VERSION ""

NS_ :

BS_:

BU_: ADSP CH ChassisBus DIPF DIPR ETH FC GTW GTWU HVI HVS ODIN PARTY PartyBus Receiver SDCV SUI UI UIS VEH VIRT VITALS VehicleBus X

BO_ 1013 ID3F5VCFRONT_lighting: 8 VehicleBus
 SG_ VCFRONT_DRLLeftStatus : 36|2@1+ (1,0) [0|3] ""  Receiver
 SG_ VCFRONT_DRLRightStatus : 38|2@1+ (1,0) [0|3] ""  Receiver
 SG_ VCFRONT_ambientLightingBrightnes : 8|8@1+ (0.5,0) [0|127] "%"  Receiver
 SG_ VCFRONT_approachLightingRequest : 25|1@1+ (1,0) [0|1] ""  Receiver
 SG_ VCFRONT_courtesyLightingRequest : 24|1@1+ (1,0) [0|1] ""  Receiver
 SG_ VCFRONT_fogLeftStatus : 40|2@1+ (1,0) [0|3] ""  Receiver
 SG_ VCFRONT_fogRightStatus : 42|2@1+ (1,0) [0|3] ""  Receiver
 SG_ VCFRONT_hazardLightRequest : 4|4@1+ (1,0) [0|8] ""  Receiver
 SG_ VCFRONT_hazardSwitchBacklight : 27|1@1+ (1,0) [0|1] ""  Receiver
 SG_ VCFRONT_highBeamLeftStatus : 32|2@1+ (1,0) [0|3] ""  Receiver
 SG_ VCFRONT_highBeamRightStatus : 34|2@1+ (1,0) [0|3] ""  Receiver
 SG_ VCFRONT_highBeamSwitchActive : 58|1@1+ (1,0) [0|1] ""  Receiver
 SG_ VCFRONT_indicatorLeftRequest : 0|2@1+ (1,0) [0|2] ""  Receiver
 SG_ VCFRONT_indicatorRightRequest : 2|2@1+ (1,0) [0|2] ""  Receiver
 SG_ VCFRONT_lowBeamLeftStatus : 28|2@1+ (1,0) [0|3] ""  Receiver
 SG_ VCFRONT_lowBeamRightStatus : 30|2@1+ (1,0) [0|3] ""  Receiver
 SG_ VCFRONT_lowBeamsCalibrated : 62|1@1+ (1,0) [0|1] ""  Receiver
 SG_ VCFRONT_lowBeamsOnForDRL : 61|1@1+ (1,0) [0|1] ""  Receiver
 SG_ VCFRONT_parkLeftStatus : 54|2@1+ (1,0) [0|3] ""  Receiver
 SG_ VCFRONT_parkRightStatus : 56|2@1+ (1,0) [0|3] ""  Receiver
 SG_ VCFRONT_seeYouHomeLightingReq : 26|1@1+ (1,0) [0|1] ""  Receiver
 SG_ VCFRONT_sideMarkersStatus : 44|2@1+ (1,0) [0|3] ""  Receiver
 SG_ VCFRONT_sideRepeaterLeftStatus : 46|2@1+ (1,0) [0|3] ""  Receiver
 SG_ VCFRONT_sideRepeaterRightStatus : 48|2@1+ (1,0) [0|3] ""  Receiver
 SG_ VCFRONT_simLatchingStalk : 59|2@1+ (1,0) [0|3] ""  Receiver
 SG_ VCFRONT_switchLightingBrightness : 16|8@1+ (0.5,0) [0|127] "%"  Receiver
 SG_ VCFRONT_turnSignalLeftStatus : 50|2@1+ (1,0) [0|3] ""  Receiver
 SG_ VCFRONT_turnSignalRightStatus : 52|2@1+ (1,0) [0|3] ""  Receiver

BO_ 1014 VCFRONT_lightStatus: 5 GTW
 SG_ VCFRONT_turnSignalLeftStatus : 22|2@1+ (1,0) [0|3] "" ODIN,UI
 SG_ VCFRONT_turnSignalRightStatus : 24|2@1+ (1,0) [0|3] "" ODIN,UI

BO_ 1016 ID3F8UI_driverAssistControl: 8 ChassisBus
 SG_ UI_accFollowDistanceSetting : 45|3@1+ (1,0) [0|7] ""  Receiver
 SG_ UI_adaptiveSetSpeedEnable : 39|1@1+ (1,0) [0|1] ""  Receiver
 SG_ UI_alcOffHighwayEnable : 56|1@1+ (1,0) [0|1] ""  Receiver
 SG_ UI_autoSummonEnable : 10|1@1+ (1,0) [0|1] ""  Receiver
 SG_ UI_autopilotControlRequest : 0|1@1+ (1,0) [0|1] ""  Receiver
 SG_ UI_coastToCoast : 9|1@1+ (1,0) [0|1] ""  Receiver
 SG_ UI_curvSpeedAdaptDisable : 4|1@1+ (1,0) [0|1] ""  Receiver
 SG_ UI_curvatureDatabaseOnly : 22|1@1+ (1,0) [0|1] ""  Receiver
 SG_ UI_dasDeveloper : 5|1@1+ (1,0) [0|1] ""  Receiver
 SG_ UI_driveOnMapsEnable : 13|1@1+ (1,0) [0|1] ""  Receiver
 SG_ UI_drivingSide : 40|2@1+ (1,0) [0|2] ""  Receiver
 SG_ UI_enableBrakeLightPulse : 63|1@1+ (1,0) [0|1] ""  Receiver
 SG_ UI_enableClipTelemetry : 42|1@1+ (1,0) [0|1] ""  Receiver
 SG_ UI_enableRoadSegmentTelemetry : 44|1@1+ (1,0) [0|1] ""  Receiver
 SG_ UI_enableTripTelemetry : 43|1@1+ (1,0) [0|1] ""  Receiver
 SG_ UI_enableVinAssociation : 6|1@1+ (1,0) [0|1] ""  Receiver
 SG_ UI_enableVisionOnlyStops : 60|1@1+ (1,0) [0|1] ""  Receiver
 SG_ UI_exceptionListEnable : 11|1@1+ (1,0) [0|1] ""  Receiver
 SG_ UI_followNavRouteEnable : 49|1@1+ (1,0) [0|1] ""  Receiver
 SG_ UI_fuseHPPDisable : 17|1@1+ (1,0) [0|1] ""  Receiver
 SG_ UI_fuseLanesDisable : 16|1@1+ (1,0) [0|1] ""  Receiver
 SG_ UI_fuseVehiclesDisable : 18|1@1+ (1,0) [0|1] ""  Receiver
 SG_ UI_handsOnRequirementDisable : 14|1@1+ (1,0) [0|1] ""  Receiver
 SG_ UI_hasDriveOnNav : 48|1@1+ (1,0) [0|1] ""  Receiver
 SG_ UI_lssElkEnabled : 23|1@1+ (1,0) [0|1] ""  Receiver
 SG_ UI_lssLdwEnabled : 8|1@1+ (1,0) [0|1] ""  Receiver
 SG_ UI_lssLkaEnabled : 7|1@1+ (1,0) [0|1] ""  Receiver
 SG_ UI_roadCheckDisable : 12|1@1+ (1,0) [0|1] ""  Receiver
 SG_ UI_selfParkRequest : 28|4@1+ (1,0) [0|15] ""  Receiver
 SG_ UI_smartSummonType : 58|2@1+ (1,0) [0|2] ""  Receiver
 SG_ UI_source3D : 61|2@1+ (1,0) [0|2] ""  Receiver
 SG_ UI_summonEntryType : 26|2@1+ (1,0) [0|3] ""  Receiver
 SG_ UI_summonExitType : 24|2@1+ (1,0) [0|3] ""  Receiver
 SG_ UI_summonHeartbeat : 2|2@1+ (1,0) [0|3] ""  Receiver
 SG_ UI_summonReverseDist : 32|6@1+ (1,0) [0|63] ""  Receiver
 SG_ UI_ulcBlindSpotConfig : 52|2@1+ (1,0) [0|2] ""  Receiver
 SG_ UI_ulcOffHighway : 15|1@1+ (1,0) [0|1] ""  Receiver
 SG_ UI_ulcSpeedConfig : 50|2@1+ (1,0) [0|3] ""  Receiver
 SG_ UI_ulcStalkConfirm : 1|1@1+ (1,0) [0|1] ""  Receiver
 SG_ UI_undertakeAssistEnable : 38|1@1+ (1,0) [0|1] ""  Receiver
 SG_ UI_validationLoop : 57|1@1+ (1,0) [0|1] ""  Receiver
 SG_ UI_visionSpeedType : 20|2@1+ (1,0) [0|3] ""  Receiver

BO_ 1017 VCSEC_alertMatrix: 8 VEH
 SG_ VCSEC_matrixIndex M: 0|4@1+ (1,0) [0|0] "" X
 SG_ VCSEC_a001_WatchdogReset m0: 4|1@1+ (1,0) [0|0] "" X
 SG_ VCSEC_a002_PowerLossReset m0: 5|1@1+ (1,0) [0|0] "" X
 SG_ VCSEC_a003_SWAssertion m0: 6|1@1+ (1,0) [0|0] "" X
 SG_ VCSEC_a010_ExtSupplyVoltError m0: 13|1@1+ (1,0) [0|0] "" X
 SG_ VCSEC_a012_CPUReset m0: 15|1@1+ (1,0) [0|0] "" X
 SG_ VCSEC_a013_AlertManagerFault m0: 16|1@1+ (1,0) [0|0] "" X
 SG_ VCSEC_a015_NVMMAlert m0: 18|1@1+ (1,0) [0|0] "" X
 SG_ VCSEC_a021_TaskSchedulerError m0: 24|1@1+ (1,0) [0|0] "" X
 SG_ VCSEC_a022_TaskInitError m0: 25|1@1+ (1,0) [0|0] "" X
 SG_ VCSEC_a031_UDSActive m0: 34|1@1+ (1,0) [0|0] "" X
 SG_ VCSEC_a041_HighCPULoad m0: 44|1@1+ (1,0) [0|0] "" X
 SG_ VCSEC_a042_HighStackUsage m0: 45|1@1+ (1,0) [0|0] "" X
 SG_ VCSEC_a043_Task1msError m0: 46|1@1+ (1,0) [0|0] "" X
 SG_ VCSEC_a044_Task10msError m0: 47|1@1+ (1,0) [0|0] "" X
 SG_ VCSEC_a045_Task100msError m0: 48|1@1+ (1,0) [0|0] "" X
 SG_ VCSEC_a046_Task1000msError m0: 49|1@1+ (1,0) [0|0] "" X
 SG_ VCSEC_a059_inputResistanceHigh m0: 62|1@1+ (1,0) [0|0] "" X
 SG_ VCSEC_a060_engineeringBuild m0: 63|1@1+ (1,0) [0|0] "" X
 SG_ VCSEC_a061_XCPConnected m1: 4|1@1+ (1,0) [0|0] "" X
 SG_ VCSEC_a062_XCPWasConnected m1: 5|1@1+ (1,0) [0|0] "" X
 SG_ VCSEC_a063_SwitchFault m1: 6|1@1+ (1,0) [0|0] "" X
 SG_ VCSEC_a064_busSleepReqTimeout m1: 7|1@1+ (1,0) [0|0] "" X
 SG_ VCSEC_a097_CMP_MIA m1: 40|1@1+ (1,0) [0|0] "" X
 SG_ VCSEC_a098_DI_THERMAL_MIA m1: 41|1@1+ (1,0) [0|0] "" X
 SG_ VCSEC_a099_PARK_MIA m1: 42|1@1+ (1,0) [0|0] "" X
 SG_ VCSEC_a100_CANbus_MIA m1: 43|1@1+ (1,0) [0|0] "" X
 SG_ VCSEC_a101_PM_MIA m1: 44|1@1+ (1,0) [0|0] "" X
 SG_ VCSEC_a102_PTC_MIA m1: 45|1@1+ (1,0) [0|0] "" X
 SG_ VCSEC_a103_CP_MIA m1: 46|1@1+ (1,0) [0|0] "" X
 SG_ VCSEC_a104_DAS_MIA m1: 47|1@1+ (1,0) [0|0] "" X
 SG_ VCSEC_a105_TAS_MIA m1: 48|1@1+ (1,0) [0|0] "" X
 SG_ VCSEC_a106_PCS_MIA m1: 49|1@1+ (1,0) [0|0] "" X
 SG_ VCSEC_a107_BMS_MIA m1: 50|1@1+ (1,0) [0|0] "" X
 SG_ VCSEC_a108_DIS_MIA m1: 51|1@1+ (1,0) [0|0] "" X
 SG_ VCSEC_a109_RCM_MIA m1: 52|1@1+ (1,0) [0|0] "" X
 SG_ VCSEC_a110_GTW_MIA m1: 53|1@1+ (1,0) [0|0] "" X
 SG_ VCSEC_a111_EPBR_MIA m1: 54|1@1+ (1,0) [0|0] "" X
 SG_ VCSEC_a112_EPBL_MIA m1: 55|1@1+ (1,0) [0|0] "" X
 SG_ VCSEC_a113_UI_MIA m1: 56|1@1+ (1,0) [0|0] "" X
 SG_ VCSEC_a114_ESP_MIA m1: 57|1@1+ (1,0) [0|0] "" X
 SG_ VCSEC_a115_VCSEC_MIA m1: 58|1@1+ (1,0) [0|0] "" X
 SG_ VCSEC_a116_VCRIGHT_MIA m1: 59|1@1+ (1,0) [0|0] "" X
 SG_ VCSEC_a117_VCLEFT_MIA m1: 60|1@1+ (1,0) [0|0] "" X
 SG_ VCSEC_a118_VCFRONT_MIA m1: 61|1@1+ (1,0) [0|0] "" X
 SG_ VCSEC_a119_SCCM_MIA m1: 62|1@1+ (1,0) [0|0] "" X
 SG_ VCSEC_a120_DI_DRIVE_MIA m1: 63|1@1+ (1,0) [0|0] "" X
 SG_ VCSEC_a133_alarmTriggered m2: 16|1@1+ (1,0) [0|0] "" X
 SG_ VCSEC_a134_badCertificate m2: 17|1@1+ (1,0) [0|0] "" X
 SG_ VCSEC_a135_centerEndpointMIA m2: 18|1@1+ (1,0) [0|0] "" X
 SG_ VCSEC_a136_leftEndpointMIA m2: 19|1@1+ (1,0) [0|0] "" X
 SG_ VCSEC_a137_rightEndpointMIA m2: 20|1@1+ (1,0) [0|0] "" X
 SG_ VCSEC_a138_rearEndpointMIA m2: 21|1@1+ (1,0) [0|0] "" X
 SG_ VCSEC_a140_nfcAuthentication m2: 23|1@1+ (1,0) [0|0] "" X
 SG_ VCSEC_a141_tooFewKeysOnWhitelist m2: 24|1@1+ (1,0) [0|0] "" X
 SG_ VCSEC_a142_bleGattAlertC m2: 25|1@1+ (1,0) [0|0] "" X
 SG_ VCSEC_a143_bleGattAlertL m2: 26|1@1+ (1,0) [0|0] "" X
 SG_ VCSEC_a144_bleGattAlertR m2: 27|1@1+ (1,0) [0|0] "" X
 SG_ VCSEC_a145_bleGattAlertRe m2: 28|1@1+ (1,0) [0|0] "" X
 SG_ VCSEC_a147_protobufRXTimeout m2: 30|1@1+ (1,0) [0|0] "" X
 SG_ VCSEC_a148_keyWhitelistFull m2: 31|1@1+ (1,0) [0|0] "" X
 SG_ VCSEC_a149_attrsWentMissingL m2: 32|1@1+ (1,0) [0|0] "" X
 SG_ VCSEC_a150_attrsWentMissingR m2: 33|1@1+ (1,0) [0|0] "" X
 SG_ VCSEC_a151_attrsWentMissingRe m2: 34|1@1+ (1,0) [0|0] "" X
 SG_ VCSEC_a153_srvcCmdTimeoutC m2: 36|1@1+ (1,0) [0|0] "" X
 SG_ VCSEC_a154_srvcCmdTimeoutL m2: 37|1@1+ (1,0) [0|0] "" X
 SG_ VCSEC_a155_srvcCmdTimeoutR m2: 38|1@1+ (1,0) [0|0] "" X
 SG_ VCSEC_a156_srvcCmdTimeoutRe m2: 39|1@1+ (1,0) [0|0] "" X
 SG_ VCSEC_a158_hciFaultC m2: 41|1@1+ (1,0) [0|0] "" X
 SG_ VCSEC_a159_hciFaultL m2: 42|1@1+ (1,0) [0|0] "" X
 SG_ VCSEC_a161_hciFaultR m2: 44|1@1+ (1,0) [0|0] "" X
 SG_ VCSEC_a162_hciFaultRe m2: 45|1@1+ (1,0) [0|0] "" X
 SG_ VCSEC_a164_attrsWentMissingC m2: 47|1@1+ (1,0) [0|0] "" X
 SG_ VCSEC_a165_ephemeralKeyGenerated m2: 48|1@1+ (1,0) [0|0] "" X
 SG_ VCSEC_a166_BLECenterPowerCycled m2: 49|1@1+ (1,0) [0|0] "" X
 SG_ VCSEC_a167_BLECenterSoftReset m2: 50|1@1+ (1,0) [0|0] "" X
 SG_ VCSEC_a168_BLELeftSoftReset m2: 51|1@1+ (1,0) [0|0] "" X
 SG_ VCSEC_a169_BLERightSoftReset m2: 52|1@1+ (1,0) [0|0] "" X
 SG_ VCSEC_a170_BLERearSoftReset m2: 53|1@1+ (1,0) [0|0] "" X
 SG_ VCSEC_a172_BLEUnexpectedResetC m2: 55|1@1+ (1,0) [0|0] "" X
 SG_ VCSEC_a173_BLEUnexpectedResetL m2: 56|1@1+ (1,0) [0|0] "" X
 SG_ VCSEC_a174_BLEUnexpectedResetRi m2: 57|1@1+ (1,0) [0|0] "" X
 SG_ VCSEC_a175_BLEUnexpectedResetRe m2: 58|1@1+ (1,0) [0|0] "" X
 SG_ VCSEC_a177_whitelistAddedKey m2: 60|1@1+ (1,0) [0|0] "" X
 SG_ VCSEC_a178_whitelistRemovedKey m2: 61|1@1+ (1,0) [0|0] "" X
 SG_ VCSEC_a179_wlistAddedPermission m2: 62|1@1+ (1,0) [0|0] "" X
 SG_ VCSEC_a180_wlistRemovedPermission m2: 63|1@1+ (1,0) [0|0] "" X
 SG_ VCSEC_a181_signedMessageFault m3: 4|1@1+ (1,0) [0|0] "" X
 SG_ VCSEC_a182_cryptoHighStackUsage m3: 5|1@1+ (1,0) [0|0] "" X
 SG_ VCSEC_a183_centerEndpointRFMia m3: 6|1@1+ (1,0) [0|0] "" X
 SG_ VCSEC_a184_driverEndpointRFMia m3: 7|1@1+ (1,0) [0|0] "" X
 SG_ VCSEC_a185_passengerEndpointRFMia m3: 8|1@1+ (1,0) [0|0] "" X
 SG_ VCSEC_a186_rearEndpointRFMia m3: 9|1@1+ (1,0) [0|0] "" X
 SG_ VCSEC_a187_badConnectionDropped m3: 10|1@1+ (1,0) [0|0] "" X
 SG_ VCSEC_a188_protobufDecodeError m3: 11|1@1+ (1,0) [0|0] "" X
 SG_ VCSEC_a189_protoExpLengthTooLarge m3: 12|1@1+ (1,0) [0|0] "" X
 SG_ VCSEC_a190_protoTooManyBytes m3: 13|1@1+ (1,0) [0|0] "" X
 SG_ VCSEC_a191_macIDWlistingFailedC m3: 14|1@1+ (1,0) [0|0] "" X
 SG_ VCSEC_a192_macIDWlistingFailedL m3: 15|1@1+ (1,0) [0|0] "" X
 SG_ VCSEC_a193_macIDWlistingFailedRi m3: 16|1@1+ (1,0) [0|0] "" X
 SG_ VCSEC_a194_macIDWlistingFailedRe m3: 17|1@1+ (1,0) [0|0] "" X
 SG_ VCSEC_a195_keyMissingInDrive m3: 18|1@1+ (1,0) [0|0] "" X
 SG_ VCSEC_a196_protobufTXTimeout m3: 19|1@1+ (1,0) [0|0] "" X
 SG_ VCSEC_a197_indicationFault m3: 20|1@1+ (1,0) [0|0] "" X
 SG_ VCSEC_a198_BPillarNFCReaderMIA m3: 21|1@1+ (1,0) [0|0] "" X
 SG_ VCSEC_a199_CenterNFCReaderMIA m3: 22|1@1+ (1,0) [0|0] "" X
 SG_ VCSEC_a200_centerEndpointLostComm m3: 23|1@1+ (1,0) [0|0] "" X
 SG_ VCSEC_a201_leftEndpointLostComm m3: 24|1@1+ (1,0) [0|0] "" X
 SG_ VCSEC_a202_rightEndpointLostComm m3: 25|1@1+ (1,0) [0|0] "" X
 SG_ VCSEC_a203_rearEndpointLostComm m3: 26|1@1+ (1,0) [0|0] "" X
 SG_ VCSEC_a204_SharedSecretsWritten m3: 27|1@1+ (1,0) [0|0] "" X
 SG_ VCSEC_a205_MTUUpdateNotConfirmed m3: 28|1@1+ (1,0) [0|0] "" X
 SG_ VCSEC_a206_BLELeftAssertFailure m3: 29|1@1+ (1,0) [0|0] "" X
 SG_ VCSEC_a207_BLERightAssertFailure m3: 30|1@1+ (1,0) [0|0] "" X
 SG_ VCSEC_a208_BLERearAssertFailure m3: 31|1@1+ (1,0) [0|0] "" X
 SG_ VCSEC_a209_BLECenterAssertFailure m3: 32|1@1+ (1,0) [0|0] "" X

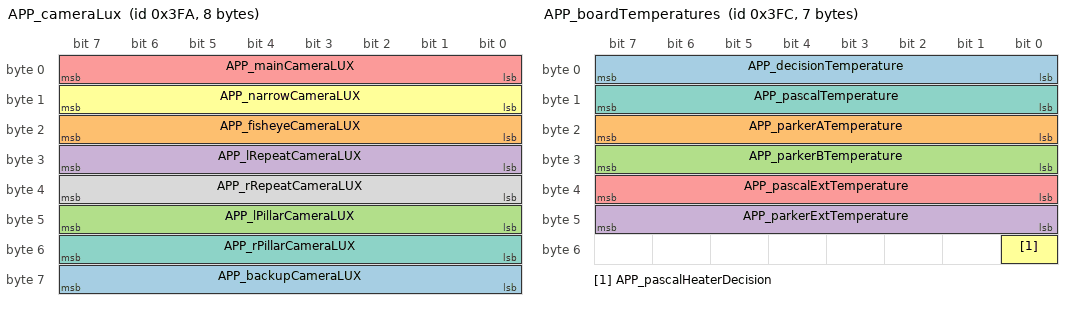
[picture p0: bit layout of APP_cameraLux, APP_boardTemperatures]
BO_ 1018 APP_cameraLux: 8 CH
 SG_ APP_backupCameraLUX: 56|8@1+ (50,0) [0|0] "lux" X
 SG_ APP_fisheyeCameraLUX: 16|8@1+ (50,0) [0|0] "lux" X
 SG_ APP_lPillarCameraLUX: 40|8@1+ (50,0) [0|0] "lux" X
 SG_ APP_lRepeatCameraLUX: 24|8@1+ (50,0) [0|0] "lux" X
 SG_ APP_mainCameraLUX: 0|8@1+ (50,0) [0|0] "lux" X
 SG_ APP_narrowCameraLUX: 8|8@1+ (50,0) [0|0] "lux" X
 SG_ APP_rPillarCameraLUX: 48|8@1+ (50,0) [0|0] "lux" X
 SG_ APP_rRepeatCameraLUX: 32|8@1+ (50,0) [0|0] "lux" X

BO_ 1020 APP_boardTemperatures: 7 CH
 SG_ APP_decisionTemperature: 0|8@1+ (1,-128) [0|0] "C" X
 SG_ APP_parkerATemperature: 16|8@1+ (1,-128) [0|0] "C" X
 SG_ APP_parkerBTemperature: 24|8@1+ (1,-128) [0|0] "C" X
 SG_ APP_parkerExtTemperature: 40|8@1+ (1,-128) [0|0] "C" X
 SG_ APP_pascalExtTemperature: 32|8@1+ (1,-128) [0|0] "C" X
 SG_ APP_pascalHeaterDecision: 48|1@1+ (1,0) [0|0] "" X
 SG_ APP_pascalTemperature: 8|8@1+ (1,-128) [0|0] "C" X

BO_ 1021 ID3FDUI_autopilotControl: 8 ChassisBus
 SG_ UI_autopilotControlIndex M : 0|3@1+ (1,0) [0|7] ""  Receiver
 SG_ UI_apmv3Branch m1 : 40|3@1+ (1,0) [0|5] ""  Receiver
 SG_ UI_applyEceR79 m1 : 19|1@1+ (1,0) [0|1] ""  Receiver
 SG_ UI_blindspotDistance m0 : 15|3@1+ (1,0) [0|5] ""  Receiver
 SG_ UI_blindspotMinSpeed m0 : 11|4@1+ (1,0) [0|10] ""  Receiver
 SG_ UI_blindspotTTC m0 : 18|3@1+ (1,0) [0|7] ""  Receiver
 SG_ UI_disableBackup m1 : 30|1@1+ (1,0) [0|1] ""  Receiver
 SG_ UI_disableFisheye m1 : 25|1@1+ (1,0) [0|1] ""  Receiver
 SG_ UI_disableLeftPillar m1 : 26|1@1+ (1,0) [0|1] ""  Receiver
 SG_ UI_disableLeftRepeater m1 : 28|1@1+ (1,0) [0|1] ""  Receiver
 SG_ UI_disableMain m1 : 23|1@1+ (1,0) [0|1] ""  Receiver
 SG_ UI_disableNarrow m1 : 24|1@1+ (1,0) [0|1] ""  Receiver
 SG_ UI_disableRadar m1 : 31|1@1+ (1,0) [0|1] ""  Receiver
 SG_ UI_disableRightPillar m1 : 27|1@1+ (1,0) [0|1] ""  Receiver
 SG_ UI_disableRightRepeater m1 : 29|1@1+ (1,0) [0|1] ""  Receiver
 SG_ UI_donAlcProgGoreAbortThres m0 : 29|4@1+ (1,0) [0|9] ""  Receiver
 SG_ UI_donDisableAutoWiperDuration m0 : 4|3@1+ (1,0) [0|6] ""  Receiver
 SG_ UI_donDisableCutin m0 : 24|1@1+ (1,0) [0|1] ""  Receiver
 SG_ UI_donDisableOnAutoWiperSpeed m0 : 7|4@1+ (1,0) [0|15] ""  Receiver
 SG_ UI_donMinGoreWidthForAbortMap m0 : 25|4@1+ (1,0) [0|11] ""  Receiver
 SG_ UI_donMinGoreWidthForAbortNotMap m0 : 33|4@1+ (1,0) [0|11] ""  Receiver
 SG_ UI_donStopEndOfRampBuffer m0 : 21|3@1+ (1,0) [0|4] ""  Receiver
 SG_ UI_driverMonitorConfirmation m1 : 17|1@1+ (1,0) [0|1] ""  Receiver
 SG_ UI_enableAutopilotStopWarning m1 : 44|1@1+ (1,0) [0|1] ""  Receiver
 SG_ UI_enableCabinCamera m1 : 43|1@1+ (1,0) [0|1] ""  Receiver
 SG_ UI_enableCabinCameraTelemetry m1 : 48|1@1+ (1,0) [0|1] ""  Receiver
 SG_ UI_enableMapStops m1 : 20|1@1+ (1,0) [0|1] ""  Receiver
 SG_ UI_factorySummonEnable m1 : 39|1@1+ (1,0) [0|1] ""  Receiver
 SG_ UI_fsdStopsControlEnabled m0 : 38|1@1+ (1,0) [0|1] ""  Receiver
 SG_ UI_fsdVisualizationEnabled m0 : 37|1@1+ (1,0) [0|1] ""  Receiver
 SG_ UI_hardCoreSummon m1 : 47|1@1+ (1,0) [0|1] ""  Receiver
 SG_ UI_homelinkNearby m0 : 45|1@1+ (1,0) [0|1] ""  Receiver
 SG_ UI_hovEnabled m0 : 3|1@1+ (1,0) [0|1] ""  Receiver
 SG_ UI_noStalkConfirmAlertChime m1 : 37|1@1+ (1,0) [0|1] ""  Receiver
 SG_ UI_noStalkConfirmAlertHaptic m1 : 32|1@1+ (1,0) [0|1] ""  Receiver
 SG_ UI_showLaneGraph m1 : 45|1@1+ (1,0) [0|1] ""  Receiver
 SG_ UI_showTrackLabels m1 : 46|1@1+ (1,0) [0|1] ""  Receiver
 SG_ UI_ulcSnooze m1 : 36|1@1+ (1,0) [0|1] ""  Receiver

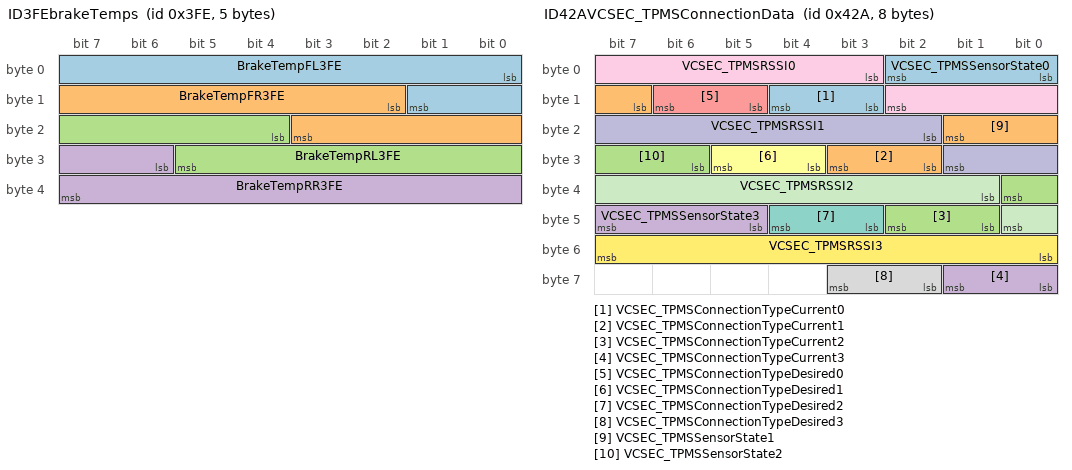
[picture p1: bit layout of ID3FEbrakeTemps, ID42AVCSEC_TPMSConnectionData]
BO_ 1022 ID3FEbrakeTemps: 5 VehicleBus
 SG_ BrakeTempFL3FE : 0|10@1+ (1,-40) [0|0] "C"  Receiver
 SG_ BrakeTempFR3FE : 10|10@1+ (1,-40) [0|0] "C"  Receiver
 SG_ BrakeTempRL3FE : 20|10@1+ (1,-40) [0|0] "C"  Receiver
 SG_ BrakeTempRR3FE : 30|10@1+ (1,-40) [0|0] "C"  Receiver

BO_ 1025 ID401BrickVoltages: 8 VehicleBus
 SG_ MultiplexSelector M : 0|8@1+ (1,0) [0|0] ""  Receiver
 SG_ StatusFlags : 8|8@1+ (1,0) [0|0] ""  Receiver
 SG_ Brick0 m0 : 16|16@1+ (0.0001,0) [0|0] "V"  Receiver
 SG_ Brick1 m0 : 32|16@1+ (0.0001,0) [0|0] "V"  Receiver
 SG_ Brick2 m0 : 48|16@1+ (0.0001,0) [0|0] "V"  Receiver
 SG_ Brick3 m1 : 16|16@1+ (0.0001,0) [0|0] "V"  Receiver
 SG_ Brick4 m1 : 32|16@1+ (0.0001,0) [0|0] "V"  Receiver
 SG_ Brick5 m1 : 48|16@1+ (0.0001,0) [0|0] "V"  Receiver
 SG_ Brick6 m2 : 16|16@1+ (0.0001,0) [0|0] "V"  Receiver
 SG_ Brick7 m2 : 32|16@1+ (0.0001,0) [0|0] "V"  Receiver
 SG_ Brick8 m2 : 48|16@1+ (0.0001,0) [0|0] "V"  Receiver
 SG_ Brick9 m3 : 16|16@1+ (0.0001,0) [0|0] "V"  Receiver
 SG_ Brick10 m3 : 32|16@1+ (0.0001,0) [0|0] "V"  Receiver
 SG_ Brick11 m3 : 48|16@1+ (0.0001,0) [0|0] "V"  Receiver
 SG_ Brick12 m4 : 16|16@1+ (0.0001,0) [0|0] "V"  Receiver
 SG_ Brick13 m4 : 32|16@1+ (0.0001,0) [0|0] "V"  Receiver
 SG_ Brick14 m4 : 48|16@1+ (0.0001,0) [0|0] "V"  Receiver
 SG_ Brick15 m5 : 16|16@1+ (0.0001,0) [0|0] "V"  Receiver
 SG_ Brick16 m5 : 32|16@1+ (0.0001,0) [0|0] "V"  Receiver
 SG_ Brick17 m5 : 48|16@1+ (0.0001,0) [0|0] "V"  Receiver
 SG_ Brick18 m6 : 16|16@1+ (0.0001,0) [0|0] "V"  Receiver
 SG_ Brick19 m6 : 32|16@1+ (0.0001,0) [0|0] "V"  Receiver
 SG_ Brick20 m6 : 48|16@1+ (0.0001,0) [0|0] "V"  Receiver
 SG_ Brick21 m7 : 16|16@1+ (0.0001,0) [0|0] "V"  Receiver
 SG_ Brick22 m7 : 32|16@1+ (0.0001,0) [0|0] "V"  Receiver
 SG_ Brick23 m7 : 48|16@1+ (0.0001,0) [0|0] "V"  Receiver
 SG_ Brick24 m8 : 16|16@1+ (0.0001,0) [0|0] "V"  Receiver
 SG_ Brick25 m8 : 32|16@1+ (0.0001,0) [0|0] "V"  Receiver
 SG_ Brick26 m8 : 48|16@1+ (0.0001,0) [0|0] "V"  Receiver
 SG_ Brick27 m9 : 16|16@1+ (0.0001,0) [0|0] "V"  Receiver
 SG_ Brick28 m9 : 32|16@1+ (0.0001,0) [0|0] "V"  Receiver
 SG_ Brick29 m9 : 48|16@1+ (0.0001,0) [0|0] "V"  Receiver
 SG_ Brick30 m10 : 16|16@1+ (0.0001,0) [0|0] "V"  Receiver
 SG_ Brick31 m10 : 32|16@1+ (0.0001,0) [0|0] "V"  Receiver
 SG_ Brick32 m10 : 48|16@1+ (0.0001,0) [0|0] "V"  Receiver
 SG_ Brick34 m11 : 16|16@1+ (0.0001,0) [0|0] "V"  Receiver
 SG_ Brick33 m11 : 32|16@1+ (0.0001,0) [0|0] "V"  Receiver
 SG_ Brick35 m11 : 48|16@1+ (0.0001,0) [0|0] "V"  Receiver
 SG_ Brick36 m12 : 16|16@1+ (0.0001,0) [0|0] "V"  Receiver
 SG_ Brick37 m12 : 32|16@1+ (0.0001,0) [0|0] "V"  Receiver
 SG_ Brick38 m12 : 48|16@1+ (0.0001,0) [0|0] "V"  Receiver
 SG_ Brick39 m13 : 16|16@1+ (0.0001,0) [0|0] "V"  Receiver
 SG_ Brick40 m13 : 32|16@1+ (0.0001,0) [0|0] "V"  Receiver
 SG_ Brick41 m13 : 48|16@1+ (0.0001,0) [0|0] "V"  Receiver
 SG_ Brick42 m14 : 16|16@1+ (0.0001,0) [0|0] "V"  Receiver
 SG_ Brick43 m14 : 32|16@1+ (0.0001,0) [0|0] "V"  Receiver
 SG_ Brick44 m14 : 48|16@1+ (0.0001,0) [0|0] "V"  Receiver
 SG_ Brick45 m15 : 16|16@1+ (0.0001,0) [0|0] "V"  Receiver
 SG_ Brick46 m15 : 32|16@1+ (0.0001,0) [0|0] "V"  Receiver
 SG_ Brick47 m15 : 48|16@1+ (0.0001,0) [0|0] "V"  Receiver
 SG_ Brick48 m16 : 16|16@1+ (0.0001,0) [0|0] "V"  Receiver
 SG_ Brick49 m16 : 32|16@1+ (0.0001,0) [0|0] "V"  Receiver
 SG_ Brick50 m16 : 48|16@1+ (0.0001,0) [0|0] "V"  Receiver
 SG_ Brick51 m17 : 16|16@1+ (0.0001,0) [0|0] "V"  Receiver
 SG_ Brick52 m17 : 32|16@1+ (0.0001,0) [0|0] "V"  Receiver
 SG_ Brick53 m17 : 48|16@1+ (0.0001,0) [0|0] "V"  Receiver
 SG_ Brick54 m18 : 16|16@1+ (0.0001,0) [0|0] "V"  Receiver
 SG_ Brick55 m18 : 32|16@1+ (0.0001,0) [0|0] "V"  Receiver
 SG_ Brick56 m18 : 48|16@1+ (0.0001,0) [0|0] "V"  Receiver
 SG_ Brick57 m19 : 16|16@1+ (0.0001,0) [0|0] "V"  Receiver
 SG_ Brick58 m19 : 32|16@1+ (0.0001,0) [0|0] "V"  Receiver
 SG_ Brick59 m19 : 48|16@1+ (0.0001,0) [0|0] "V"  Receiver
 SG_ Brick60 m20 : 16|16@1+ (0.0001,0) [0|0] "V"  Receiver
 SG_ Brick61 m20 : 32|16@1+ (0.0001,0) [0|0] "V"  Receiver
 SG_ Brick62 m20 : 48|16@1+ (0.0001,0) [0|0] "V"  Receiver
 SG_ Brick63 m21 : 16|16@1+ (0.0001,0) [0|0] "V"  Receiver
 SG_ Brick64 m21 : 32|16@1+ (0.0001,0) [0|0] "V"  Receiver
 SG_ Brick65 m21 : 48|16@1+ (0.0001,0) [0|0] "V"  Receiver
 SG_ Brick66 m22 : 16|16@1+ (0.0001,0) [0|0] "V"  Receiver
 SG_ Brick67 m22 : 32|16@1+ (0.0001,0) [0|0] "V"  Receiver
 SG_ Brick68 m22 : 48|16@1+ (0.0001,0) [0|0] "V"  Receiver
 SG_ Brick69 m23 : 16|16@1+ (0.0001,0) [0|0] "V"  Receiver
 SG_ Brick70 m23 : 32|16@1+ (0.0001,0) [0|0] "V"  Receiver
 SG_ Brick71 m23 : 48|16@1+ (0.0001,0) [0|0] "V"  Receiver
 SG_ Brick72 m24 : 16|16@1+ (0.0001,0) [0|0] "V"  Receiver
 SG_ Brick73 m24 : 32|16@1+ (0.0001,0) [0|0] "V"  Receiver
 SG_ Brick74 m24 : 48|16@1+ (0.0001,0) [0|0] "V"  Receiver
 SG_ Brick75 m25 : 16|16@1+ (0.0001,0) [0|0] "V"  Receiver
 SG_ Brick76 m25 : 32|16@1+ (0.0001,0) [0|0] "V"  Receiver
 SG_ Brick77 m25 : 48|16@1+ (0.0001,0) [0|0] "V"  Receiver
 SG_ Brick78 m26 : 16|16@1+ (0.0001,0) [0|0] "V"  Receiver
 SG_ Brick79 m26 : 32|16@1+ (0.0001,0) [0|0] "V"  Receiver
 SG_ Brick80 m26 : 48|16@1+ (0.0001,0) [0|0] "V"  Receiver
 SG_ Brick81 m27 : 16|16@1+ (0.0001,0) [0|0] "V"  Receiver
 SG_ Brick82 m27 : 32|16@1+ (0.0001,0) [0|0] "V"  Receiver
 SG_ Brick83 m27 : 48|16@1+ (0.0001,0) [0|0] "V"  Receiver
 SG_ Brick84 m28 : 16|16@1+ (0.0001,0) [0|0] "V"  Receiver
 SG_ Brick85 m28 : 32|16@1+ (0.0001,0) [0|0] "V"  Receiver
 SG_ Brick86 m28 : 48|16@1+ (0.0001,0) [0|0] "V"  Receiver
 SG_ Brick87 m29 : 16|16@1+ (0.0001,0) [0|0] "V"  Receiver
 SG_ Brick88 m29 : 32|16@1+ (0.0001,0) [0|0] "V"  Receiver
 SG_ Brick89 m29 : 48|16@1+ (0.0001,0) [0|0] "V"  Receiver
 SG_ Brick90 m30 : 16|16@1+ (0.0001,0) [0|0] "V"  Receiver
 SG_ Brick91 m30 : 32|16@1+ (0.0001,0) [0|0] "V"  Receiver
 SG_ Brick92 m30 : 48|16@1+ (0.0001,0) [0|0] "V"  Receiver
 SG_ Brick93 m31 : 16|16@1+ (0.0001,0) [0|0] "V"  Receiver
 SG_ Brick94 m31 : 32|16@1+ (0.0001,0) [0|0] "V"  Receiver
 SG_ Brick95 m31 : 48|16@1+ (0.0001,0) [0|0] "V"  Receiver
 SG_ Brick96 m32 : 16|16@1+ (0.0001,0) [0|0] "V"  Receiver
 SG_ Brick97 m32 : 32|16@1+ (0.0001,0) [0|0] "V"  Receiver
 SG_ Brick98 m32 : 48|16@1+ (0.0001,0) [0|0] "V"  Receiver
 SG_ Brick99 m33 : 16|16@1+ (0.0001,0) [0|0] "V"  Receiver
 SG_ Brick100 m33 : 32|16@1+ (0.0001,0) [0|0] "V"  Receiver
 SG_ Brick101 m33 : 48|16@1+ (0.0001,0) [0|0] "V"  Receiver
 SG_ Brick102 m34 : 16|16@1+ (0.0001,0) [0|0] "V"  Receiver
 SG_ Brick103 m34 : 32|16@1+ (0.0001,0) [0|0] "V"  Receiver
 SG_ Brick104 m34 : 48|16@1+ (0.0001,0) [0|0] "V"  Receiver
 SG_ Brick105 m35 : 16|16@1+ (0.0001,0) [0|0] "V"  Receiver
 SG_ Brick106 m35 : 32|16@1+ (0.0001,0) [0|0] "V"  Receiver
 SG_ Brick107 m35 : 48|16@1+ (0.0001,0) [0|0] "V"  Receiver
 SG_ Brick108 m36 : 16|16@1+ (0.0001,0) [0|0] "V"  Receiver
 SG_ Brick109 m36 : 32|16@1+ (0.0001,0) [0|0] "V"  Receiver
 SG_ Brick110 m36 : 48|16@1+ (0.0001,0) [0|0] "V"  Receiver

BO_ 1029 ID405VIN: 8 VehicleBus
 SG_ VINB405 m17 : 8|56@1+ (1,0) [0|7.20576E+016] ""  Receiver
 SG_ VINC405 m18 : 8|56@1+ (1,0) [0|7.20576E+016] ""  Receiver
 SG_ VINA405 m16 : 8|56@1+ (1,0) [0|7.20576E+016] ""  Receiver
 SG_ mux405 M : 0|8@1+ (1,0) [0|255] ""  Receiver

BO_ 1040 APP_cameraStatus: 1 CH
 SG_ APP_backupCameraFeedGood: 0|1@1+ (1,0) [0|0] "" X
 SG_ APP_backupCameraFrameRate: 1|6@1+ (1,0) [0|0] "" X

BO_ 1056 UIS_log: 8 UIS
 SG_ UIS_amdSocPkgPower : 32|32@1+ (1,0) [0|4294967295] "" GTW,ODIN
 SG_ UIS_logMux : 0|32@1+ (1,0) [0|247] "" XXX
 SG_ UIS_odinAuthCount : 32|32@1+ (1,0) [0|4294967295] "" GTW
 SG_ UIS_odinAuthFailCount : 32|32@1+ (1,0) [0|4294967295] "" GTW
 SG_ UIS_odinCPUUsage : 32|32@1+ (1,0) [0|4294967295] "" GTW
 SG_ UIS_odinGatewayConnectionState : 32|32@1+ (1,0) [0|2] "" GTW
 SG_ UIS_odinHermesConnectionState : 32|32@1+ (1,0) [0|3] "" GTW
 SG_ UIS_odinListTasksCmdDurationMs : 32|32@1+ (1,0) [0|4294967295] "" GTW
 SG_ UIS_odinListTasksCmdResult : 32|32@1+ (1,0) [0|2] "" GTW
 SG_ UIS_odinMemUsage : 32|32@1+ (1,0) [0|4294967295] "" GTW
 SG_ UIS_odinNetworkFailCount : 32|32@1+ (1,0) [0|4294967295] "" GTW
 SG_ UIS_odinNetworkStartCount : 32|32@1+ (1,0) [0|4294967295] "" GTW
 SG_ UIS_odinOrchestratorFailCount : 32|32@1+ (1,0) [0|4294967295] "" GTW
 SG_ UIS_odinOrchestratorStartCount : 32|32@1+ (1,0) [0|4294967295] "" GTW
 SG_ UIS_odinProcessState : 32|32@1+ (1,0) [0|4] "" GTW
 SG_ UIS_odinStatusCmdDurationMs : 32|32@1+ (1,0) [0|4294967295] "" GTW
 SG_ UIS_odinStatusCmdResult : 32|32@1+ (1,0) [0|2] "" GTW
 SG_ UIS_odincefCPUUsage : 32|32@1+ (1,0) [0|4294967295] "" GTW
 SG_ UIS_odincefMemUsage : 32|32@1+ (1,0) [0|4294967295] "" GTW

BO_ 1064 UI_telemetryControl: 8 CH
 SG_ UI_TCR_classConstElem: 5|1@1+ (1,0) [0|0] "" X
 SG_ UI_TCR_classMovingFourWheel: 8|1@1+ (1,0) [0|0] "" X
 SG_ UI_TCR_classMovingPed: 6|1@1+ (1,0) [0|0] "" X
 SG_ UI_TCR_classMovingTwoWheel: 7|1@1+ (1,0) [0|0] "" X
 SG_ UI_TCR_classUnknown: 9|1@1+ (1,0) [0|0] "" X
 SG_ UI_TCR_downSampleFactor: 10|4@1+ (1,0) [0|0] "" X
 SG_ UI_TCR_enable: 0|1@1+ (1,0) [0|0] "" X
 SG_ UI_TCR_maxDy: 48|5@1+ (0.5,0) [0|0] "m" X
 SG_ UI_TCR_maxObjects: 56|5@1+ (1,0) [0|0] "" X
 SG_ UI_TCR_maxRoadClass: 61|3@1+ (1,0) [0|0] "" X
 SG_ UI_TCR_minRCS: 40|8@1+ (0.25,-14) [0|0] "dB" X
 SG_ UI_TCR_moveStateIndeterm: 4|1@1+ (1,0) [0|0] "" X
 SG_ UI_TCR_moveStateMoving: 3|1@1+ (1,0) [0|0] "" X
 SG_ UI_TCR_moveStateStanding: 1|1@1+ (1,0) [0|0] "" X
 SG_ UI_TCR_moveStateStopped: 2|1@1+ (1,0) [0|0] "" X
 SG_ UI_TCR_vehSpeed: 32|8@1+ (1,0) [0|0] "" X
 SG_ UI_TCR_wExist: 24|5@1+ (1,0) [0|0] "" X

BO_ 1065 APP_warningMatrix2: 8 CH
 SG_ APP_w129_mainCamExtNotCal: 0|1@1+ (1,0) [0|0] "" X
 SG_ APP_w130_narrowCamExtNotCal: 1|1@1+ (1,0) [0|0] "" X
 SG_ APP_w131_mainCamCalSaved: 2|1@1+ (1,0) [0|0] "" X
 SG_ APP_w132_narrowCamCalSaved: 3|1@1+ (1,0) [0|0] "" X
 SG_ APP_w133_mainCamInitFault: 4|1@1+ (1,0) [0|0] "" X
 SG_ APP_w134_narrowCamInitFault: 5|1@1+ (1,0) [0|0] "" X
 SG_ APP_w135_fisheyeCamInitFault: 6|1@1+ (1,0) [0|0] "" X
 SG_ APP_w136_lPillarCamInitFault: 7|1@1+ (1,0) [0|0] "" X
 SG_ APP_w137_rPillarCamInitFault: 8|1@1+ (1,0) [0|0] "" X
 SG_ APP_w138_lRepeatCamInitFault: 9|1@1+ (1,0) [0|0] "" X
 SG_ APP_w139_rRepeatCamInitFault: 10|1@1+ (1,0) [0|0] "" X
 SG_ APP_w140_backupCamInitFault: 11|1@1+ (1,0) [0|0] "" X
 SG_ APP_w141_ECU_Thermal_Issue: 12|1@1+ (1,0) [0|0] "" X
 SG_ APP_w142_fwdCamPitchProblem: 13|1@1+ (1,0) [0|0] "" X
 SG_ APP_w143_IDF_event: 14|1@1+ (1,0) [0|0] "" X
 SG_ APP_w144_fanctrldError: 15|1@1+ (1,0) [0|0] "" X
 SG_ APP_w145_camSelfCalIssue: 16|1@1+ (1,0) [0|0] "" X
 SG_ APP_w146_telemetryProblem: 17|1@1+ (1,0) [0|0] "" X
 SG_ APP_w147_selfieCamInitFault: 18|1@1+ (1,0) [0|0] "" X
 SG_ APP_w148_overlayActive: 19|1@1+ (1,0) [0|0] "" X
 SG_ APP_w149_diskFull: 20|1@1+ (1,0) [0|0] "" X
 SG_ APP_w150_diMiaPartyBus: 21|1@1+ (1,0) [0|0] "" X
 SG_ APP_w151_epasMiaPartyBus: 22|1@1+ (1,0) [0|0] "" X
 SG_ APP_w152_espMiaPartyBus: 23|1@1+ (1,0) [0|0] "" X
 SG_ APP_w153_rcmMiaPartyBus: 24|1@1+ (1,0) [0|0] "" X
 SG_ APP_w154_vcleftMiaPartyBus: 25|1@1+ (1,0) [0|0] "" X
 SG_ APP_w155_vcrightMiaPartyBus: 26|1@1+ (1,0) [0|0] "" X
 SG_ APP_w156_epblMiaVehBus: 27|1@1+ (1,0) [0|0] "" X
 SG_ APP_w157_sccmMiaVehBus: 28|1@1+ (1,0) [0|0] "" X
 SG_ APP_w158_vcfrontMiaVehBus: 29|1@1+ (1,0) [0|0] "" X
 SG_ APP_w159_vcleftMiaVehBus: 30|1@1+ (1,0) [0|0] "" X
 SG_ APP_w160_vcrightMiaVehBus: 31|1@1+ (1,0) [0|0] "" X
 SG_ APP_w161_backupCameraUnavailable: 32|1@1+ (1,0) [0|0] "" X
 SG_ APP_w162_mainCameraTypeError: 33|1@1+ (1,0) [0|0] "" X
 SG_ APP_w163_narrowCameraTypeError: 34|1@1+ (1,0) [0|0] "" X
 SG_ APP_w164_fisheyeCameraTypeError: 35|1@1+ (1,0) [0|0] "" X
 SG_ APP_w165_lPillarCameraTypeError: 36|1@1+ (1,0) [0|0] "" X
 SG_ APP_w166_rPillarCameraTypeError: 37|1@1+ (1,0) [0|0] "" X
 SG_ APP_w167_lRepeatCameraTypeError: 38|1@1+ (1,0) [0|0] "" X
 SG_ APP_w168_rRepeatCameraTypeError: 39|1@1+ (1,0) [0|0] "" X
 SG_ APP_w169_backupCameraTypeError: 40|1@1+ (1,0) [0|0] "" X
 SG_ APP_w170_selfieCameraTypeError: 41|1@1+ (1,0) [0|0] "" X
 SG_ APP_w171_appHighCoolantFlowReq: 42|1@1+ (1,0) [0|0] "" X
 SG_ APP_w172_fisheyeCamExtNotCal: 43|1@1+ (1,0) [0|0] "" X
 SG_ APP_w173_lPillarCamExtNotCal: 44|1@1+ (1,0) [0|0] "" X
 SG_ APP_w174_rPillarCamExtNotCal: 45|1@1+ (1,0) [0|0] "" X
 SG_ APP_w175_lRepeatCamExtNotCal: 46|1@1+ (1,0) [0|0] "" X
 SG_ APP_w176_rRepeatCamExtNotCal: 47|1@1+ (1,0) [0|0] "" X
 SG_ APP_w177_fisheyeCamCalSaved: 48|1@1+ (1,0) [0|0] "" X
 SG_ APP_w178_lPillarCamCalSaved: 49|1@1+ (1,0) [0|0] "" X
 SG_ APP_w179_rPillarCamCalSaved: 50|1@1+ (1,0) [0|0] "" X
 SG_ APP_w180_lRepeatCamCalSaved: 51|1@1+ (1,0) [0|0] "" X
 SG_ APP_w181_rRepeatCamCalSaved: 52|1@1+ (1,0) [0|0] "" X
 SG_ APP_w182_mainCameraStreamExit: 53|1@1+ (1,0) [0|0] "" X
 SG_ APP_w183_narrowCameraStreamExit: 54|1@1+ (1,0) [0|0] "" X
 SG_ APP_w184_fisheyeCameraStreamExit: 55|1@1+ (1,0) [0|0] "" X
 SG_ APP_w185_lPillarCameraStreamExit: 56|1@1+ (1,0) [0|0] "" X
 SG_ APP_w186_rPillarCameraStreamExit: 57|1@1+ (1,0) [0|0] "" X
 SG_ APP_w187_lRepeatCameraStreamExit: 58|1@1+ (1,0) [0|0] "" X
 SG_ APP_w188_rRepeatCameraStreamExit: 59|1@1+ (1,0) [0|0] "" X
 SG_ APP_w189_backupCameraStreamExit: 60|1@1+ (1,0) [0|0] "" X
 SG_ APP_w190_selfieCameraStreamExit: 61|1@1+ (1,0) [0|0] "" X
 SG_ APP_w191_autopilotAborting: 62|1@1+ (1,0) [0|0] "" X
 SG_ APP_w192_emergencySpeakerFail: 63|1@1+ (1,0) [0|0] "" X

BO_ 1066 ID42AVCSEC_TPMSConnectionData: 8 VehicleBus
 SG_ VCSEC_TPMSConnectionTypeCurrent0 : 11|2@1+ (1,0) [0|2] ""  Receiver
 SG_ VCSEC_TPMSConnectionTypeCurrent1 : 26|2@1+ (1,0) [0|2] ""  Receiver
 SG_ VCSEC_TPMSConnectionTypeCurrent2 : 41|2@1+ (1,0) [0|2] ""  Receiver
 SG_ VCSEC_TPMSConnectionTypeCurrent3 : 56|2@1+ (1,0) [0|2] ""  Receiver
 SG_ VCSEC_TPMSConnectionTypeDesired0 : 13|2@1+ (1,0) [0|2] ""  Receiver
 SG_ VCSEC_TPMSConnectionTypeDesired1 : 28|2@1+ (1,0) [0|2] ""  Receiver
 SG_ VCSEC_TPMSConnectionTypeDesired2 : 43|2@1+ (1,0) [0|2] ""  Receiver
 SG_ VCSEC_TPMSConnectionTypeDesired3 : 58|2@1+ (1,0) [0|2] ""  Receiver
 SG_ VCSEC_TPMSRSSI0 : 3|8@1- (1,0) [-127|0] "dBm"  Receiver
 SG_ VCSEC_TPMSRSSI1 : 18|8@1- (1,0) [-127|0] "dBm"  Receiver
 SG_ VCSEC_TPMSRSSI2 : 33|8@1- (1,0) [-127|0] "dBm"  Receiver
 SG_ VCSEC_TPMSRSSI3 : 48|8@1- (1,0) [-127|0] "dBm"  Receiver
 SG_ VCSEC_TPMSSensorState0 : 0|3@1+ (1,0) [0|4] ""  Receiver
 SG_ VCSEC_TPMSSensorState1 : 15|3@1+ (1,0) [0|4] ""  Receiver
 SG_ VCSEC_TPMSSensorState2 : 30|3@1+ (1,0) [0|4] ""  Receiver
 SG_ VCSEC_TPMSSensorState3 : 45|3@1+ (1,0) [0|4] ""  Receiver

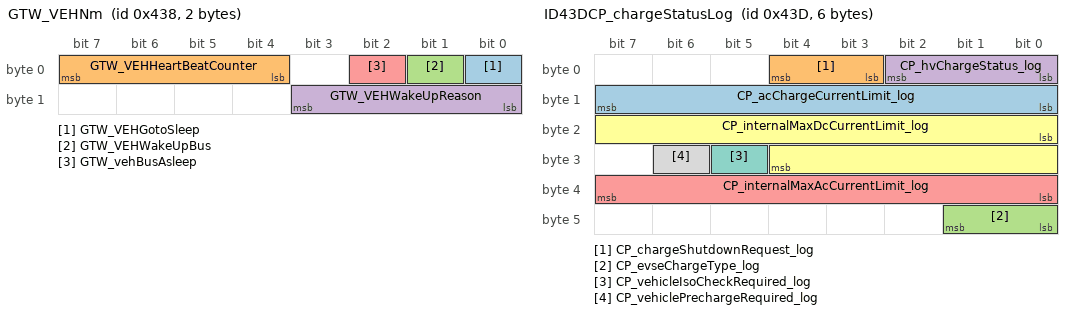
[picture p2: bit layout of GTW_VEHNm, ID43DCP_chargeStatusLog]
BO_ 1080 GTW_VEHNm: 2 VEH
 SG_ GTW_VEHGotoSleep: 0|1@1+ (1,0) [0|0] "" X
 SG_ GTW_VEHHeartBeatCounter: 4|4@1+ (1,0) [0|0] "" X
 SG_ GTW_VEHWakeUpBus: 1|1@1+ (1,0) [0|0] "" X
 SG_ GTW_VEHWakeUpReason: 8|4@1+ (1,0) [0|0] "" X
 SG_ GTW_vehBusAsleep: 2|1@1+ (1,0) [0|0] "" X

BO_ 1081 APP_warningMatrix3: 8 CH
 SG_ APP_w193_camWindshieldUnclean: 0|1@1+ (1,0) [0|0] "" X
 SG_ APP_w194_accDriverResumeRqrd: 1|1@1+ (1,0) [0|0] "" X
 SG_ APP_w195_scwUnavailable: 2|1@1+ (1,0) [0|0] "" X
 SG_ APP_w196_stopSignWarning: 3|1@1+ (1,0) [0|0] "" X
 SG_ APP_w197_redLightWarning: 4|1@1+ (1,0) [0|0] "" X
 SG_ APP_w198_tsrUnavailable: 5|1@1+ (1,0) [0|0] "" X
 SG_ APP_w199_apcAbort: 6|1@1+ (1,0) [0|0] "" X
 SG_ APP_w200_lcSlowdown: 7|1@1+ (1,0) [0|0] "" X
 SG_ APP_w201_lcAborting: 8|1@1+ (1,0) [0|0] "" X
 SG_ APP_w202_scwNoisyEnvironment: 9|1@1+ (1,0) [0|0] "" X
 SG_ APP_w203_apcActivation: 10|1@1+ (1,0) [0|0] "" X
 SG_ APP_w204_apcFinalFront: 11|1@1+ (1,0) [0|0] "" X
 SG_ APP_w205_apcFinalRear: 12|1@1+ (1,0) [0|0] "" X
 SG_ APP_w206_autosteerNotEnabled: 13|1@1+ (1,0) [0|0] "" X
 SG_ APP_w207_autosteerUnavailable: 14|1@1+ (1,0) [0|0] "" X
 SG_ APP_w208_rackDetected: 15|1@1+ (1,0) [0|0] "" X
 SG_ APP_w209_autoSummonRequest: 16|1@1+ (1,0) [0|0] "" X
 SG_ APP_w210_camObstrcted: 17|1@1+ (1,0) [0|0] "" X
 SG_ APP_w211_accNoSeatBelt: 18|1@1+ (1,0) [0|0] "" X
 SG_ APP_w212_lcUnavailableStrikeOut: 19|1@1+ (1,0) [0|0] "" X
 SG_ APP_w213_autosteerStruckOut: 20|1@1+ (1,0) [0|0] "" X
 SG_ APP_w214_driverNotIntracting: 21|1@1+ (1,0) [0|0] "" X
 SG_ APP_w215_contDriverNotIntracting: 22|1@1+ (1,0) [0|0] "" X
 SG_ APP_w216_driverOverriding: 23|1@1+ (1,0) [0|0] "" X
 SG_ APP_w217_lcUnavailableSpeeding: 24|1@1+ (1,0) [0|0] "" X
 SG_ APP_w218_lcSpeedExceededLimit: 25|1@1+ (1,0) [0|0] "" X
 SG_ APP_w219_lcTempUnavailableSpeed: 26|1@1+ (1,0) [0|0] "" X
 SG_ APP_w220_lcTempUnavailableRoad: 27|1@1+ (1,0) [0|0] "" X
 SG_ APP_w221_accRadarBlind: 28|1@1+ (1,0) [0|0] "" X
 SG_ APP_w222_accCameraBlind: 29|1@1+ (1,0) [0|0] "" X
 SG_ APP_w223_accObjectInPath: 30|1@1+ (1,0) [0|0] "" X
 SG_ APP_w224_accCameraCalibration: 31|1@1+ (1,0) [0|0] "" X
 SG_ APP_w225_lcDegradedVisSpeedLmt: 32|1@1+ (1,0) [0|0] "" X
 SG_ APP_w226_lcCamCalNeededSpeedLmt: 33|1@1+ (1,0) [0|0] "" X
 SG_ APP_w227_virtualWallBlocked: 34|1@1+ (1,0) [0|0] "" X
 SG_ APP_w228_DEPRECATED: 35|1@1+ (1,0) [0|0] "" X
 SG_ APP_w229_alcUltrasoundDamaged: 36|1@1+ (1,0) [0|0] "" X
 SG_ APP_w230_alcUltrasoundBlocked: 37|1@1+ (1,0) [0|0] "" X

BO_ 1082 DAS_warningMatrix3: 8 VEH
 SG_ DAS_w193_camWindshieldUnclean: 0|1@1+ (1,0) [0|0] "" X
 SG_ DAS_w194_accDriverResumeRqrd: 1|1@1+ (1,0) [0|0] "" X
 SG_ DAS_w195_scwUnavailable: 2|1@1+ (1,0) [0|0] "" X
 SG_ DAS_w196_stopSignWarning: 3|1@1+ (1,0) [0|0] "" X
 SG_ DAS_w197_redLightWarning: 4|1@1+ (1,0) [0|0] "" X
 SG_ DAS_w198_tsrUnavailable: 5|1@1+ (1,0) [0|0] "" X
 SG_ DAS_w199_apcAbort: 6|1@1+ (1,0) [0|0] "" X
 SG_ DAS_w200_lcSlowdown: 7|1@1+ (1,0) [0|0] "" X
 SG_ DAS_w201_lcAborting: 8|1@1+ (1,0) [0|0] "" X
 SG_ DAS_w202_scwNoisyEnvironment: 9|1@1+ (1,0) [0|0] "" X
 SG_ DAS_w203_apcActivation: 10|1@1+ (1,0) [0|0] "" X
 SG_ DAS_w204_apcFinalFront: 11|1@1+ (1,0) [0|0] "" X
 SG_ DAS_w205_apcFinalRear: 12|1@1+ (1,0) [0|0] "" X
 SG_ DAS_w206_autosteerNotEnabled: 13|1@1+ (1,0) [0|0] "" X
 SG_ DAS_w207_autosteerUnavailable: 14|1@1+ (1,0) [0|0] "" X
 SG_ DAS_w208_rackDetected: 15|1@1+ (1,0) [0|0] "" X
 SG_ DAS_w209_autoSummonRequest: 16|1@1+ (1,0) [0|0] "" X
 SG_ DAS_w210_camObstrcted: 17|1@1+ (1,0) [0|0] "" X
 SG_ DAS_w211_accNoSeatBelt: 18|1@1+ (1,0) [0|0] "" X
 SG_ DAS_w212_lcUnavailableStrikeOut: 19|1@1+ (1,0) [0|0] "" X
 SG_ DAS_w213_autosteerStruckOut: 20|1@1+ (1,0) [0|0] "" X
 SG_ DAS_w214_driverNotIntracting: 21|1@1+ (1,0) [0|0] "" X
 SG_ DAS_w215_contDriverNotIntracting: 22|1@1+ (1,0) [0|0] "" X
 SG_ DAS_w216_driverOverriding: 23|1@1+ (1,0) [0|0] "" X
 SG_ DAS_w217_lcUnavailableSpeeding: 24|1@1+ (1,0) [0|0] "" X
 SG_ DAS_w218_lcSpeedExceededLimit: 25|1@1+ (1,0) [0|0] "" X
 SG_ DAS_w219_lcTempUnavailableSpeed: 26|1@1+ (1,0) [0|0] "" X
 SG_ DAS_w220_lcTempUnavailableRoad: 27|1@1+ (1,0) [0|0] "" X
 SG_ DAS_w221_accRadarBlind: 28|1@1+ (1,0) [0|0] "" X
 SG_ DAS_w222_accCameraBlind: 29|1@1+ (1,0) [0|0] "" X
 SG_ DAS_w223_accObjectInPath: 30|1@1+ (1,0) [0|0] "" X
 SG_ DAS_w224_accCameraCalibration: 31|1@1+ (1,0) [0|0] "" X
 SG_ DAS_w225_lcDegradedVisSpeedLmt: 32|1@1+ (1,0) [0|0] "" X
 SG_ DAS_w226_lcCamCalNeededSpeedLmt: 33|1@1+ (1,0) [0|0] "" X
 SG_ DAS_w227_virtualWallBlocked: 34|1@1+ (1,0) [0|0] "" X
 SG_ DAS_w228_DEPRECATED: 35|1@1+ (1,0) [0|0] "" X
 SG_ DAS_w229_alcUltrasoundDamaged: 36|1@1+ (1,0) [0|0] "" X
 SG_ DAS_w230_alcUltrasoundBlocked: 37|1@1+ (1,0) [0|0] "" X

BO_ 1085 ID43DCP_chargeStatusLog: 6 VehicleBus
 SG_ CP_acChargeCurrentLimit_log : 8|8@1+ (0.5,0) [0|127.5] "A"  Receiver
 SG_ CP_chargeShutdownRequest_log : 3|2@1+ (1,0) [0|2] ""  Receiver
 SG_ CP_evseChargeType_log : 40|2@1+ (1,0) [0|2] ""  Receiver
 SG_ CP_hvChargeStatus_log : 0|3@1+ (1,0) [0|6] ""  Receiver
 SG_ CP_internalMaxAcCurrentLimit_log : 32|8@1+ (0.5,0) [0|127.5] "A"  Receiver
 SG_ CP_internalMaxDcCurrentLimit_log : 16|13@1+ (0.146502,0) [0|1200] "A"  Receiver
 SG_ CP_vehicleIsoCheckRequired_log : 29|1@1+ (1,0) [0|1] ""  Receiver
 SG_ CP_vehiclePrechargeRequired_log : 30|1@1+ (1,0) [0|1] ""  Receiver

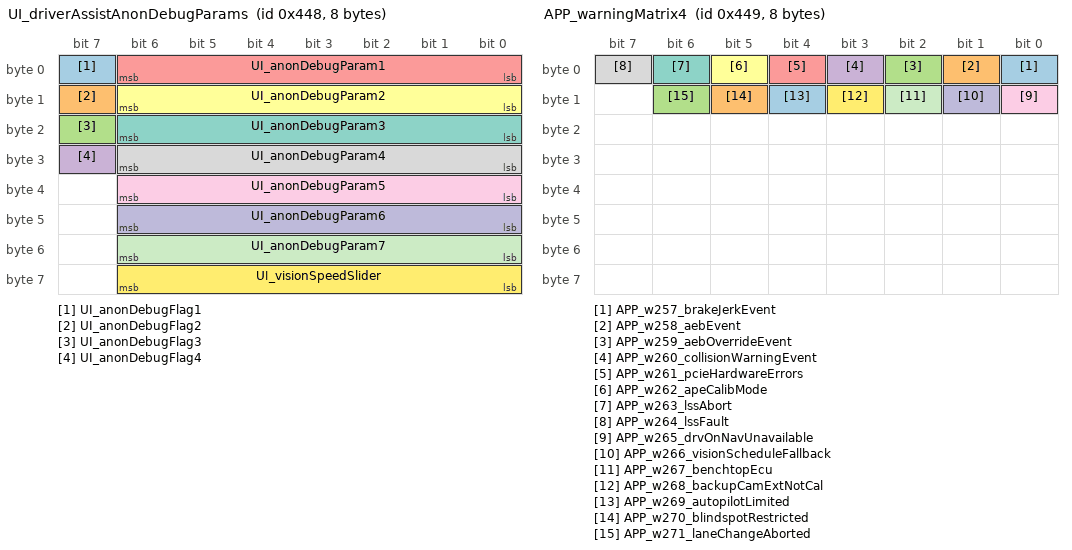
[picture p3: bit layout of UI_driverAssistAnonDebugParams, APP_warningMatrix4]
BO_ 1096 UI_driverAssistAnonDebugParams: 8 VEH
 SG_ UI_anonDebugFlag1: 7|1@1+ (1,0) [0|0] "" X
 SG_ UI_anonDebugFlag2: 15|1@1+ (1,0) [0|0] "" X
 SG_ UI_anonDebugFlag3: 23|1@1+ (1,0) [0|0] "" X
 SG_ UI_anonDebugFlag4: 31|1@1+ (1,0) [0|0] "" X
 SG_ UI_anonDebugParam1: 0|7@1+ (1,0) [0|0] "" X
 SG_ UI_anonDebugParam2: 8|7@1+ (1,0) [0|0] "" X
 SG_ UI_anonDebugParam3: 16|7@1+ (1,0) [0|0] "" X
 SG_ UI_anonDebugParam4: 24|7@1+ (1,0) [0|0] "" X
 SG_ UI_anonDebugParam5: 32|7@1+ (1,0) [0|0] "" X
 SG_ UI_anonDebugParam6: 40|7@1+ (1,0) [0|0] "" X
 SG_ UI_anonDebugParam7: 48|7@1+ (1,0) [0|0] "" X
 SG_ UI_visionSpeedSlider: 56|7@1+ (1,0) [0|0] "" X

BO_ 1097 APP_warningMatrix4: 8 CH
 SG_ APP_w257_brakeJerkEvent: 0|1@1+ (1,0) [0|0] "" X
 SG_ APP_w258_aebEvent: 1|1@1+ (1,0) [0|0] "" X
 SG_ APP_w259_aebOverrideEvent: 2|1@1+ (1,0) [0|0] "" X
 SG_ APP_w260_collisionWarningEvent: 3|1@1+ (1,0) [0|0] "" X
 SG_ APP_w261_pcieHardwareErrors: 4|1@1+ (1,0) [0|0] "" X
 SG_ APP_w262_apeCalibMode: 5|1@1+ (1,0) [0|0] "" X
 SG_ APP_w263_lssAbort: 6|1@1+ (1,0) [0|0] "" X
 SG_ APP_w264_lssFault: 7|1@1+ (1,0) [0|0] "" X
 SG_ APP_w265_drvOnNavUnavailable: 8|1@1+ (1,0) [0|0] "" X
 SG_ APP_w266_visionScheduleFallback: 9|1@1+ (1,0) [0|0] "" X
 SG_ APP_w267_benchtopEcu: 10|1@1+ (1,0) [0|0] "" X
 SG_ APP_w268_backupCamExtNotCal: 11|1@1+ (1,0) [0|0] "" X
 SG_ APP_w269_autopilotLimited: 12|1@1+ (1,0) [0|0] "" X
 SG_ APP_w270_blindspotRestricted: 13|1@1+ (1,0) [0|0] "" X
 SG_ APP_w271_laneChangeAborted: 14|1@1+ (1,0) [0|0] "" X

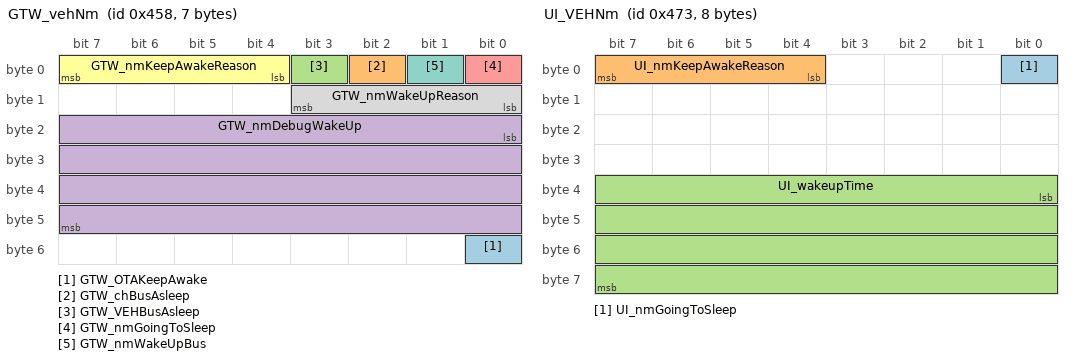
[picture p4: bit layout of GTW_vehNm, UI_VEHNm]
BO_ 1112 GTW_vehNm: 7 VEH
 SG_ GTW_OTAKeepAwake: 48|1@1+ (1,0) [0|0] "" X
 SG_ GTW_chBusAsleep: 2|1@1+ (1,0) [0|0] "" X
 SG_ GTW_VEHBusAsleep: 3|1@1+ (1,0) [0|0] "" X
 SG_ GTW_nmDebugWakeUp: 16|32@1+ (1,0) [0|0] "" X
 SG_ GTW_nmGoingToSleep: 0|1@1+ (1,0) [0|0] "" X
 SG_ GTW_nmKeepAwakeReason: 4|4@1+ (1,0) [0|0] "" X
 SG_ GTW_nmWakeUpBus: 1|1@1+ (1,0) [0|0] "" X
 SG_ GTW_nmWakeUpReason: 8|4@1+ (1,0) [0|0] "" X

BO_ 1113 APS_warningMatrix2: 8 CH
 SG_ APS_w129_ECU_Power_Issue: 0|1@1+ (1,0) [0|0] "" X
 SG_ APS_w130_ECU_Thermal_Issue: 1|1@1+ (1,0) [0|0] "" X
 SG_ APS_w131_trap_exception: 2|1@1+ (1,0) [0|0] "" X
 SG_ APS_w132_appVersionMismatch: 3|1@1+ (1,0) [0|0] "" X
 SG_ APS_w133_VEHSwitchError: 4|1@1+ (1,0) [0|0] "" X
 SG_ APS_w134_appMia: 5|1@1+ (1,0) [0|0] "" X
 SG_ APS_w135_appCritical: 6|1@1+ (1,0) [0|0] "" X
 SG_ APS_w136_gpsDisabled: 7|1@1+ (1,0) [0|0] "" X
 SG_ APS_w137_gpsFaultReset: 8|1@1+ (1,0) [0|0] "" X
 SG_ APS_w138_gpsComIssue: 9|1@1+ (1,0) [0|0] "" X
 SG_ APS_w139_udpBufferOverflow: 10|1@1+ (1,0) [0|0] "" X
 SG_ APS_w140_vcfrontMiaVEH: 11|1@1+ (1,0) [0|0] "" X
 SG_ APS_w141_rcmMiaPartyBus: 12|1@1+ (1,0) [0|0] "" X
 SG_ APS_w142_diMiaPartyBus: 13|1@1+ (1,0) [0|0] "" X
 SG_ APS_w143_espMiaPartyBus: 14|1@1+ (1,0) [0|0] "" X
 SG_ APS_w144_vcleftMiaPartyBus: 15|1@1+ (1,0) [0|0] "" X
 SG_ APS_w145_vcrightMiaPartyBus: 16|1@1+ (1,0) [0|0] "" X
 SG_ APS_w146_epas3pMiaPartyBus: 17|1@1+ (1,0) [0|0] "" X
 SG_ APS_w147_vcleftMiaVehBus: 18|1@1+ (1,0) [0|0] "" X
 SG_ APS_w148_vcrightMiaVehBus: 19|1@1+ (1,0) [0|0] "" X
 SG_ APS_w149_epblMiaVehBus: 20|1@1+ (1,0) [0|0] "" X
 SG_ APS_w150_sccmMiaVehBus: 21|1@1+ (1,0) [0|0] "" X
 SG_ APS_w151_apRecovered: 22|1@1+ (1,0) [0|0] "" X
 SG_ APS_w152_gpsFusionStatus: 23|1@1+ (1,0) [0|0] "" X
 SG_ APS_w153_eacInhibit: 24|1@1+ (1,0) [0|0] "" X
 SG_ APS_w155_VEHLwipError: 26|1@1+ (1,0) [0|0] "" X
 SG_ APS_w156_lwipAssert: 27|1@1+ (1,0) [0|0] "" X
 SG_ APS_w157_autopilotReboot: 28|1@1+ (1,0) [0|0] "" X
 SG_ APS_w158_apbMia: 29|1@1+ (1,0) [0|0] "" X
 SG_ APS_w159_apbCritical: 30|1@1+ (1,0) [0|0] "" X
 SG_ APS_w160_apbVersionMismatch: 31|1@1+ (1,0) [0|0] "" X
 SG_ APS_w161_gpsAntennaDisconnected: 32|1@1+ (1,0) [0|0] "" X

BO_ 1132 CC_alertMatrix1: 8 VEH
 SG_ CC_a001_gndMonIntrptLineSide: 0|1@1+ (1,0) [0|0] "" X
 SG_ CC_a002_gndMonIntrptLoadSide: 1|1@1+ (1,0) [0|0] "" X
 SG_ CC_a003_CCIDTripped: 2|1@1+ (1,0) [0|0] "" X
 SG_ CC_a004_CCIDSelfTestFault: 3|1@1+ (1,0) [0|0] "" X
 SG_ CC_a005_groundedNeutral: 4|1@1+ (1,0) [0|0] "" X
 SG_ CC_a006_inputOverCurrent: 5|1@1+ (1,0) [0|0] "" X
 SG_ CC_a007_inputOverVoltage: 6|1@1+ (1,0) [0|0] "" X
 SG_ CC_a008_inputUnderVoltage: 7|1@1+ (1,0) [0|0] "" X
 SG_ CC_a009_inputMiswired: 8|1@1+ (1,0) [0|0] "" X
 SG_ CC_a010_contactorWelded: 9|1@1+ (1,0) [0|0] "" X
 SG_ CC_a011_ambientOT: 10|1@1+ (1,0) [0|0] "" X
 SG_ CC_a012_wallPlugOT: 11|1@1+ (1,0) [0|0] "" X
 SG_ CC_a013_vehConnOT: 12|1@1+ (1,0) [0|0] "" X
 SG_ CC_a014_mcuSelfTestFault: 13|1@1+ (1,0) [0|0] "" X
 SG_ CC_a015_PilotAFault: 14|1@1+ (1,0) [0|0] "" X
 SG_ CC_a016_PilotBFault: 15|1@1+ (1,0) [0|0] "" X
 SG_ CC_a017_PilotCFault: 16|1@1+ (1,0) [0|0] "" X
 SG_ CC_a018_PilotDFault: 17|1@1+ (1,0) [0|0] "" X
 SG_ CC_a019_proxDisconnected: 18|1@1+ (1,0) [0|0] "" X
 SG_ CC_a020_3vRailIncorrect: 19|1@1+ (1,0) [0|0] "" X
 SG_ CC_a021_CB_noMaster: 20|1@1+ (1,0) [0|0] "" X
 SG_ CC_a022_CB_tooManyMasters: 21|1@1+ (1,0) [0|0] "" X
 SG_ CC_a023_CB_tooManySlaves: 22|1@1+ (1,0) [0|0] "" X
 SG_ CC_a024_CB_masterISetTooLow: 23|1@1+ (1,0) [0|0] "" X
 SG_ CC_a025_evseTemp: 24|1@1+ (1,0) [0|0] "" X
 SG_ CC_a026_wallPlugTemp: 25|1@1+ (1,0) [0|0] "" X
 SG_ CC_a027_vehicleHandleTemp: 26|1@1+ (1,0) [0|0] "" X
 SG_ CC_a028_CB_rotarySelect: 27|1@1+ (1,0) [0|0] "" X
 SG_ CC_a029_PilotFFault: 28|1@1+ (1,0) [0|0] "" X
 SG_ CC_a030_masterSlaveMismatch: 29|1@1+ (1,0) [0|0] "" X

BO_ 1139 UI_VEHNm: 8 VEH
 SG_ UI_nmGoingToSleep: 0|1@1+ (1,0) [0|0] "" X
 SG_ UI_nmKeepAwakeReason: 4|4@1+ (1,0) [0|0] "" X
 SG_ UI_wakeupTime: 32|32@1+ (1,0) [0|0] "" X

BO_ 1152 ODIN_IsoTpPipeVCSEC: 8 ODIN
 SG_ ODIN_IsoTpPipeVCSEC0 : 0|8@0+ (1,0) [0|255] "" GTW
 SG_ ODIN_IsoTpPipeVCSEC1 : 8|8@0+ (1,0) [0|255] "" GTW
 SG_ ODIN_IsoTpPipeVCSEC2 : 16|8@0+ (1,0) [0|255] "" GTW
 SG_ ODIN_IsoTpPipeVCSEC3 : 24|8@0+ (1,0) [0|255] "" GTW
 SG_ ODIN_IsoTpPipeVCSEC4 : 32|8@0+ (1,0) [0|255] "" GTW
 SG_ ODIN_IsoTpPipeVCSEC5 : 40|8@0+ (1,0) [0|255] "" GTW
 SG_ ODIN_IsoTpPipeVCSEC6 : 48|8@0+ (1,0) [0|255] "" GTW
 SG_ ODIN_IsoTpPipeVCSEC7 : 56|8@0+ (1,0) [0|255] "" GTW

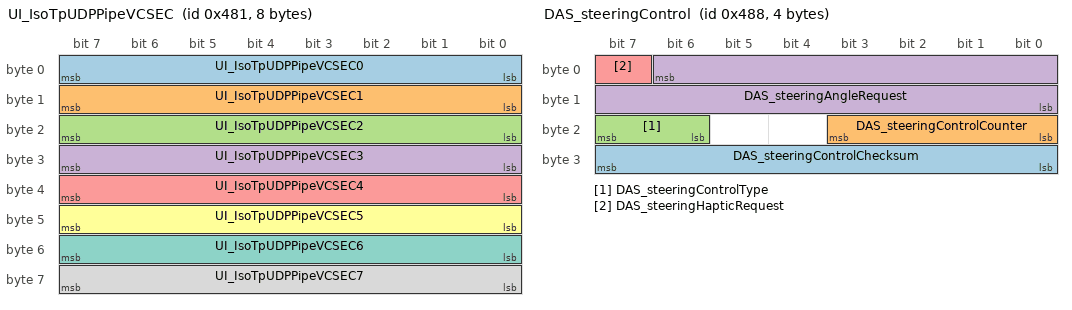
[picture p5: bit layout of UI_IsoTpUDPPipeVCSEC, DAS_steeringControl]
BO_ 1153 UI_IsoTpUDPPipeVCSEC: 8 VEH
 SG_ UI_IsoTpUDPPipeVCSEC0: 0|8@1+ (1,0) [0|0] "" X
 SG_ UI_IsoTpUDPPipeVCSEC1: 8|8@1+ (1,0) [0|0] "" X
 SG_ UI_IsoTpUDPPipeVCSEC2: 16|8@1+ (1,0) [0|0] "" X
 SG_ UI_IsoTpUDPPipeVCSEC3: 24|8@1+ (1,0) [0|0] "" X
 SG_ UI_IsoTpUDPPipeVCSEC4: 32|8@1+ (1,0) [0|0] "" X
 SG_ UI_IsoTpUDPPipeVCSEC5: 40|8@1+ (1,0) [0|0] "" X
 SG_ UI_IsoTpUDPPipeVCSEC6: 48|8@1+ (1,0) [0|0] "" X
 SG_ UI_IsoTpUDPPipeVCSEC7: 56|8@1+ (1,0) [0|0] "" X

BO_ 1160 DAS_steeringControl: 4 PARTY
 SG_ DAS_steeringControlChecksum : 24|8@1+ (1,0) [0|255] ""  aps
 SG_ DAS_steeringControlCounter : 16|4@1+ (1,0) [0|15] ""  aps
 SG_ DAS_steeringControlType : 23|2@0+ (1,0) [0|3] ""  aps
 SG_ DAS_steeringAngleRequest : 6|15@0+ (0.1,-1638.35) [-1638.35|1638.35] "deg"  aps
 SG_ DAS_steeringHapticRequest : 7|1@0+ (1,0) [0|1] ""  aps

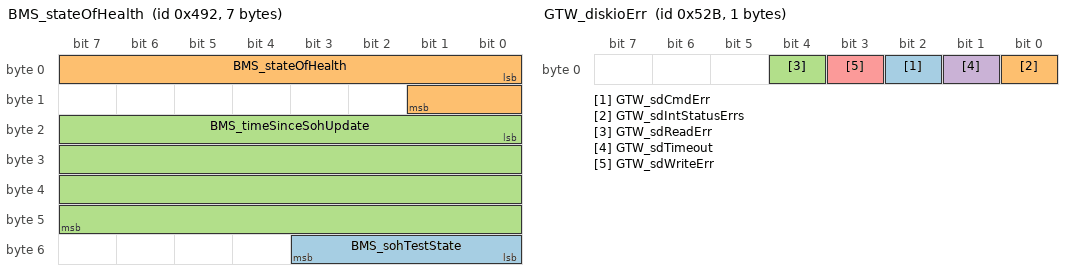
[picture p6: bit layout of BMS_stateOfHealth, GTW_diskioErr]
BO_ 1170 BMS_stateOfHealth: 7 GTW
 SG_ BMS_sohTestState : 48|4@1+ (1,0) [0|8] "" SUI
 SG_ BMS_stateOfHealth : 0|10@1+ (0.1,0) [0|100] "%" ODIN,SUI,VITALS
 SG_ BMS_timeSinceSohUpdate : 16|32@1+ (1,0) [0|4294967295] "min" ODIN,SUI,VITALS

BO_ 1177 APP_cameraTemperatures: 8 GTW
 SG_ APP_lRepeaterCameraTemperature : 32|8@1+ (1,-60) [-60|195] "C" ODIN
 SG_ APP_rRepeaterCameraTemperature : 24|8@1+ (1,-60) [-60|195] "C" ODIN

BO_ 1250 VCLEFT_seatStatus: 8 GTW
 SG_ VCLEFT_frontSeatBackPos : 8|16@1- (1,0) [-32768|32767] "" ODIN
 SG_ VCLEFT_frontSeatLiftPos : 8|16@1- (1,0) [-32768|32767] "" ODIN
 SG_ VCLEFT_frontSeatTiltPos : 8|16@1- (1,0) [-32768|32767] "" ODIN
 SG_ VCLEFT_frontSeatTrackPos : 8|16@1- (1,0) [-32768|32767] "" ODIN
 SG_ VCLEFT_seatStatusIndex : 0|3@1+ (1,0) [0|6] "" XXX

BO_ 1251 VCRIGHT_seatStatus: 8 GTW
 SG_ VCRIGHT_frontSeatBackPos : 8|16@1- (1,0) [-32768|32767] "" ODIN
 SG_ VCRIGHT_frontSeatLiftPos : 8|16@1- (1,0) [-32768|32767] "" ODIN
 SG_ VCRIGHT_frontSeatTiltPos : 8|16@1- (1,0) [-32768|32767] "" ODIN
 SG_ VCRIGHT_frontSeatTrackPos : 8|16@1- (1,0) [-32768|32767] "" ODIN
 SG_ VCRIGHT_seatStatusIndex : 0|3@1+ (1,0) [0|6] "" XXX

BO_ 1280 UI_debugECU: 2 VEH
 SG_ UI_debugEcuTarget M: 0|3@1+ (1,0) [0|0] "" X
 SG_ UI_DI_debugEnable m1: 8|1@1+ (1,0) [0|0] "" X
 SG_ UI_DIS_debugEnable m2: 8|1@1+ (1,0) [0|0] "" X
 SG_ UI_PM_debugEnable m3: 8|1@1+ (1,0) [0|0] "" X
 SG_ UI_PM_debugAt100Hz m3: 9|1@1+ (1,0) [0|0] "" X
 SG_ UI_PMS_debugEnable m4: 8|1@1+ (1,0) [0|0] "" X
 SG_ UI_PMS_debugAt100Hz m4: 9|1@1+ (1,0) [0|0] "" X
 SG_ UI_BMS_debugAllEnable m5: 8|1@1+ (1,0) [0|0] "" X
 SG_ UI_BMS_debugDisable m5: 9|1@1+ (1,0) [0|0] "" X
 SG_ UI_VCRIGHT_debugEnable m6: 8|1@1+ (1,0) [0|0] "" X
 SG_ UI_VCFRONT_debugEnable m7: 3|1@1+ (1,0) [0|0] "" X

BO_ 1282 RADC_alertMatrix0: 8 CH
 SG_ RADC_a001_can1BusOff: 1|1@1+ (1,0) [0|0] "" X
 SG_ RADC_a002_ecuAdcError: 2|1@1+ (1,0) [0|0] "" X
 SG_ RADC_a003_ecuBistDisabled: 3|1@1+ (1,0) [0|0] "" X
 SG_ RADC_a004_ecuCrcHwError: 4|1@1+ (1,0) [0|0] "" X
 SG_ RADC_a005_ecuEcuMError: 5|1@1+ (1,0) [0|0] "" X
 SG_ RADC_a006_ecuFimError: 6|1@1+ (1,0) [0|0] "" X
 SG_ RADC_a007_ecuGptCheckError: 7|1@1+ (1,0) [0|0] "" X
 SG_ RADC_a008_ecuHwSwInterlock: 8|1@1+ (1,0) [0|0] "" X
 SG_ RADC_a009_plantModeActive: 9|1@1+ (1,0) [0|0] "" X
 SG_ RADC_a010_ecuIoHwAbError: 10|1@1+ (1,0) [0|0] "" X
 SG_ RADC_a011_ecuMcemError: 11|1@1+ (1,0) [0|0] "" X
 SG_ RADC_a012_ecuSpiError: 12|1@1+ (1,0) [0|0] "" X
 SG_ RADC_a013_ecuWdgError: 13|1@1+ (1,0) [0|0] "" X
 SG_ RADC_a014_fctSelfTestNotDone: 14|1@1+ (1,0) [0|0] "" X
 SG_ RADC_a015_fctSenInterference: 15|1@1+ (1,0) [0|0] "" X
 SG_ RADC_a016_adcOverVolt: 16|1@1+ (1,0) [0|0] "" X
 SG_ RADC_a017_adcUnderVolt: 17|1@1+ (1,0) [0|0] "" X
 SG_ RADC_a018_internalHardwareFault: 18|1@1+ (1,0) [0|0] "" X
 SG_ RADC_a019_internalSoftwareFault: 19|1@1+ (1,0) [0|0] "" X
 SG_ RADC_a020_overTemp: 20|1@1+ (1,0) [0|0] "" X
 SG_ RADC_a021_overTempCrit: 21|1@1+ (1,0) [0|0] "" X
 SG_ RADC_a022_tempImplausible: 22|1@1+ (1,0) [0|0] "" X
 SG_ RADC_a023_underTemp: 23|1@1+ (1,0) [0|0] "" X
 SG_ RADC_a024_underTempCrit: 24|1@1+ (1,0) [0|0] "" X
 SG_ RADC_a025_overVoltage: 25|1@1+ (1,0) [0|0] "" X
 SG_ RADC_a026_underVoltage: 26|1@1+ (1,0) [0|0] "" X
 SG_ RADC_a027_nvmFailure: 27|1@1+ (1,0) [0|0] "" X
 SG_ RADC_a028_rfChipError: 28|1@1+ (1,0) [0|0] "" X
 SG_ RADC_a029_rhcError: 29|1@1+ (1,0) [0|0] "" X
 SG_ RADC_a030_rspError: 30|1@1+ (1,0) [0|0] "" X
 SG_ RADC_a031_sensorMisaligned: 31|1@1+ (1,0) [0|0] "" X
 SG_ RADC_a032_sensorBlocked: 32|1@1+ (1,0) [0|0] "" X
 SG_ RADC_a033_sensorNeverAligned: 33|1@1+ (1,0) [0|0] "" X
 SG_ RADC_a034_vehDynamicsError: 34|1@1+ (1,0) [0|0] "" X
 SG_ RADC_a035_vinMIA: 35|1@1+ (1,0) [0|0] "" X
 SG_ RADC_a036_carConfigMIA: 36|1@1+ (1,0) [0|0] "" X
 SG_ RADC_a037_inertialSignalsMIA: 37|1@1+ (1,0) [0|0] "" X
 SG_ RADC_a038_steeringWheelAngleMIA: 38|1@1+ (1,0) [0|0] "" X
 SG_ RADC_a039_vehicleStateMIA: 39|1@1+ (1,0) [0|0] "" X
 SG_ RADC_a040_wheelSpeedsMIA: 40|1@1+ (1,0) [0|0] "" X
 SG_ RADC_a041_vinErr: 41|1@1+ (1,0) [0|0] "" X
 SG_ RADC_a042_carConfigErr: 42|1@1+ (1,0) [0|0] "" X
 SG_ RADC_a043_inertialSignalsErr: 43|1@1+ (1,0) [0|0] "" X
 SG_ RADC_a044_steeringWheelAngleErr: 44|1@1+ (1,0) [0|0] "" X
 SG_ RADC_a045_vehicleStateErr: 45|1@1+ (1,0) [0|0] "" X
 SG_ RADC_a046_wheelSpeedsErr: 46|1@1+ (1,0) [0|0] "" X
 SG_ RADC_a047_mismatchChassisType: 47|1@1+ (1,0) [0|0] "" X
 SG_ RADC_a048_mismatchAirSuspension: 48|1@1+ (1,0) [0|0] "" X
 SG_ RADC_a049_mismatchFourWheelDrive: 49|1@1+ (1,0) [0|0] "" X
 SG_ RADC_a050_mismatchCountry: 50|1@1+ (1,0) [0|0] "" X
 SG_ RADC_a051_mismatchEPASType: 51|1@1+ (1,0) [0|0] "" X
 SG_ RADC_a052_mismatcRadPos: 52|1@1+ (1,0) [0|0] "" X
 SG_ RADC_a053_emError: 53|1@1+ (1,0) [0|0] "" X
 SG_ RADC_a054_blockageInfo_Frame_1: 54|1@1+ (1,0) [0|0] "" X
 SG_ RADC_a055_blockageInfo_Frame_2: 55|1@1+ (1,0) [0|0] "" X

BO_ 1303 FC_identifier: 8 VEH
 SG_ FC_id: 0|32@1+ (1,0) [0|0] "" X
 SG_ FC_sessionId: 32|32@1+ (1,0) [0|0] "" X

BO_ 1310 ID51EFC_info: 8 VehicleBus
 SG_ FC_infoIndex M : 0|8@1+ (1,0) [0|255] ""  Receiver
 SG_ FC_infoAppGitHashBytes m17 : 8|56@1+ (1,0) [0|7.20576E+016] ""  Receiver
 SG_ FC_infoApplicationCRC m13 : 32|32@1+ (1,0) [0|4294970000] ""  Receiver
 SG_ FC_infoAssemblyID m11 : 24|8@1+ (1,0) [0|255] ""  Receiver
 SG_ FC_infoBootCRC m15 : 32|32@1+ (1,0) [0|4294970000] ""  Receiver
 SG_ FC_infoBootGitHashBytes m18 : 8|56@1+ (1,0) [0|7.20576E+016] ""  Receiver
 SG_ FC_infoBootSvnRev m14 : 8|24@1+ (1,0) [0|16777200] ""  Receiver
 SG_ FC_infoBootUdsProtoVersion m20 : 8|8@1+ (1,0) [0|255] ""  Receiver
 SG_ FC_infoBranchOrigin m19 : 24|8@1+ (1,0) [0|255] ""  Receiver
 SG_ FC_infoBuildConfigID m10 : 16|8@1+ (1,0) [0|255] ""  Receiver
 SG_ FC_infoBuildType m10 : 8|3@1+ (1,0) [0|4] ""  Receiver
 SG_ FC_infoCPLDVersionMajor m16 : 16|8@1+ (1,0) [0|255] ""  Receiver
 SG_ FC_infoCPLDVersionMinor m16 : 24|8@1+ (1,0) [0|255] ""  Receiver
 SG_ FC_infoComponentID m10 : 48|16@1+ (1,0) [0|65535] ""  Receiver
 SG_ FC_infoHardwareID m10 : 32|16@1+ (1,0) [0|65535] ""  Receiver
 SG_ FC_infoHardwareRevision m19 : 40|8@1+ (1,0) [0|255] ""  Receiver
 SG_ FC_infoMajorVersion m19 : 16|8@1+ (1,0) [0|255] ""  Receiver
 SG_ FC_infoMaturity m19 : 32|8@1+ (1,0) [0|255] ""  Receiver
 SG_ FC_infoPcbaID m11 : 16|8@1+ (1,0) [0|255] ""  Receiver
 SG_ FC_infoPlatformType m19 : 8|8@1+ (1,0) [0|255] ""  Receiver
 SG_ FC_infoSubUsageID m11 : 48|16@1+ (1,0) [0|65535] ""  Receiver
 SG_ FC_infoUsageID m11 : 32|16@1+ (1,0) [0|65535] ""  Receiver
 SG_ FC_infoVariantCRC m22 : 32|32@1+ (1,0) [0|4294970000] ""  Receiver
 SG_ FC_partNumChar01 m25 : 8|8@1+ (1,0) [0|1] ""  Receiver
 SG_ FC_partNumChar02 m25 : 16|8@1+ (1,0) [0|1] ""  Receiver
 SG_ FC_partNumChar03 m25 : 24|8@1+ (1,0) [0|1] ""  Receiver
 SG_ FC_partNumChar04 m25 : 32|8@1+ (1,0) [0|1] ""  Receiver
 SG_ FC_partNumChar05 m25 : 40|8@1+ (1,0) [0|1] ""  Receiver
 SG_ FC_partNumChar06 m25 : 48|8@1+ (1,0) [0|1] ""  Receiver
 SG_ FC_partNumChar07 m25 : 56|8@1+ (1,0) [0|1] ""  Receiver
 SG_ FC_partNumChar08 m26 : 8|8@1+ (1,0) [0|1] ""  Receiver
 SG_ FC_partNumChar09 m26 : 16|8@1+ (1,0) [0|1] ""  Receiver
 SG_ FC_partNumChar10 m26 : 24|8@1+ (1,0) [0|1] ""  Receiver
 SG_ FC_partNumChar11 m26 : 32|8@1+ (1,0) [0|1] ""  Receiver
 SG_ FC_partNumChar12 m26 : 40|8@1+ (1,0) [0|1] ""  Receiver
 SG_ FC_partNumChar13 m26 : 48|8@1+ (1,0) [0|1] ""  Receiver
 SG_ FC_partNumChar14 m26 : 56|8@1+ (1,0) [0|1] ""  Receiver
 SG_ FC_partNumChar15 m27 : 8|8@1+ (1,0) [0|1] ""  Receiver
 SG_ FC_partNumChar16 m27 : 16|8@1+ (1,0) [0|1] ""  Receiver
 SG_ FC_partNumChar17 m27 : 24|8@1+ (1,0) [0|1] ""  Receiver
 SG_ FC_partNumChar18 m27 : 32|8@1+ (1,0) [0|1] ""  Receiver
 SG_ FC_partNumChar19 m27 : 40|8@1+ (1,0) [0|1] ""  Receiver
 SG_ FC_partNumChar20 m27 : 48|8@1+ (1,0) [0|1] ""  Receiver

BO_ 1320 ID528UnixTime: 4 VehicleBus
 SG_ UnixTimeSeconds528 : 7|32@0+ (1,0) [0|4294970000] "sec"  Receiver

BO_ 1323 GTW_diskioErr: 1 VEH
 SG_ GTW_sdCmdErr: 2|1@1+ (1,0) [0|0] "" X
 SG_ GTW_sdIntStatusErrs: 0|1@1+ (1,0) [0|0] "" X
 SG_ GTW_sdReadErr: 4|1@1+ (1,0) [0|0] "" X
 SG_ GTW_sdTimeout: 1|1@1+ (1,0) [0|0] "" X
 SG_ GTW_sdWriteErr: 3|1@1+ (1,0) [0|0] "" X

BO_ 1329 RADC_info: 8 CH
 SG_ RADC_infoIndex M: 0|8@1+ (1,0) [0|0] "" X
 SG_ RADC_infoPlatformType m19: 8|8@1+ (1,0) [0|0] "" X
 SG_ RADC_infoMajorVersion m19: 16|8@1+ (1,0) [0|0] "" X
 SG_ RADC_infoBranchOrigin m19: 24|8@1+ (1,0) [0|0] "" X
 SG_ RADC_infoMaturity m19: 32|8@1+ (1,0) [0|0] "" X
 SG_ RADC_infoHardwareRevision m19: 40|8@1+ (1,0) [0|0] "" X
 SG_ RADC_infoBuildType m10: 8|8@1+ (1,0) [0|0] "" X
 SG_ RADC_infoBuildConfigID m10: 16|16@1+ (1,0) [0|0] "" X
 SG_ RADC_infoHardwareID m10: 32|16@1+ (1,0) [0|0] "" X
 SG_ RADC_infoComponentID m10: 48|16@1+ (1,0) [0|0] "" X
 SG_ RADC_infoPcbaID m11: 16|8@1+ (1,0) [0|0] "" X
 SG_ RADC_infoAssemblyID m11: 24|8@1+ (1,0) [0|0] "" X
 SG_ RADC_infoUsageID m11: 32|16@1+ (1,0) [0|0] "" X
 SG_ RADC_infoSubUsageID m11: 48|16@1+ (1,0) [0|0] "" X
 SG_ RADC_infoBootUdsProtoVersion m20: 8|8@1+ (1,0) [0|0] "" X
 SG_ RADC_infoBootloaderCRC m20: 32|32@1+ (1,0) [0|0] "" X
 SG_ RADC_infoApplicationCRC m13: 32|32@1+ (1,0) [0|0] "" X

BO_ 1337 DAS_info: 8 CH
 SG_ DAS_infoIndex M: 0|8@1+ (1,0) [0|0] "" X
 SG_ DAS_infoBuildType m10: 8|8@1+ (1,0) [0|0] "" X
 SG_ DAS_infoBuildConfigID m10: 16|16@1+ (1,0) [0|0] "" X
 SG_ DAS_infoHardwareID m10: 32|16@1+ (1,0) [0|0] "" X
 SG_ DAS_infoComponentID m10: 48|16@1+ (1,0) [0|0] "" X
 SG_ DAS_infoPcbaID m11: 16|8@1+ (1,0) [0|0] "" X
 SG_ DAS_infoAssemblyID m11: 24|8@1+ (1,0) [0|0] "" X
 SG_ DAS_infoUsageID m11: 32|16@1+ (1,0) [0|0] "" X
 SG_ DAS_infoSubUsageID m11: 48|16@1+ (1,0) [0|0] "" X
 SG_ DAS_infoApplicationCRC m13: 32|32@1+ (1,0) [0|0] "" X
 SG_ DAS_infoBootloaderSvnRevision m14: 8|24@1+ (1,0) [0|0] "" X
 SG_ DAS_infoEyeQBootCRC m16: 16|32@1+ (1,0) [0|0] "" X
 SG_ DAS_infoAppGitHashBytes m17: 10|54@1+ (4,0) [0|0] "" X
 SG_ DAS_infoBootGitHashBytes m18: 10|54@1+ (4,0) [0|0] "" X
 SG_ DAS_infoPlatformType m19: 8|8@1+ (1,0) [0|0] "" X
 SG_ DAS_infoMajorVersion m19: 16|8@1+ (1,0) [0|0] "" X
 SG_ DAS_infoBranchOrigin m19: 24|8@1+ (1,0) [0|0] "" X
 SG_ DAS_infoMaturity m19: 32|8@1+ (1,0) [0|0] "" X
 SG_ DAS_infoHardwareRevision m19: 40|8@1+ (1,0) [0|0] "" X
 SG_ DAS_infoBootUdsProtoVersion m20: 8|8@1+ (1,0) [0|0] "" X
 SG_ DAS_infoBootloaderCRC m20: 32|32@1+ (1,0) [0|0] "" X
 SG_ DAS_infoEyeQAppCRC m23: 16|32@1+ (1,0) [0|0] "" X
 SG_ DAS_infoEyeQFfsCRC m24: 16|32@1+ (1,0) [0|0] "" X

BO_ 1342 CP_info: 8 VEH
 SG_ CP_infoIndex M: 0|8@1+ (1,0) [0|0] "" X
 SG_ CP_buildType m10: 8|3@1+ (1,0) [0|0] "" X
 SG_ CP_buildConfigId m10: 16|16@1+ (1,0) [0|0] "" X
 SG_ CP_hardwareId m10: 32|16@1+ (1,0) [0|0] "" X
 SG_ CP_componentId m10: 48|16@1+ (1,0) [0|0] "" X
 SG_ CP_pcbaId m11: 16|8@1+ (1,0) [0|0] "" X
 SG_ CP_assemblyId m11: 24|8@1+ (1,0) [0|0] "" X
 SG_ CP_usageId m11: 32|16@1+ (1,0) [0|0] "" X
 SG_ CP_subUsageId m11: 48|16@1+ (1,0) [0|0] "" X
 SG_ CP_platformType m13: 8|8@1+ (1,0) [0|0] "" X
 SG_ CP_appCrc m13: 32|32@1+ (1,0) [0|0] "" X
 SG_ CP_appGitHash m17: 10|54@1+ (4,0) [0|0] "" X
 SG_ CP_bootGitHash m18: 10|54@1+ (4,0) [0|0] "" X
 SG_ CP_bootUdsProtoVersion m20: 8|8@1+ (1,0) [0|0] "" X
 SG_ CP_bootCrc m20: 32|32@1+ (1,0) [0|0] "" X

BO_ 1345 ID541FastChargeMaxLimits: 8 VehicleBus
 SG_ FCMaxPowerLimit541 : 0|13@1+ (0.062256,0) [0|509.939] "kW"  Receiver
 SG_ FCMaxCurrentLimit541 : 16|13@1+ (0.073242,0) [0|599.925] "A"  Receiver

BO_ 1353 APP_info: 8 CH
 SG_ APP_infoIndex M: 0|8@1+ (1,0) [0|0] "" X
 SG_ APP_buildType m0: 8|8@1+ (1,0) [0|0] "" X
 SG_ APP_infoAppFwGitHashBytes m1: 10|54@1+ (4,0) [0|0] "" X
 SG_ APP_infoAppApGitHashBytes m2: 10|54@1+ (4,0) [0|0] "" X

BO_ 1355 SCM_alertMatrix2: 8 VEH
 SG_ SCM_a065_vBatRationalityStage1: 0|1@1+ (1,0) [0|0] "" X
 SG_ SCM_a066_vBatRationalityStage2: 1|1@1+ (1,0) [0|0] "" X
 SG_ SCM_a067_vBatRationalityStage3: 2|1@1+ (1,0) [0|0] "" X
 SG_ SCM_a068_vBatRationalityStage4: 3|1@1+ (1,0) [0|0] "" X
 SG_ SCM_a069_vStageRationalityV1: 4|1@1+ (1,0) [0|0] "" X
 SG_ SCM_a070_vStageRationalityV2: 5|1@1+ (1,0) [0|0] "" X
 SG_ SCM_a071_chargerMIA: 6|1@1+ (1,0) [0|0] "" X
 SG_ SCM_a072_gtwMIA: 7|1@1+ (1,0) [0|0] "" X
 SG_ SCM_a073_lccMIA: 8|1@1+ (1,0) [0|0] "" X
 SG_ SCM_a074_isoVDiffHi: 9|1@1+ (1,0) [0|0] "" X
 SG_ SCM_a075_leakageTestAbsDecayLow: 10|1@1+ (1,0) [0|0] "" X
 SG_ SCM_a076_bmsMIA: 11|1@1+ (1,0) [0|0] "" X
 SG_ SCM_a077_unexpectedVbatBehavior: 12|1@1+ (1,0) [0|0] "" X
 SG_ SCM_a078_voltageMatchTimeout: 13|1@1+ (1,0) [0|0] "" X
 SG_ SCM_a079_unexpectedVbat: 14|1@1+ (1,0) [0|0] "" X
 SG_ SCM_a080_lccFaulted: 15|1@1+ (1,0) [0|0] "" X
 SG_ SCM_a081_rmsInputVoltageHigh: 16|1@1+ (1,0) [0|0] "" X
 SG_ SCM_a082_VbatUV: 17|1@1+ (1,0) [0|0] "" X
 SG_ SCM_a083_chargeCurrentLimited: 18|1@1+ (1,0) [0|0] "" X
 SG_ SCM_a084_unused84: 19|1@1+ (1,0) [0|0] "" X
 SG_ SCM_a085_unused85: 20|1@1+ (1,0) [0|0] "" X
 SG_ SCM_a086_lccResetDetected: 21|1@1+ (1,0) [0|0] "" X
 SG_ SCM_a087_posCordTempRationality: 22|1@1+ (1,0) [0|0] "" X
 SG_ SCM_a088_negCordTempRationality: 23|1@1+ (1,0) [0|0] "" X
 SG_ SCM_a089_posCordOT: 24|1@1+ (1,0) [0|0] "" X
 SG_ SCM_a090_negCordOT: 25|1@1+ (1,0) [0|0] "" X
 SG_ SCM_a091_voltageRiseDetection: 26|1@1+ (1,0) [0|0] "" X
 SG_ SCM_a092_cabEnableDeasserted: 27|1@1+ (1,0) [0|0] "" X
 SG_ SCM_a093_unused93: 28|1@1+ (1,0) [0|0] "" X
 SG_ SCM_a094_unused94: 29|1@1+ (1,0) [0|0] "" X
 SG_ SCM_a095_unused95: 30|1@1+ (1,0) [0|0] "" X
 SG_ SCM_a096_unused96: 31|1@1+ (1,0) [0|0] "" X
 SG_ SCM_a097_unused97: 32|1@1+ (1,0) [0|0] "" X
 SG_ SCM_a098_unused98: 33|1@1+ (1,0) [0|0] "" X
 SG_ SCM_a099_unused99: 34|1@1+ (1,0) [0|0] "" X
 SG_ SCM_a100_unused100: 35|1@1+ (1,0) [0|0] "" X
 SG_ SCM_a101_unused101: 36|1@1+ (1,0) [0|0] "" X
 SG_ SCM_a102_unused102: 37|1@1+ (1,0) [0|0] "" X
 SG_ SCM_a103_unused103: 38|1@1+ (1,0) [0|0] "" X
 SG_ SCM_a104_unused104: 39|1@1+ (1,0) [0|0] "" X
 SG_ SCM_a105_unused105: 40|1@1+ (1,0) [0|0] "" X
 SG_ SCM_a106_unused106: 41|1@1+ (1,0) [0|0] "" X
 SG_ SCM_a107_unused107: 42|1@1+ (1,0) [0|0] "" X
 SG_ SCM_a108_unused108: 43|1@1+ (1,0) [0|0] "" X
 SG_ SCM_a109_unused109: 44|1@1+ (1,0) [0|0] "" X
 SG_ SCM_a110_unused110: 45|1@1+ (1,0) [0|0] "" X
 SG_ SCM_a111_unused111: 46|1@1+ (1,0) [0|0] "" X
 SG_ SCM_a112_unused112: 47|1@1+ (1,0) [0|0] "" X
 SG_ SCM_a113_unused113: 48|1@1+ (1,0) [0|0] "" X
 SG_ SCM_a114_unused114: 49|1@1+ (1,0) [0|0] "" X
 SG_ SCM_a115_unused115: 50|1@1+ (1,0) [0|0] "" X
 SG_ SCM_a116_unused116: 51|1@1+ (1,0) [0|0] "" X
 SG_ SCM_a117_unused117: 52|1@1+ (1,0) [0|0] "" X
 SG_ SCM_a118_unused118: 53|1@1+ (1,0) [0|0] "" X
 SG_ SCM_a119_unused119: 54|1@1+ (1,0) [0|0] "" X
 SG_ SCM_a120_unused120: 55|1@1+ (1,0) [0|0] "" X
 SG_ SCM_a121_unused121: 56|1@1+ (1,0) [0|0] "" X
 SG_ SCM_a122_unused122: 57|1@1+ (1,0) [0|0] "" X
 SG_ SCM_a123_unused123: 58|1@1+ (1,0) [0|0] "" X
 SG_ SCM_a124_unused124: 59|1@1+ (1,0) [0|0] "" X
 SG_ SCM_a125_unused125: 60|1@1+ (1,0) [0|0] "" X
 SG_ SCM_a126_unused126: 61|1@1+ (1,0) [0|0] "" X
 SG_ SCM_a127_unused127: 62|1@1+ (1,0) [0|0] "" X
 SG_ SCM_a128_unused128: 63|1@1+ (1,0) [0|0] "" X

BO_ 1357 TAS_info: 8 VEH
 SG_ TAS_infoIndex M: 0|8@1+ (1,0) [0|0] "" X
 SG_ TAS_infoBuildType m10: 8|3@1+ (1,0) [0|0] "" X
 SG_ TAS_infoBuildConfigId m10: 16|16@1+ (1,0) [0|0] "" X
 SG_ TAS_infoHardwareId m10: 32|1@1+ (1,0) [0|0] "" X
 SG_ TAS_infoComponentId m10: 48|16@1+ (1,0) [0|0] "" X
 SG_ TAS_infoPcbaId m11: 16|8@1+ (1,0) [0|0] "" X
 SG_ TAS_infoAssemblyId m11: 24|8@1+ (1,0) [0|0] "" X
 SG_ TAS_infoUsageId m11: 32|16@1+ (1,0) [0|0] "" X
 SG_ TAS_infoSubUsageId m11: 48|16@1+ (1,0) [0|0] "" X
 SG_ TAS_infoAppCrc m13: 32|32@1+ (1,0) [0|0] "" X
 SG_ TAS_infoBootloaderSvnRevision m14: 8|24@1+ (1,0) [0|0] "" X
 SG_ TAS_infoAppGitHash m17: 10|54@1+ (4,0) [0|0] "" X
 SG_ TAS_infoBootGitHash m18: 10|54@1+ (4,0) [0|0] "" X
 SG_ TAS_infoPlatformType m19: 8|8@1+ (1,0) [0|0] "" X
 SG_ TAS_infoMajorVersion m19: 16|8@1+ (1,0) [0|0] "" X
 SG_ TAS_infoBranchOrigin m19: 24|8@1+ (1,0) [0|0] "" X
 SG_ TAS_infoMaturity m19: 32|8@1+ (1,0) [0|0] "" X
 SG_ TAS_infoHardwareRevision m19: 40|8@1+ (1,0) [0|0] "" X
 SG_ TAS_infoBootUdsProtoVersion m20: 8|8@1+ (1,0) [0|0] "" X
 SG_ TAS_infoBootCrc m20: 32|32@1+ (1,0) [0|0] "" X

BO_ 1359 SCCM_alertMatrix: 8 VEH
 SG_ SCCM_matrixIndex M: 0|4@1+ (1,0) [0|0] "" X
 SG_ SCCM_a001_CANBusOff m0: 4|1@1+ (1,0) [0|0] "" X
 SG_ SCCM_a002_CANTOut m0: 5|1@1+ (1,0) [0|0] "" X
 SG_ SCCM_a003_highBeamOpen m0: 6|1@1+ (1,0) [0|0] "" X
 SG_ SCCM_a004_highBeamShortToGND m0: 7|1@1+ (1,0) [0|0] "" X
 SG_ SCCM_a005_tipWipeOpen m0: 8|1@1+ (1,0) [0|0] "" X
 SG_ SCCM_a006_tipWipeShortToGND m0: 9|1@1+ (1,0) [0|0] "" X
 SG_ SCCM_a007_turnIndComInfo m0: 10|1@1+ (1,0) [0|0] "" X
 SG_ SCCM_a008_turnIndInvalidTrans m0: 11|1@1+ (1,0) [0|0] "" X
 SG_ SCCM_a009_turnIndOpen m0: 12|1@1+ (1,0) [0|0] "" X
 SG_ SCCM_a010_turnIndShortToGnd m0: 13|1@1+ (1,0) [0|0] "" X
 SG_ SCCM_a011_turnIndHWErr m0: 14|1@1+ (1,0) [0|0] "" X
 SG_ SCCM_a012_turnGenErr m0: 15|1@1+ (1,0) [0|0] "" X
 SG_ SCCM_a013_voltageHigh m0: 16|1@1+ (1,0) [0|0] "" X
 SG_ SCCM_a014_voltageLow m0: 17|1@1+ (1,0) [0|0] "" X
 SG_ SCCM_a015_softwareError m0: 18|1@1+ (1,0) [0|0] "" X
 SG_ SCCM_a016_hardwareError m0: 19|1@1+ (1,0) [0|0] "" X
 SG_ SCCM_a017_memoryError m0: 20|1@1+ (1,0) [0|0] "" X
 SG_ SCCM_a018_angleSpeedOutOfRange m0: 21|1@1+ (1,0) [0|0] "" X
 SG_ SCCM_a019_angleSpeedAboveLimit m0: 22|1@1+ (1,0) [0|0] "" X
 SG_ SCCM_a020_angleInternalError m0: 23|1@1+ (1,0) [0|0] "" X
 SG_ SCCM_a021_gearStalkSignalInvalid m0: 24|1@1+ (1,0) [0|0] "" X
 SG_ SCCM_a022_gearStalkOpenCircuit m0: 25|1@1+ (1,0) [0|0] "" X
 SG_ SCCM_a023_gearStalkShortCircuit m0: 26|1@1+ (1,0) [0|0] "" X
 SG_ SCCM_a024_gearStalkGenErr m0: 27|1@1+ (1,0) [0|0] "" X
 SG_ SCCM_a025_runTimeError m0: 28|1@1+ (1,0) [0|0] "" X
 SG_ SCCM_a026_parkButtonInvalidSignal m0: 29|1@1+ (1,0) [0|0] "" X
 SG_ SCCM_a027_parkButtonOpenCircuit m0: 30|1@1+ (1,0) [0|0] "" X
 SG_ SCCM_a028_parkButtonShortToGround m0: 31|1@1+ (1,0) [0|0] "" X
 SG_ SCCM_a029_parkButtonMalfunction m0: 32|1@1+ (1,0) [0|0] "" X

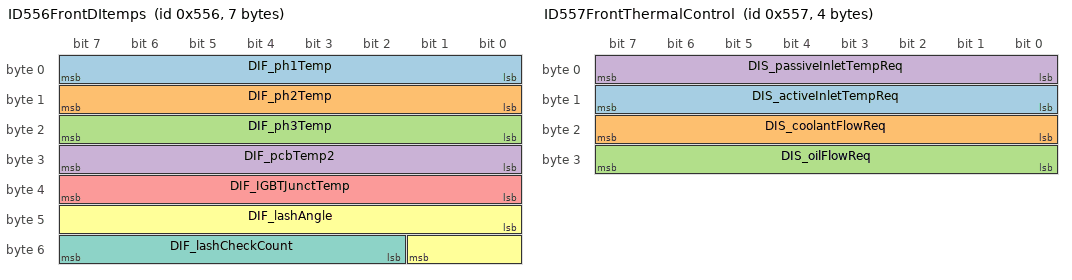
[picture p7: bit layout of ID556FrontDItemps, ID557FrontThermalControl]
BO_ 1366 ID556FrontDItemps: 7 VehicleBus
 SG_ DIF_ph1Temp : 0|8@1+ (1,-40) [-40|120] "C"  Receiver
 SG_ DIF_ph2Temp : 8|8@1+ (1,-40) [-40|120] "C"  Receiver
 SG_ DIF_ph3Temp : 16|8@1+ (1,-40) [-40|120] "C"  Receiver
 SG_ DIF_pcbTemp2 : 24|8@1+ (1,-40) [-40|150] "C"  Receiver
 SG_ DIF_IGBTJunctTemp : 32|8@1+ (1,-40) [-40|200] "C"  Receiver
 SG_ DIF_lashAngle : 40|10@1+ (0.06,0) [0|60] "Deg"  Receiver
 SG_ DIF_lashCheckCount : 50|6@1+ (1,0) [0|63] ""  Receiver

BO_ 1367 ID557FrontThermalControl: 4 VehicleBus
 SG_ DIS_activeInletTempReq : 8|8@1+ (1,-40) [-40|120] "C"  Receiver
 SG_ DIS_coolantFlowReq : 16|8@1+ (0.2,0) [0|50] "LPM"  Receiver
 SG_ DIS_oilFlowReq : 24|8@1+ (0.06,0) [0|15] "LPM"  Receiver
 SG_ DIS_passiveInletTempReq : 0|8@1+ (1,-40) [-40|120] "C"  Receiver

BO_ 1376 GTW_factoryEcuPresent: 4 GTW
 SG_ GTW_BMSpresent : 3|1@1+ (1,0) [0|1] "" ODIN
 SG_ GTW_CMPpresent : 20|1@1+ (1,0) [0|1] "" ODIN
 SG_ GTW_CPpresent : 4|1@1+ (1,0) [0|1] "" ODIN
 SG_ GTW_DASpresent : 21|1@1+ (1,0) [0|1] "" ODIN
 SG_ GTW_DIFpresent : 28|1@1+ (1,0) [0|1] "" ODIN
 SG_ GTW_DIRpresent : 27|1@1+ (1,0) [0|1] "" ODIN
 SG_ GTW_EPAS3Ppresent : 8|1@1+ (1,0) [0|1] "" ODIN
 SG_ GTW_EPAS3Spresent : 19|1@1+ (1,0) [0|1] "" ODIN
 SG_ GTW_EPBLpresent : 9|1@1+ (1,0) [0|1] "" ODIN
 SG_ GTW_EPBRpresent : 10|1@1+ (1,0) [0|1] "" ODIN
 SG_ GTW_ESPpresent : 11|1@1+ (1,0) [0|1] "" ODIN
 SG_ GTW_HVPpresent : 2|1@1+ (1,0) [0|1] "" ODIN
 SG_ GTW_IBSTpresent : 12|1@1+ (1,0) [0|1] "" ODIN
 SG_ GTW_OCS1Ppresent : 0|1@1+ (1,0) [0|1] "" ODIN
 SG_ GTW_PARKpresent : 13|1@1+ (1,0) [0|1] "" ODIN
 SG_ GTW_PCSpresent : 1|1@1+ (1,0) [0|1] "" ODIN
 SG_ GTW_PMFpresent : 26|1@1+ (1,0) [0|1] "" ODIN
 SG_ GTW_PMRpresent : 25|1@1+ (1,0) [0|1] "" ODIN
 SG_ GTW_PTCpresent : 22|1@1+ (1,0) [0|1] "" ODIN
 SG_ GTW_RADCpresent : 14|1@1+ (1,0) [0|1] "" ODIN
 SG_ GTW_RCMpresent : 5|1@1+ (1,0) [0|1] "" ODIN
 SG_ GTW_SCCMpresent : 6|1@1+ (1,0) [0|1] "" ODIN
 SG_ GTW_SWCpresent : 23|1@1+ (1,0) [0|1] "" ODIN
 SG_ GTW_TPMSpresent : 15|1@1+ (1,0) [0|1] "" ODIN
 SG_ GTW_VCFRONTpresent : 16|1@1+ (1,0) [0|1] "" ODIN
 SG_ GTW_VCLEFTpresent : 17|1@1+ (1,0) [0|1] "" ODIN
 SG_ GTW_VCRIGHTpresent : 18|1@1+ (1,0) [0|1] "" ODIN
 SG_ GTW_VCSECpresent : 7|1@1+ (1,0) [0|1] "" ODIN

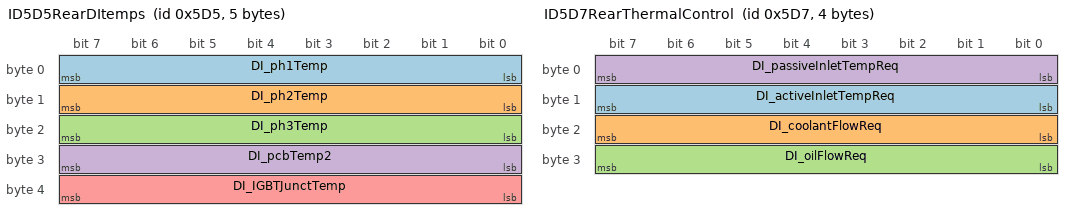
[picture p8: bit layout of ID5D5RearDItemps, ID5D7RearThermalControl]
BO_ 1493 ID5D5RearDItemps: 5 VehicleBus
 SG_ DI_ph1Temp : 0|8@1+ (1,-40) [-40|120] "C"  Receiver
 SG_ DI_ph2Temp : 8|8@1+ (1,-40) [-40|120] "C"  Receiver
 SG_ DI_ph3Temp : 16|8@1+ (1,-40) [-40|120] "C"  Receiver
 SG_ DI_pcbTemp2 : 24|8@1+ (1,-40) [-40|150] "C"  Receiver
 SG_ DI_IGBTJunctTemp : 32|8@1+ (1,-40) [-40|200] "C"  Receiver

BO_ 1495 ID5D7RearThermalControl: 4 VehicleBus
 SG_ DI_activeInletTempReq : 8|8@1+ (1,-40) [-40|120] "C"  Receiver
 SG_ DI_coolantFlowReq : 16|8@1+ (0.2,0) [0|50] "LPM"  Receiver
 SG_ DI_oilFlowReq : 24|8@1+ (0.06,0) [0|15] "LPM"  Receiver
 SG_ DI_passiveInletTempReq : 0|8@1+ (1,-40) [-40|120] "C"  Receiver

BO_ 1519 TPMS_info: 8 CH
 SG_ TPMS_infoIndex M: 0|8@1+ (1,0) [0|0] "" X
 SG_ TPMS_infoComponentID m10: 48|16@1+ (1,0) [0|0] "" X
 SG_ TPMS_infoPcbaID m11: 16|8@1+ (1,0) [0|0] "" X
 SG_ TPMS_infoAssemblyID m11: 24|8@1+ (1,0) [0|0] "" X
 SG_ TPMS_infoUsageID m11: 32|16@1+ (1,0) [0|0] "" X
 SG_ TPMS_infoBootUdsProtoVersion m20: 8|8@1+ (1,0) [0|0] "" X
 SG_ TPMS_infoBootloaderCRC m20: 32|32@1+ (1,0) [0|0] "" X
 SG_ TPMS_infoApplicationCRC m13: 32|32@1+ (1,0) [0|0] "" X

BO_ 1523 UI_alertLog: 8 VEH
 SG_ UI_alertID M: 0|6@1+ (1,0) [0|0] "" X
 SG_ UI_alertState: 15|1@1+ (1,0) [0|0] "" X
 SG_ UI_a034_BackupCamera m34: 16|1@1+ (1,0) [0|0] "" X
 SG_ UI_a034_Tuner m34: 17|1@1+ (1,0) [0|0] "" X
 SG_ UI_a034_Bluetooth m34: 18|1@1+ (1,0) [0|0] "" X
 SG_ UI_a034_WiFi m34: 19|1@1+ (1,0) [0|0] "" X
 SG_ UI_a034_Cellular m34: 20|1@1+ (1,0) [0|0] "" X
 SG_ UI_a034_TouchScreen m34: 21|1@1+ (1,0) [0|0] "" X
 SG_ UI_a034_Display m34: 22|1@1+ (1,0) [0|0] "" X
 SG_ UI_a034_Audio m34: 23|1@1+ (1,0) [0|0] "" X
 SG_ UI_a034_FatalWakeup m34: 24|1@1+ (1,0) [0|0] "" X
 SG_ UI_a034_UnknownWakeupError m34: 25|1@1+ (1,0) [0|0] "" X
 SG_ UI_a006_remoteServiceAlertCode m6: 16|32@1+ (1,0) [0|0] "" X

BO_ 1536 UDS_vcfrontRequest: 8 ODIN
 SG_ UDS_vcfrontRequestData : 0|64@0+ (1,0) [0|18446744073709551615] "" GTW

BO_ 1537 VCFRONT_udsResponse: 8 GTW
 SG_ VCFRONT_udsResponseData : 0|64@0+ (1,0) [0|18446744073709551615] "" ODIN

BO_ 1538 UDS_bmsRequest: 8 ODIN
 SG_ UDS_bmsRequestData : 0|64@0+ (1,0) [0|18446744073709551615] "" GTW

BO_ 1539 UDS_cmpRequest: 8 ODIN
 SG_ UDS_cmpRequestData : 0|64@0+ (1,0) [0|18446744073709551615] "" GTW

BO_ 1540 UDS_pmrRequest: 8 ODIN
 SG_ UDS_pmrRequestData : 0|64@0+ (1,0) [0|18446744073709551615] "" GTW

BO_ 1541 UDS_difRequest: 8 ODIN
 SG_ UDS_difRequestData : 0|64@0+ (1,0) [0|18446744073709551615] "" GTW

BO_ 1542 UDS_dirRequest: 8 ODIN
 SG_ UDS_dirRequestData : 0|64@0+ (1,0) [0|18446744073709551615] "" GTW

BO_ 1543 UDS_cmpdRequest: 8 ODIN
 SG_ UDS_cmpdRequestData : 0|64@0+ (1,0) [0|18446744073709551615] "" GTW

BO_ 1544 UDS_vcrightRequest: 8 ODIN
 SG_ UDS_vcrightRequestData_H : 0|32@0+ (1,0) [0|4294967295] "" GTW
 SG_ UDS_vcrightRequestData_L : 32|32@0+ (1,0) [0|4294967295] "" GTW

BO_ 1545 VCRIGHT_udsResponse: 8 GTW
 SG_ VCRIGHT_udsResponseData_H : 0|32@0+ (1,0) [0|4294967295] "" ODIN
 SG_ VCRIGHT_udsResponseData_L : 32|32@0+ (1,0) [0|4294967295] "" ODIN

BO_ 1546 UDS_vcsecRequest: 8 ODIN
 SG_ UDS_vcsecRequestData : 0|64@0+ (1,0) [0|18446744073709551615] "" GTW

BO_ 1547 VCSEC_udsResponse: 8 GTW
 SG_ VCSEC_udsResponseData : 0|64@0+ (1,0) [0|18446744073709551615] "" ODIN

BO_ 1548 DAS_telemetryRadar: 8 VEH
 SG_ DAS_TR_Counter: 54|2@1+ (1,0) [0|0] "" X
 SG_ DAS_TR_ObjIndex M: 0|5@1+ (1,0) [0|0] "" X
 SG_ DAS_TR_Obj00_Class m0: 5|3@1+ (1,0) [0|0] "" X
 SG_ DAS_TR_Obj00_Dx m0: 8|10@1+ (0.15625,0) [0|0] "m" X
 SG_ DAS_TR_Obj00_Dy m0: 18|6@1+ (0.5,-15.5) [0|0] "m" X
 SG_ DAS_TR_Obj00_Vx m0: 24|8@1+ (0.5,-63.5) [0|0] "m/s" X
 SG_ DAS_TR_Obj00_RCS m0: 32|8@1+ (0.25,-14) [0|0] "dB" X
 SG_ DAS_TR_Obj00_Length m0: 40|6@1+ (0.125,0) [0|0] "m" X
 SG_ DAS_TR_Obj00_MovingState m0: 46|2@1+ (1,0) [0|0] "" X
 SG_ DAS_TR_Obj00_Dz m0: 48|6@1+ (0.25,-5) [0|0] "m" X
 SG_ DAS_TR_Obj00_Exist m0: 56|5@1+ (3.125,0) [0|0] "%" X
 SG_ DAS_TR_Obj01_Class m1: 5|3@1+ (1,0) [0|0] "" X
 SG_ DAS_TR_Obj01_Dx m1: 8|10@1+ (0.15625,0) [0|0] "m" X
 SG_ DAS_TR_Obj01_Dy m1: 18|6@1+ (0.5,-15.5) [0|0] "m" X
 SG_ DAS_TR_Obj01_Vx m1: 24|8@1+ (0.5,-63.5) [0|0] "m/s" X
 SG_ DAS_TR_Obj01_RCS m1: 32|8@1+ (0.25,-14) [0|0] "dB" X
 SG_ DAS_TR_Obj01_Length m1: 40|6@1+ (0.125,0) [0|0] "m" X
 SG_ DAS_TR_Obj01_MovingState m1: 46|2@1+ (1,0) [0|0] "" X
 SG_ DAS_TR_Obj01_Dz m1: 48|6@1+ (0.25,-5) [0|0] "m" X
 SG_ DAS_TR_Obj01_Exist m1: 56|5@1+ (3.125,0) [0|0] "%" X
 SG_ DAS_TR_Obj02_Class m2: 5|3@1+ (1,0) [0|0] "" X
 SG_ DAS_TR_Obj02_Dx m2: 8|10@1+ (0.15625,0) [0|0] "m" X
 SG_ DAS_TR_Obj02_Dy m2: 18|6@1+ (0.5,-15.5) [0|0] "m" X
 SG_ DAS_TR_Obj02_Vx m2: 24|8@1+ (0.5,-63.5) [0|0] "m/s" X
 SG_ DAS_TR_Obj02_RCS m2: 32|8@1+ (0.25,-14) [0|0] "dB" X
 SG_ DAS_TR_Obj02_Length m2: 40|6@1+ (0.125,0) [0|0] "m" X
 SG_ DAS_TR_Obj02_MovingState m2: 46|2@1+ (1,0) [0|0] "" X
 SG_ DAS_TR_Obj02_Dz m2: 48|6@1+ (0.25,-5) [0|0] "m" X
 SG_ DAS_TR_Obj02_Exist m2: 56|5@1+ (3.125,0) [0|0] "%" X
 SG_ DAS_TR_Obj03_Class m3: 5|3@1+ (1,0) [0|0] "" X
 SG_ DAS_TR_Obj03_Dx m3: 8|10@1+ (0.15625,0) [0|0] "m" X
 SG_ DAS_TR_Obj03_Dy m3: 18|6@1+ (0.5,-15.5) [0|0] "m" X
 SG_ DAS_TR_Obj03_Vx m3: 24|8@1+ (0.5,-63.5) [0|0] "m/s" X
 SG_ DAS_TR_Obj03_RCS m3: 32|8@1+ (0.25,-14) [0|0] "dB" X
 SG_ DAS_TR_Obj03_Length m3: 40|6@1+ (0.125,0) [0|0] "m" X
 SG_ DAS_TR_Obj03_MovingState m3: 46|2@1+ (1,0) [0|0] "" X
 SG_ DAS_TR_Obj03_Dz m3: 48|6@1+ (0.25,-5) [0|0] "m" X
 SG_ DAS_TR_Obj03_Exist m3: 56|5@1+ (3.125,0) [0|0] "%" X
 SG_ DAS_TR_Obj04_Class m4: 5|3@1+ (1,0) [0|0] "" X
 SG_ DAS_TR_Obj04_Dx m4: 8|10@1+ (0.15625,0) [0|0] "m" X
 SG_ DAS_TR_Obj04_Dy m4: 18|6@1+ (0.5,-15.5) [0|0] "m" X
 SG_ DAS_TR_Obj04_Vx m4: 24|8@1+ (0.5,-63.5) [0|0] "m/s" X
 SG_ DAS_TR_Obj04_RCS m4: 32|8@1+ (0.25,-14) [0|0] "dB" X
 SG_ DAS_TR_Obj04_Length m4: 40|6@1+ (0.125,0) [0|0] "m" X
 SG_ DAS_TR_Obj04_MovingState m4: 46|2@1+ (1,0) [0|0] "" X
 SG_ DAS_TR_Obj04_Dz m4: 48|6@1+ (0.25,-5) [0|0] "m" X
 SG_ DAS_TR_Obj04_Exist m4: 56|5@1+ (3.125,0) [0|0] "%" X
 SG_ DAS_TR_Obj05_Class m5: 5|3@1+ (1,0) [0|0] "" X
 SG_ DAS_TR_Obj05_Dx m5: 8|10@1+ (0.15625,0) [0|0] "m" X
 SG_ DAS_TR_Obj05_Dy m5: 18|6@1+ (0.5,-15.5) [0|0] "m" X
 SG_ DAS_TR_Obj05_Vx m5: 24|8@1+ (0.5,-63.5) [0|0] "m/s" X
 SG_ DAS_TR_Obj05_RCS m5: 32|8@1+ (0.25,-14) [0|0] "dB" X
 SG_ DAS_TR_Obj05_Length m5: 40|6@1+ (0.125,0) [0|0] "m" X
 SG_ DAS_TR_Obj05_MovingState m5: 46|2@1+ (1,0) [0|0] "" X
 SG_ DAS_TR_Obj05_Dz m5: 48|6@1+ (0.25,-5) [0|0] "m" X
 SG_ DAS_TR_Obj05_Exist m5: 56|5@1+ (3.125,0) [0|0] "%" X
 SG_ DAS_TR_Obj06_Class m6: 5|3@1+ (1,0) [0|0] "" X
 SG_ DAS_TR_Obj06_Dx m6: 8|10@1+ (0.15625,0) [0|0] "m" X
 SG_ DAS_TR_Obj06_Dy m6: 18|6@1+ (0.5,-15.5) [0|0] "m" X
 SG_ DAS_TR_Obj06_Vx m6: 24|8@1+ (0.5,-63.5) [0|0] "m/s" X
 SG_ DAS_TR_Obj06_RCS m6: 32|8@1+ (0.25,-14) [0|0] "dB" X
 SG_ DAS_TR_Obj06_Length m6: 40|6@1+ (0.125,0) [0|0] "m" X
 SG_ DAS_TR_Obj06_MovingState m6: 46|2@1+ (1,0) [0|0] "" X
 SG_ DAS_TR_Obj06_Dz m6: 48|6@1+ (0.25,-5) [0|0] "m" X
 SG_ DAS_TR_Obj06_Exist m6: 56|5@1+ (3.125,0) [0|0] "%" X
 SG_ DAS_TR_Obj07_Class m7: 5|3@1+ (1,0) [0|0] "" X
 SG_ DAS_TR_Obj07_Dx m7: 8|10@1+ (0.15625,0) [0|0] "m" X
 SG_ DAS_TR_Obj07_Dy m7: 18|6@1+ (0.5,-15.5) [0|0] "m" X
 SG_ DAS_TR_Obj07_Vx m7: 24|8@1+ (0.5,-63.5) [0|0] "m/s" X
 SG_ DAS_TR_Obj07_RCS m7: 32|8@1+ (0.25,-14) [0|0] "dB" X
 SG_ DAS_TR_Obj07_Length m7: 40|6@1+ (0.125,0) [0|0] "m" X
 SG_ DAS_TR_Obj07_MovingState m7: 46|2@1+ (1,0) [0|0] "" X
 SG_ DAS_TR_Obj07_Dz m7: 48|6@1+ (0.25,-5) [0|0] "m" X
 SG_ DAS_TR_Obj07_Exist m7: 56|5@1+ (3.125,0) [0|0] "%" X
 SG_ DAS_TR_Obj08_Class m8: 5|3@1+ (1,0) [0|0] "" X
 SG_ DAS_TR_Obj08_Dx m8: 8|10@1+ (0.15625,0) [0|0] "m" X
 SG_ DAS_TR_Obj08_Dy m8: 18|6@1+ (0.5,-15.5) [0|0] "m" X
 SG_ DAS_TR_Obj08_Vx m8: 24|8@1+ (0.5,-63.5) [0|0] "m/s" X
 SG_ DAS_TR_Obj08_RCS m8: 32|8@1+ (0.25,-14) [0|0] "dB" X
 SG_ DAS_TR_Obj08_Length m8: 40|6@1+ (0.125,0) [0|0] "m" X
 SG_ DAS_TR_Obj08_MovingState m8: 46|2@1+ (1,0) [0|0] "" X
 SG_ DAS_TR_Obj08_Dz m8: 48|6@1+ (0.25,-5) [0|0] "m" X
 SG_ DAS_TR_Obj08_Exist m8: 56|5@1+ (3.125,0) [0|0] "%" X
 SG_ DAS_TR_Obj09_Class m9: 5|3@1+ (1,0) [0|0] "" X
 SG_ DAS_TR_Obj09_Dx m9: 8|10@1+ (0.15625,0) [0|0] "m" X
 SG_ DAS_TR_Obj09_Dy m9: 18|6@1+ (0.5,-15.5) [0|0] "m" X
 SG_ DAS_TR_Obj09_Vx m9: 24|8@1+ (0.5,-63.5) [0|0] "m/s" X
 SG_ DAS_TR_Obj09_RCS m9: 32|8@1+ (0.25,-14) [0|0] "dB" X
 SG_ DAS_TR_Obj09_Length m9: 40|6@1+ (0.125,0) [0|0] "m" X
 SG_ DAS_TR_Obj09_MovingState m9: 46|2@1+ (1,0) [0|0] "" X
 SG_ DAS_TR_Obj09_Dz m9: 48|6@1+ (0.25,-5) [0|0] "m" X
 SG_ DAS_TR_Obj09_Exist m9: 56|5@1+ (3.125,0) [0|0] "%" X
 SG_ DAS_TR_Obj10_Class m10: 5|3@1+ (1,0) [0|0] "" X
 SG_ DAS_TR_Obj10_Dx m10: 8|10@1+ (0.15625,0) [0|0] "m" X
 SG_ DAS_TR_Obj10_Dy m10: 18|6@1+ (0.5,-15.5) [0|0] "m" X
 SG_ DAS_TR_Obj10_Vx m10: 24|8@1+ (0.5,-63.5) [0|0] "m/s" X
 SG_ DAS_TR_Obj10_RCS m10: 32|8@1+ (0.25,-14) [0|0] "dB" X
 SG_ DAS_TR_Obj10_Length m10: 40|6@1+ (0.125,0) [0|0] "m" X
 SG_ DAS_TR_Obj10_MovingState m10: 46|2@1+ (1,0) [0|0] "" X
 SG_ DAS_TR_Obj10_Dz m10: 48|6@1+ (0.25,-5) [0|0] "m" X
 SG_ DAS_TR_Obj10_Exist m10: 56|5@1+ (3.125,0) [0|0] "%" X
 SG_ DAS_TR_Obj11_Class m11: 5|3@1+ (1,0) [0|0] "" X
 SG_ DAS_TR_Obj11_Dx m11: 8|10@1+ (0.15625,0) [0|0] "m" X
 SG_ DAS_TR_Obj11_Dy m11: 18|6@1+ (0.5,-15.5) [0|0] "m" X
 SG_ DAS_TR_Obj11_Vx m11: 24|8@1+ (0.5,-63.5) [0|0] "m/s" X
 SG_ DAS_TR_Obj11_RCS m11: 32|8@1+ (0.25,-14) [0|0] "dB" X
 SG_ DAS_TR_Obj11_Length m11: 40|6@1+ (0.125,0) [0|0] "m" X
 SG_ DAS_TR_Obj11_MovingState m11: 46|2@1+ (1,0) [0|0] "" X
 SG_ DAS_TR_Obj11_Dz m11: 48|6@1+ (0.25,-5) [0|0] "m" X
 SG_ DAS_TR_Obj11_Exist m11: 56|5@1+ (3.125,0) [0|0] "%" X
 SG_ DAS_TR_Obj12_Class m12: 5|3@1+ (1,0) [0|0] "" X
 SG_ DAS_TR_Obj12_Dx m12: 8|10@1+ (0.15625,0) [0|0] "m" X
 SG_ DAS_TR_Obj12_Dy m12: 18|6@1+ (0.5,-15.5) [0|0] "m" X
 SG_ DAS_TR_Obj12_Vx m12: 24|8@1+ (0.5,-63.5) [0|0] "m/s" X
 SG_ DAS_TR_Obj12_RCS m12: 32|8@1+ (0.25,-14) [0|0] "dB" X
 SG_ DAS_TR_Obj12_Length m12: 40|6@1+ (0.125,0) [0|0] "m" X
 SG_ DAS_TR_Obj12_MovingState m12: 46|2@1+ (1,0) [0|0] "" X
 SG_ DAS_TR_Obj12_Dz m12: 48|6@1+ (0.25,-5) [0|0] "m" X
 SG_ DAS_TR_Obj12_Exist m12: 56|5@1+ (3.125,0) [0|0] "%" X
 SG_ DAS_TR_Obj13_Class m13: 5|3@1+ (1,0) [0|0] "" X
 SG_ DAS_TR_Obj13_Dx m13: 8|10@1+ (0.15625,0) [0|0] "m" X
 SG_ DAS_TR_Obj13_Dy m13: 18|6@1+ (0.5,-15.5) [0|0] "m" X
 SG_ DAS_TR_Obj13_Vx m13: 24|8@1+ (0.5,-63.5) [0|0] "m/s" X
 SG_ DAS_TR_Obj13_RCS m13: 32|8@1+ (0.25,-14) [0|0] "dB" X
 SG_ DAS_TR_Obj13_Length m13: 40|6@1+ (0.125,0) [0|0] "m" X
 SG_ DAS_TR_Obj13_MovingState m13: 46|2@1+ (1,0) [0|0] "" X
 SG_ DAS_TR_Obj13_Dz m13: 48|6@1+ (0.25,-5) [0|0] "m" X
 SG_ DAS_TR_Obj13_Exist m13: 56|5@1+ (3.125,0) [0|0] "%" X
 SG_ DAS_TR_Obj14_Class m14: 5|3@1+ (1,0) [0|0] "" X
 SG_ DAS_TR_Obj14_Dx m14: 8|10@1+ (0.15625,0) [0|0] "m" X
 SG_ DAS_TR_Obj14_Dy m14: 18|6@1+ (0.5,-15.5) [0|0] "m" X
 SG_ DAS_TR_Obj14_Vx m14: 24|8@1+ (0.5,-63.5) [0|0] "m/s" X
 SG_ DAS_TR_Obj14_RCS m14: 32|8@1+ (0.25,-14) [0|0] "dB" X
 SG_ DAS_TR_Obj14_Length m14: 40|6@1+ (0.125,0) [0|0] "m" X
 SG_ DAS_TR_Obj14_MovingState m14: 46|2@1+ (1,0) [0|0] "" X
 SG_ DAS_TR_Obj14_Dz m14: 48|6@1+ (0.25,-5) [0|0] "m" X
 SG_ DAS_TR_Obj14_Exist m14: 56|5@1+ (3.125,0) [0|0] "%" X
 SG_ DAS_TR_Obj15_Class m15: 5|3@1+ (1,0) [0|0] "" X
 SG_ DAS_TR_Obj15_Dx m15: 8|10@1+ (0.15625,0) [0|0] "m" X
 SG_ DAS_TR_Obj15_Dy m15: 18|6@1+ (0.5,-15.5) [0|0] "m" X
 SG_ DAS_TR_Obj15_Vx m15: 24|8@1+ (0.5,-63.5) [0|0] "m/s" X
 SG_ DAS_TR_Obj15_RCS m15: 32|8@1+ (0.25,-14) [0|0] "dB" X
 SG_ DAS_TR_Obj15_Length m15: 40|6@1+ (0.125,0) [0|0] "m" X
 SG_ DAS_TR_Obj15_MovingState m15: 46|2@1+ (1,0) [0|0] "" X
 SG_ DAS_TR_Obj15_Dz m15: 48|6@1+ (0.25,-5) [0|0] "m" X
 SG_ DAS_TR_Obj15_Exist m15: 56|5@1+ (3.125,0) [0|0] "%" X
 SG_ DAS_TR_Obj16_Class m16: 5|3@1+ (1,0) [0|0] "" X
 SG_ DAS_TR_Obj16_Dx m16: 8|10@1+ (0.15625,0) [0|0] "m" X
 SG_ DAS_TR_Obj16_Dy m16: 18|6@1+ (0.5,-15.5) [0|0] "m" X
 SG_ DAS_TR_Obj16_Vx m16: 24|8@1+ (0.5,-63.5) [0|0] "m/s" X
 SG_ DAS_TR_Obj16_RCS m16: 32|8@1+ (0.25,-14) [0|0] "dB" X
 SG_ DAS_TR_Obj16_Length m16: 40|6@1+ (0.125,0) [0|0] "m" X
 SG_ DAS_TR_Obj16_MovingState m16: 46|2@1+ (1,0) [0|0] "" X
 SG_ DAS_TR_Obj16_Dz m16: 48|6@1+ (0.25,-5) [0|0] "m" X
 SG_ DAS_TR_Obj16_Exist m16: 56|5@1+ (3.125,0) [0|0] "%" X
 SG_ DAS_TR_Obj17_Class m17: 5|3@1+ (1,0) [0|0] "" X
 SG_ DAS_TR_Obj17_Dx m17: 8|10@1+ (0.15625,0) [0|0] "m" X
 SG_ DAS_TR_Obj17_Dy m17: 18|6@1+ (0.5,-15.5) [0|0] "m" X
 SG_ DAS_TR_Obj17_Vx m17: 24|8@1+ (0.5,-63.5) [0|0] "m/s" X
 SG_ DAS_TR_Obj17_RCS m17: 32|8@1+ (0.25,-14) [0|0] "dB" X
 SG_ DAS_TR_Obj17_Length m17: 40|6@1+ (0.125,0) [0|0] "m" X
 SG_ DAS_TR_Obj17_MovingState m17: 46|2@1+ (1,0) [0|0] "" X
 SG_ DAS_TR_Obj17_Dz m17: 48|6@1+ (0.25,-5) [0|0] "m" X
 SG_ DAS_TR_Obj17_Exist m17: 56|5@1+ (3.125,0) [0|0] "%" X
 SG_ DAS_TR_Obj18_Class m18: 5|3@1+ (1,0) [0|0] "" X
 SG_ DAS_TR_Obj18_Dx m18: 8|10@1+ (0.15625,0) [0|0] "m" X
 SG_ DAS_TR_Obj18_Dy m18: 18|6@1+ (0.5,-15.5) [0|0] "m" X
 SG_ DAS_TR_Obj18_Vx m18: 24|8@1+ (0.5,-63.5) [0|0] "m/s" X
 SG_ DAS_TR_Obj18_RCS m18: 32|8@1+ (0.25,-14) [0|0] "dB" X
 SG_ DAS_TR_Obj18_Length m18: 40|6@1+ (0.125,0) [0|0] "m" X
 SG_ DAS_TR_Obj18_MovingState m18: 46|2@1+ (1,0) [0|0] "" X
 SG_ DAS_TR_Obj18_Dz m18: 48|6@1+ (0.25,-5) [0|0] "m" X
 SG_ DAS_TR_Obj18_Exist m18: 56|5@1+ (3.125,0) [0|0] "%" X
 SG_ DAS_TR_Obj19_Class m19: 5|3@1+ (1,0) [0|0] "" X
 SG_ DAS_TR_Obj19_Dx m19: 8|10@1+ (0.15625,0) [0|0] "m" X
 SG_ DAS_TR_Obj19_Dy m19: 18|6@1+ (0.5,-15.5) [0|0] "m" X
 SG_ DAS_TR_Obj19_Vx m19: 24|8@1+ (0.5,-63.5) [0|0] "m/s" X
 SG_ DAS_TR_Obj19_RCS m19: 32|8@1+ (0.25,-14) [0|0] "dB" X
 SG_ DAS_TR_Obj19_Length m19: 40|6@1+ (0.125,0) [0|0] "m" X
 SG_ DAS_TR_Obj19_MovingState m19: 46|2@1+ (1,0) [0|0] "" X
 SG_ DAS_TR_Obj19_Dz m19: 48|6@1+ (0.25,-5) [0|0] "m" X
 SG_ DAS_TR_Obj19_Exist m19: 56|5@1+ (3.125,0) [0|0] "%" X
 SG_ DAS_TR_Obj20_Class m20: 5|3@1+ (1,0) [0|0] "" X
 SG_ DAS_TR_Obj20_Dx m20: 8|10@1+ (0.15625,0) [0|0] "m" X
 SG_ DAS_TR_Obj20_Dy m20: 18|6@1+ (0.5,-15.5) [0|0] "m" X
 SG_ DAS_TR_Obj20_Vx m20: 24|8@1+ (0.5,-63.5) [0|0] "m/s" X
 SG_ DAS_TR_Obj20_RCS m20: 32|8@1+ (0.25,-14) [0|0] "dB" X
 SG_ DAS_TR_Obj20_Length m20: 40|6@1+ (0.125,0) [0|0] "m" X
 SG_ DAS_TR_Obj20_MovingState m20: 46|2@1+ (1,0) [0|0] "" X
 SG_ DAS_TR_Obj20_Dz m20: 48|6@1+ (0.25,-5) [0|0] "m" X
 SG_ DAS_TR_Obj20_Exist m20: 56|5@1+ (3.125,0) [0|0] "%" X
 SG_ DAS_TR_Obj21_Class m21: 5|3@1+ (1,0) [0|0] "" X
 SG_ DAS_TR_Obj21_Dx m21: 8|10@1+ (0.15625,0) [0|0] "m" X
 SG_ DAS_TR_Obj21_Dy m21: 18|6@1+ (0.5,-15.5) [0|0] "m" X
 SG_ DAS_TR_Obj21_Vx m21: 24|8@1+ (0.5,-63.5) [0|0] "m/s" X
 SG_ DAS_TR_Obj21_RCS m21: 32|8@1+ (0.25,-14) [0|0] "dB" X
 SG_ DAS_TR_Obj21_Length m21: 40|6@1+ (0.125,0) [0|0] "m" X
 SG_ DAS_TR_Obj21_MovingState m21: 46|2@1+ (1,0) [0|0] "" X
 SG_ DAS_TR_Obj21_Dz m21: 48|6@1+ (0.25,-5) [0|0] "m" X
 SG_ DAS_TR_Obj21_Exist m21: 56|5@1+ (3.125,0) [0|0] "%" X
 SG_ DAS_TR_Obj22_Class m22: 5|3@1+ (1,0) [0|0] "" X
 SG_ DAS_TR_Obj22_Dx m22: 8|10@1+ (0.15625,0) [0|0] "m" X
 SG_ DAS_TR_Obj22_Dy m22: 18|6@1+ (0.5,-15.5) [0|0] "m" X
 SG_ DAS_TR_Obj22_Vx m22: 24|8@1+ (0.5,-63.5) [0|0] "m/s" X
 SG_ DAS_TR_Obj22_RCS m22: 32|8@1+ (0.25,-14) [0|0] "dB" X
 SG_ DAS_TR_Obj22_Length m22: 40|6@1+ (0.125,0) [0|0] "m" X
 SG_ DAS_TR_Obj22_MovingState m22: 46|2@1+ (1,0) [0|0] "" X
 SG_ DAS_TR_Obj22_Dz m22: 48|6@1+ (0.25,-5) [0|0] "m" X
 SG_ DAS_TR_Obj22_Exist m22: 56|5@1+ (3.125,0) [0|0] "%" X
 SG_ DAS_TR_Obj23_Class m23: 5|3@1+ (1,0) [0|0] "" X
 SG_ DAS_TR_Obj23_Dx m23: 8|10@1+ (0.15625,0) [0|0] "m" X
 SG_ DAS_TR_Obj23_Dy m23: 18|6@1+ (0.5,-15.5) [0|0] "m" X
 SG_ DAS_TR_Obj23_Vx m23: 24|8@1+ (0.5,-63.5) [0|0] "m/s" X
 SG_ DAS_TR_Obj23_RCS m23: 32|8@1+ (0.25,-14) [0|0] "dB" X
 SG_ DAS_TR_Obj23_Length m23: 40|6@1+ (0.125,0) [0|0] "m" X
 SG_ DAS_TR_Obj23_MovingState m23: 46|2@1+ (1,0) [0|0] "" X
 SG_ DAS_TR_Obj23_Dz m23: 48|6@1+ (0.25,-5) [0|0] "m" X
 SG_ DAS_TR_Obj23_Exist m23: 56|5@1+ (3.125,0) [0|0] "%" X
 SG_ DAS_TR_Obj24_Class m24: 5|3@1+ (1,0) [0|0] "" X
 SG_ DAS_TR_Obj24_Dx m24: 8|10@1+ (0.15625,0) [0|0] "m" X
 SG_ DAS_TR_Obj24_Dy m24: 18|6@1+ (0.5,-15.5) [0|0] "m" X
 SG_ DAS_TR_Obj24_Vx m24: 24|8@1+ (0.5,-63.5) [0|0] "m/s" X
 SG_ DAS_TR_Obj24_RCS m24: 32|8@1+ (0.25,-14) [0|0] "dB" X
 SG_ DAS_TR_Obj24_Length m24: 40|6@1+ (0.125,0) [0|0] "m" X
 SG_ DAS_TR_Obj24_MovingState m24: 46|2@1+ (1,0) [0|0] "" X
 SG_ DAS_TR_Obj24_Dz m24: 48|6@1+ (0.25,-5) [0|0] "m" X
 SG_ DAS_TR_Obj24_Exist m24: 56|5@1+ (3.125,0) [0|0] "%" X
 SG_ DAS_TR_Obj25_Class m25: 5|3@1+ (1,0) [0|0] "" X
 SG_ DAS_TR_Obj25_Dx m25: 8|10@1+ (0.15625,0) [0|0] "m" X
 SG_ DAS_TR_Obj25_Dy m25: 18|6@1+ (0.5,-15.5) [0|0] "m" X
 SG_ DAS_TR_Obj25_Vx m25: 24|8@1+ (0.5,-63.5) [0|0] "m/s" X
 SG_ DAS_TR_Obj25_RCS m25: 32|8@1+ (0.25,-14) [0|0] "dB" X
 SG_ DAS_TR_Obj25_Length m25: 40|6@1+ (0.125,0) [0|0] "m" X
 SG_ DAS_TR_Obj25_MovingState m25: 46|2@1+ (1,0) [0|0] "" X
 SG_ DAS_TR_Obj25_Dz m25: 48|6@1+ (0.25,-5) [0|0] "m" X
 SG_ DAS_TR_Obj25_Exist m25: 56|5@1+ (3.125,0) [0|0] "%" X
 SG_ DAS_TR_Obj26_Class m26: 5|3@1+ (1,0) [0|0] "" X
 SG_ DAS_TR_Obj26_Dx m26: 8|10@1+ (0.15625,0) [0|0] "m" X
 SG_ DAS_TR_Obj26_Dy m26: 18|6@1+ (0.5,-15.5) [0|0] "m" X
 SG_ DAS_TR_Obj26_Vx m26: 24|8@1+ (0.5,-63.5) [0|0] "m/s" X
 SG_ DAS_TR_Obj26_RCS m26: 32|8@1+ (0.25,-14) [0|0] "dB" X
 SG_ DAS_TR_Obj26_Length m26: 40|6@1+ (0.125,0) [0|0] "m" X
 SG_ DAS_TR_Obj26_MovingState m26: 46|2@1+ (1,0) [0|0] "" X
 SG_ DAS_TR_Obj26_Dz m26: 48|6@1+ (0.25,-5) [0|0] "m" X
 SG_ DAS_TR_Obj26_Exist m26: 56|5@1+ (3.125,0) [0|0] "%" X
 SG_ DAS_TR_Obj27_Class m27: 5|3@1+ (1,0) [0|0] "" X
 SG_ DAS_TR_Obj27_Dx m27: 8|10@1+ (0.15625,0) [0|0] "m" X
 SG_ DAS_TR_Obj27_Dy m27: 18|6@1+ (0.5,-15.5) [0|0] "m" X
 SG_ DAS_TR_Obj27_Vx m27: 24|8@1+ (0.5,-63.5) [0|0] "m/s" X
 SG_ DAS_TR_Obj27_RCS m27: 32|8@1+ (0.25,-14) [0|0] "dB" X
 SG_ DAS_TR_Obj27_Length m27: 40|6@1+ (0.125,0) [0|0] "m" X
 SG_ DAS_TR_Obj27_MovingState m27: 46|2@1+ (1,0) [0|0] "" X
 SG_ DAS_TR_Obj27_Dz m27: 48|6@1+ (0.25,-5) [0|0] "m" X
 SG_ DAS_TR_Obj27_Exist m27: 56|5@1+ (3.125,0) [0|0] "%" X
 SG_ DAS_TR_Obj28_Class m28: 5|3@1+ (1,0) [0|0] "" X
 SG_ DAS_TR_Obj28_Dx m28: 8|10@1+ (0.15625,0) [0|0] "m" X
 SG_ DAS_TR_Obj28_Dy m28: 18|6@1+ (0.5,-15.5) [0|0] "m" X
 SG_ DAS_TR_Obj28_Vx m28: 24|8@1+ (0.5,-63.5) [0|0] "m/s" X
 SG_ DAS_TR_Obj28_RCS m28: 32|8@1+ (0.25,-14) [0|0] "dB" X
 SG_ DAS_TR_Obj28_Length m28: 40|6@1+ (0.125,0) [0|0] "m" X
 SG_ DAS_TR_Obj28_MovingState m28: 46|2@1+ (1,0) [0|0] "" X
 SG_ DAS_TR_Obj28_Dz m28: 48|6@1+ (0.25,-5) [0|0] "m" X
 SG_ DAS_TR_Obj28_Exist m28: 56|5@1+ (3.125,0) [0|0] "%" X
 SG_ DAS_TR_Obj29_Class m29: 5|3@1+ (1,0) [0|0] "" X
 SG_ DAS_TR_Obj29_Dx m29: 8|10@1+ (0.15625,0) [0|0] "m" X
 SG_ DAS_TR_Obj29_Dy m29: 18|6@1+ (0.5,-15.5) [0|0] "m" X
 SG_ DAS_TR_Obj29_Vx m29: 24|8@1+ (0.5,-63.5) [0|0] "m/s" X
 SG_ DAS_TR_Obj29_RCS m29: 32|8@1+ (0.25,-14) [0|0] "dB" X
 SG_ DAS_TR_Obj29_Length m29: 40|6@1+ (0.125,0) [0|0] "m" X
 SG_ DAS_TR_Obj29_MovingState m29: 46|2@1+ (1,0) [0|0] "" X
 SG_ DAS_TR_Obj29_Dz m29: 48|6@1+ (0.25,-5) [0|0] "m" X
 SG_ DAS_TR_Obj29_Exist m29: 56|5@1+ (3.125,0) [0|0] "%" X
 SG_ DAS_TR_Obj30_Class m30: 5|3@1+ (1,0) [0|0] "" X
 SG_ DAS_TR_Obj30_Dx m30: 8|10@1+ (0.15625,0) [0|0] "m" X
 SG_ DAS_TR_Obj30_Dy m30: 18|6@1+ (0.5,-15.5) [0|0] "m" X
 SG_ DAS_TR_Obj30_Vx m30: 24|8@1+ (0.5,-63.5) [0|0] "m/s" X
 SG_ DAS_TR_Obj30_RCS m30: 32|8@1+ (0.25,-14) [0|0] "dB" X
 SG_ DAS_TR_Obj30_Length m30: 40|6@1+ (0.125,0) [0|0] "m" X
 SG_ DAS_TR_Obj30_MovingState m30: 46|2@1+ (1,0) [0|0] "" X
 SG_ DAS_TR_Obj30_Dz m30: 48|6@1+ (0.25,-5) [0|0] "m" X
 SG_ DAS_TR_Obj30_Exist m30: 56|5@1+ (3.125,0) [0|0] "%" X
 SG_ DAS_TR_Obj31_Class m31: 5|3@1+ (1,0) [0|0] "" X
 SG_ DAS_TR_Obj31_Dx m31: 8|10@1+ (0.15625,0) [0|0] "m" X
 SG_ DAS_TR_Obj31_Dy m31: 18|6@1+ (0.5,-15.5) [0|0] "m" X
 SG_ DAS_TR_Obj31_Vx m31: 24|8@1+ (0.5,-63.5) [0|0] "m/s" X
 SG_ DAS_TR_Obj31_RCS m31: 32|8@1+ (0.25,-14) [0|0] "dB" X
 SG_ DAS_TR_Obj31_Length m31: 40|6@1+ (0.125,0) [0|0] "m" X
 SG_ DAS_TR_Obj31_MovingState m31: 46|2@1+ (1,0) [0|0] "" X
 SG_ DAS_TR_Obj31_Dz m31: 48|6@1+ (0.25,-5) [0|0] "m" X
 SG_ DAS_TR_Obj31_Exist m31: 56|5@1+ (3.125,0) [0|0] "%" X

BO_ 1550 UDS_cpRequest: 8 ODIN
 SG_ UDS_cpRequestData : 0|64@0+ (1,0) [0|18446744073709551615] "" GTW

BO_ 1551 UDS_thcRequest: 8 ODIN
 SG_ UDS_thcRequestData_H : 0|32@0+ (1,0) [0|4294967295] "" XXX
 SG_ UDS_thcRequestData_L : 32|32@0+ (1,0) [0|4294967295] "" XXX

BO_ 1552 UDS_hvpRequest: 8 ODIN
 SG_ UDS_hvpRequestData : 0|64@0+ (1,0) [0|18446744073709551615] "" GTW

BO_ 1553 HVP_udsResponse: 8 GTW
 SG_ HVP_udsResponseData : 0|64@0+ (1,0) [0|18446744073709551615] "" GTWU,ODIN

BO_ 1554 BMS_udsResponse: 8 GTW
 SG_ BMS_udsResponseData : 0|64@0+ (1,0) [0|18446744073709551615] "" ODIN

BO_ 1555 CMP_udsResponse: 8 GTW
 SG_ CMP_udsResponseData : 0|64@0+ (1,0) [0|18446744073709551615] "" ODIN

BO_ 1556 PMR_udsResponse: 8 GTW
 SG_ PMR_udsResponseData : 0|64@0+ (1,0) [0|18446744073709551615] "" ODIN

BO_ 1557 DIF_udsResponse: 8 GTW
 SG_ DIF_udsResponseData : 0|64@0+ (1,0) [0|18446744073709551615] "" ODIN

BO_ 1558 DIR_udsResponse: 8 GTW
 SG_ DIR_udsResponseData : 0|64@0+ (1,0) [0|18446744073709551615] "" ODIN

BO_ 1559 CMPD_udsResponse: 8 GTW
 SG_ CMPD_udsResponseData : 0|64@0+ (1,0) [0|18446744073709551615] "" ODIN

BO_ 1560 UDS_icrRequest: 8 ODIN
 SG_ UDS_icrRequestData : 0|64@0+ (1,0) [0|18446744073709551615] "" GTW

BO_ 1566 CP_udsResponse: 8 GTW
 SG_ CP_udsResponseData : 0|64@0+ (1,0) [0|18446744073709551615] "" GTWU,ODIN

BO_ 1568 UDS_pmRequest: 8 ODIN
 SG_ UDS_pmRequestData : 0|64@0+ (1,0) [0|18446744073709551615] "" GTW

BO_ 1570 UDS_vcleftRequest: 8 ODIN
 SG_ UDS_vcleftRequestData_H : 0|32@0+ (1,0) [0|4294967295] "" GTW
 SG_ UDS_vcleftRequestData_L : 32|32@0+ (1,0) [0|4294967295] "" GTW

BO_ 1571 VCLEFT_udsResponse: 8 GTW
 SG_ VCLEFT_udsResponseData_H : 0|32@0+ (1,0) [0|4294967295] "" ODIN
 SG_ VCLEFT_udsResponseData_L : 32|32@0+ (1,0) [0|4294967295] "" ODIN

BO_ 1572 UDS_epblRequest: 8 ODIN
 SG_ UDS_epblRequestData_H : 0|32@0+ (1,0) [0|4294967295] "" GTW
 SG_ UDS_epblRequestData_L : 32|32@0+ (1,0) [0|4294967295] "" GTW

BO_ 1573 EPBL_udsResponse: 8 GTW
 SG_ EPBL_udsResponseData_H : 0|32@0+ (1,0) [0|4294967295] "" ODIN
 SG_ EPBL_udsResponseData_L : 32|32@0+ (1,0) [0|4294967295] "" ODIN

BO_ 1574 UDS_epbrRequest: 8 ODIN
 SG_ UDS_epbrRequestData_H : 0|32@0+ (1,0) [0|4294967295] "" GTW
 SG_ UDS_epbrRequestData_L : 32|32@0+ (1,0) [0|4294967295] "" GTW

BO_ 1575 EPBR_udsResponse: 8 GTW
 SG_ EPBR_udsResponseData_H : 0|32@0+ (1,0) [0|4294967295] "" ODIN
 SG_ EPBR_udsResponseData_L : 32|32@0+ (1,0) [0|4294967295] "" ODIN

BO_ 1576 UDS_pcsRequest: 8 ODIN
 SG_ UDS_pcsRequestData : 0|64@0+ (1,0) [0|18446744073709551615] "" GTW

BO_ 1577 PCS_udsResponse: 8 GTW
 SG_ PCS_udsResponseData : 0|64@0+ (1,0) [0|18446744073709551615] "" GTWU,ODIN

BO_ 1579 UDS_ccRequest: 8 ODIN
 SG_ UDS_ccRequestData : 0|64@0+ (1,0) [0|18446744073709551615] "" GTW

BO_ 1584 UDS_epas3pRequest: 8 ODIN
 SG_ UDS_epas3pRequestData : 0|64@0+ (1,0) [0|18446744073709551615] "" GTW

BO_ 1589 UDS_diRequest: 8 ODIN
 SG_ UDS_diRequestData : 0|64@0+ (1,0) [0|18446744073709551615] "" GTW

BO_ 1592 EPAS3P_udsResponseCH: 8 GTW
 SG_ EPAS3P_udsResponseDataCH : 0|64@0+ (1,0) [0|18446744073709551615] "" ODIN

BO_ 1600 PM_udsResponse: 8 GTW
 SG_ PM_udsResponseData : 0|64@0+ (1,0) [0|18446744073709551615] "" ODIN

BO_ 1601 UDS_rcmRequest: 8 ODIN
 SG_ UDS_rcmRequestData : 0|64@0+ (1,0) [0|18446744073709551615] "" GTW

BO_ 1603 UDS_ocs1pRequest: 8 ODIN
 SG_ UDS_ocs1pRequestData : 0|64@0+ (1,0) [0|18446744073709551615] "" GTW

BO_ 1604 UDS_pmfRequest: 8 ODIN
 SG_ UDS_pmfRequestData : 0|64@0+ (1,0) [0|18446744073709551615] "" GTW

BO_ 1605 UDS_espRequest: 8 ODIN
 SG_ UDS_espRequestData : 0|64@0+ (1,0) [0|18446744073709551615] "" GTW

BO_ 1609 UDS_dasRequest: 8 ODIN
 SG_ UDS_dasRequestData : 0|64@0+ (1,0) [0|18446744073709551615] "" GTW

BO_ 1611 UDS_tasRequest: 8 ODIN
 SG_ UDS_tasRequestData : 0|64@0+ (1,0) [0|18446744073709551615] "" GTW

BO_ 1613 UDS_ibstRequest: 8 ODIN
 SG_ UDS_ibstRequestData : 0|64@0+ (1,0) [0|18446744073709551615] "" GTW

BO_ 1614 UDS_parkRequest: 8 ODIN
 SG_ UDS_parkRequestData : 0|64@0+ (1,0) [0|18446744073709551615] "" GTW

BO_ 1615 UDS_tpmsRequest: 8 ODIN
 SG_ UDS_tpmsRequestData : 0|64@0+ (1,0) [0|18446744073709551615] "" GTW

BO_ 1617 RCM_udsResponse: 8 GTW
 SG_ RCM_udsResponseData : 0|64@0+ (1,0) [0|18446744073709551615] "" ODIN

BO_ 1619 OCS1P_udsResponse: 8 GTW
 SG_ OCS1P_udsResponseData : 0|64@1+ (1,0) [0|18446744073709551615] "" ODIN

BO_ 1620 PMF_udsResponse: 8 GTW
 SG_ PMF_udsResponseData : 0|64@0+ (1,0) [0|18446744073709551615] "" ODIN

BO_ 1621 ESP_udsResponse: 8 GTW
 SG_ ESP_udsResponseData : 0|64@0+ (1,0) [0|18446744073709551615] "" ODIN

BO_ 1622 ID656FrontDIinfo: 8 VehicleBus
 SG_ DIF_infoIndex M : 0|8@1+ (1,0) [0|255] ""  Receiver
 SG_ DIF_FPGA_version m16 : 48|8@1+ (1,0) [0|255] ""  Receiver
 SG_ DIF_appGitHash m17 : 8|56@1+ (1,0) [0|7.20576E+016] ""  Receiver
 SG_ DIF_applicationCrc m13 : 32|32@1+ (1,0) [0|4294970000] ""  Receiver
 SG_ DIF_assemblyId m11 : 24|8@1+ (1,0) [0|255] ""  Receiver
 SG_ DIF_bootGitHash m18 : 8|56@1+ (1,0) [0|7.20576E+016] ""  Receiver
 SG_ DIF_bootloaderCrc m20 : 32|32@1+ (1,0) [0|4294970000] ""  Receiver
 SG_ DIF_buildConfigurationId m10 : 16|16@1+ (1,0) [0|65535] ""  Receiver
 SG_ DIF_buildType m10 : 8|3@1+ (1,0) [0|4] ""  Receiver
 SG_ DIF_componentId m10 : 48|16@1+ (1,0) [0|65535] ""  Receiver
 SG_ DIF_hardwareId m10 : 32|8@1+ (1,0) [0|252] ""  Receiver
 SG_ DIF_infoBootLdUdsProtocolVersion m20 : 8|8@1+ (1,0) [0|255] ""  Receiver
 SG_ DIF_oilPumpAppCrc m16 : 16|32@1+ (1,0) [0|4294970000] ""  Receiver
 SG_ DIF_oilPumpBuildType m16 : 8|3@1+ (1,0) [0|4] ""  Receiver
 SG_ DIF_pcbaId m11 : 16|8@1+ (1,0) [0|255] ""  Receiver
 SG_ DIF_platformTyp m19 : 8|8@1+ (1,0) [0|255] ""  Receiver
 SG_ DIF_subUsageId m11 : 48|16@1+ (1,0) [0|65535] ""  Receiver
 SG_ DIF_subcomponentGitHash m31 : 8|56@1+ (1,0) [0|7.20576E+016] ""  Receiver
 SG_ DIF_usageId m11 : 32|16@1+ (1,0) [0|65535] ""  Receiver

BO_ 1624 ICR_udsResponse: 8 GTW
 SG_ ICR_udsResponseData : 0|64@0+ (1,0) [0|18446744073709551615] "" ODIN

BO_ 1625 DAS_udsResponse: 8 GTW
 SG_ DAS_udsResponseData : 0|64@0+ (1,0) [0|18446744073709551615] "" ODIN

BO_ 1627 TAS_udsResponse: 8 GTW
 SG_ TAS_udsResponseData : 0|64@0+ (1,0) [0|18446744073709551615] "" ODIN

BO_ 1629 IBST_udsResponse: 8 GTW
 SG_ IBST_udsResponseData : 0|64@0+ (1,0) [0|18446744073709551615] "" ODIN

BO_ 1630 PARK_udsResponse: 8 GTW
 SG_ PARK_udsResponseData : 0|64@1+ (1,0) [0|18446744073709551615] "" ODIN

BO_ 1631 TPMS_udsResponse: 8 GTW
 SG_ TPMS_udsResponseData : 0|64@0+ (1,0) [0|18446744073709551615] "" ODIN

BO_ 1634 UDS_plgRequest: 8 ODIN
 SG_ UDS_plgRequestData : 0|64@0+ (1,0) [0|18446744073709551615] "" GTW

BO_ 1635 PLG_udsResponse: 8 GTW
 SG_ PLG_udsResponseData : 0|64@0+ (1,0) [0|18446744073709551615] "" ODIN

BO_ 1638 GTW_diagSession: 4 GTW
 SG_ GTW_diagLevel : 17|7@1+ (1,0) [0|100] "" ODIN,SUI,UI
 SG_ GTW_diagRemainingSeconds : 0|16@1+ (1,0) [0|65535] "seconds" ODIN,SUI,UI

BO_ 1641 UDS_KOSTIAsccmRequest: 8 ODIN
 SG_ UDS_KOSTIAsccmRequestData : 0|64@0+ (1,0) [0|18446744073709551615] "" GTW

BO_ 1649 UDS_radcRequest: 8 ODIN
 SG_ UDS_radcRequestData : 0|64@0+ (1,0) [0|18446744073709551615] "" GTW

BO_ 1655 VC_LVBMS_statusHigh: 8 GTW
 SG_ VC_LVBMS_MOSState : 10|2@1+ (1,0) [0|3] "" ODIN,SUI,UI,VITALS
 SG_ VC_LVBMS_packCurrent : 3|22@1+ (0.001,-2000) [-2000.0|2194.302] "A" ODIN,SUI,UI,VITALS
 SG_ VC_LVBMS_packVoltage : 25|16@1+ (0.001,0) [0.0|65.534] "V" ODIN,SUI,UI,VITALS
 SG_ VC_lvbmsStatusHighIndex : 0|3@1+ (1,0) [0|6] "" XXX

BO_ 1664 UDS_sccmRequest: 8 ODIN
 SG_ UDS_sccmRequestData : 0|64@0+ (1,0) [0|18446744073709551615] "" GTW

BO_ 1665 RADC_udsResponse: 8 GTW
 SG_ RADC_udsResponseData : 0|64@0+ (1,0) [0|18446744073709551615] "" GTWU,ODIN

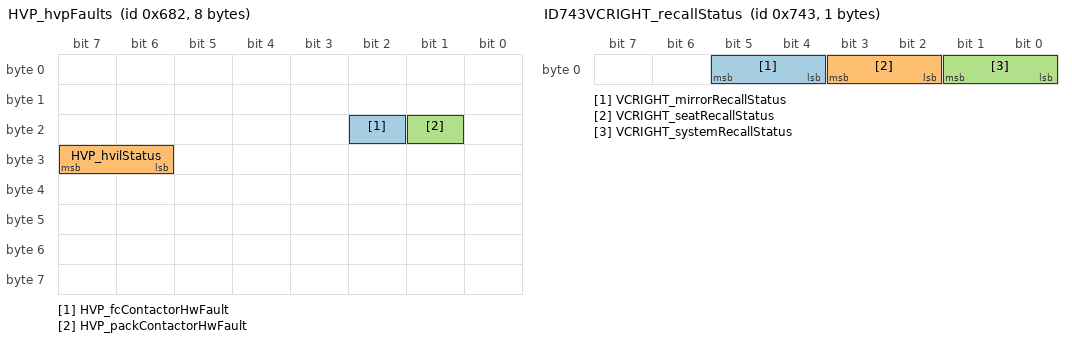
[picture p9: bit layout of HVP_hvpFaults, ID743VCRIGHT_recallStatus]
BO_ 1666 HVP_hvpFaults: 8 GTW
 SG_ HVP_fcContactorHwFault : 18|1@1+ (1,0) [0|1] "" ODIN
 SG_ HVP_hvilStatus : 30|2@1+ (1,0) [0|2] "" ODIN,SUI
 SG_ HVP_packContactorHwFault : 17|1@1+ (1,0) [0|1] "" ODIN

BO_ 1680 SCCM_udsResponse: 8 GTW
 SG_ SCCM_functionalResponseData_0 : 0|8@0+ (1,0) [0|255] "" ODIN
 SG_ SCCM_functionalResponseData_1 : 8|8@0+ (1,0) [0|255] "" ODIN
 SG_ SCCM_functionalResponseData_2 : 16|8@0+ (1,0) [0|255] "" ODIN
 SG_ SCCM_functionalResponseData_3 : 24|8@0+ (1,0) [0|255] "" ODIN
 SG_ SCCM_functionalResponseData_4 : 32|8@0+ (1,0) [0|255] "" ODIN
 SG_ SCCM_functionalResponseData_5 : 40|8@0+ (1,0) [0|255] "" ODIN
 SG_ SCCM_functionalResponseData_6 : 48|8@0+ (1,0) [0|255] "" ODIN
 SG_ SCCM_functionalResponseData_7 : 56|8@0+ (1,0) [0|255] "" ODIN

BO_ 1723 UDS_sdcrRequest: 8 ODIN
 SG_ UDS_sdcrRequestData : 0|64@0+ (1,0) [0|18446744073709551615] "" GTW

BO_ 1734 UDS_ptcRequest: 8 ODIN
 SG_ UDS_ptcRequestData : 0|64@0+ (1,0) [0|18446744073709551615] "" GTW

BO_ 1748 PMS_info: 8 VEH
 SG_ PMS_infoIndex M: 0|8@1+ (1,0) [0|0] "" X
 SG_ PMS_buildType m10: 8|8@1+ (1,0) [0|0] "" X
 SG_ PMS_buildConfigurationId m10: 16|16@1+ (1,0) [0|0] "" X
 SG_ PMS_hardwareId m10: 32|8@1+ (1,0) [0|0] "" X
 SG_ PMS_componentId m10: 48|16@1+ (1,0) [0|0] "" X
 SG_ PMS_pcbaId m11: 16|8@1+ (1,0) [0|0] "" X
 SG_ PMS_assemblyId m11: 24|8@1+ (1,0) [0|0] "" X
 SG_ PMS_usageId m11: 32|16@1+ (1,0) [0|0] "" X
 SG_ PMS_subUsageId m11: 48|16@1+ (1,0) [0|0] "" X
 SG_ PMS_applicationCrc m13: 32|32@1+ (1,0) [0|0] "" X
 SG_ PMS_bootloaderSvnRevision m14: 8|24@1+ (1,0) [0|0] "" X
 SG_ PMS_bootloaderSvnUrlHash m14: 32|32@1+ (1,0) [0|0] "" X
 SG_ PMS_appGitHash m17: 10|54@1+ (4,0) [0|0] "" X
 SG_ PMS_bootGitHash m18: 10|54@1+ (4,0) [0|0] "" X
 SG_ PMS_platformTyp m19: 8|8@1+ (1,0) [0|0] "" X
 SG_ PMS_udsProtocolVersion m20: 8|8@1+ (1,0) [0|0] "" X
 SG_ PMS_bootloaderCrc m20: 32|32@1+ (1,0) [0|0] "" X

BO_ 1750 PTC_udsResponse: 8 GTW
 SG_ PTC_udsResponseData : 0|64@0+ (1,0) [0|18446744073709551615] "" ODIN

BO_ 1787 SDCR_udsResponse: 8 GTW
 SG_ SDCR_udsResponseData : 0|64@0+ (1,0) [0|18446744073709551615] "" ODIN

BO_ 1795 VCRIGHT_debugThermal10Hz: 8 VEH
 SG_ VCRIGHT_debugThermal10HzIndex M: 0|3@1+ (1,0) [0|0] "" X
 SG_ VCRIGHT_wattsDemandEvapFeedback m0: 3|9@1- (20,0) [0|0] "W" X
 SG_ VCRIGHT_wattsDemandEvapFeedfwd m0: 12|9@1+ (20,0) [0|0] "W" X
 SG_ VCRIGHT_wattsHeaterLeftFeedback m0: 21|9@1- (20,0) [0|0] "W" X
 SG_ VCRIGHT_wattsHeaterLeftFeedfwd m0: 30|9@1+ (20,0) [0|0] "W" X
 SG_ VCRIGHT_wattsHeaterRightFeedback m0: 39|9@1- (20,0) [0|0] "W" X
 SG_ VCRIGHT_wattsHeaterRightFeedfwd m0: 48|9@1+ (20,0) [0|0] "W" X
 SG_ VCRIGHT_tempEvapAdjustmentLeft m1: 8|7@1+ (0.1,0) [0|0] "degC" X
 SG_ VCRIGHT_tempEvapAdjustmentRight m1: 16|7@1+ (0.1,0) [0|0] "degC" X
 SG_ VCRIGHT_hvacPanelFloorSplitRow1 m2: 8|8@1+ (0.4,0) [0|0] "%" X
 SG_ VCRIGHT_hvacDefrostPercent m2: 16|8@1+ (0.4,0) [0|0] "%" X
 SG_ VCRIGHT_hvacRow2Percent m2: 24|8@1+ (0.4,0) [0|0] "%" X
 SG_ VCRIGHT_hvacPanelFloorSplitRow2 m2: 32|8@1+ (0.4,0) [0|0] "%" X
 SG_ VCRIGHT_cabinTempThs m3: 8|8@1+ (0.5,-40) [0|0] "degC" X
 SG_ VCRIGHT_cabinTempThsBracket m3: 16|8@1+ (0.5,-40) [0|0] "degC" X
 SG_ VCRIGHT_cabinTempProbe m3: 24|8@1+ (0.5,-40) [0|0] "degC" X
 SG_ VCRIGHT_setTempAdjustmentLeft m3: 32|7@1+ (0.1,0) [0|0] "degC" X
 SG_ VCRIGHT_setTempAdjustmentRight m3: 40|7@1+ (0.1,0) [0|0] "degC" X
 SG_ VCRIGHT_hvacLHBleedCalibrated m4: 3|1@1+ (1,0) [0|0] "" X
 SG_ VCRIGHT_hvacActuatorsCalibrated m4: 4|1@1+ (1,0) [0|0] "" X
 SG_ VCRIGHT_hvacRHBleedCalibrated m4: 7|1@1+ (1,0) [0|0] "" X
 SG_ VCRIGHT_hvacLHVaneCalibrated m4: 11|1@1+ (1,0) [0|0] "" X
 SG_ VCRIGHT_hvacRHVaneCalibrated m4: 15|1@1+ (1,0) [0|0] "" X
 SG_ VCRIGHT_hvacUpperModeCalibrated m4: 19|1@1+ (1,0) [0|0] "" X
 SG_ VCRIGHT_hvacLowerModeCalibrated m4: 23|1@1+ (1,0) [0|0] "" X
 SG_ VCRIGHT_hvacIntakeCalibrated m4: 27|1@1+ (1,0) [0|0] "" X

BO_ 1816 VC_LVBMS_statusLow: 7 GTW
 SG_ VC_LVBMS_SOC : 8|7@1+ (1,0) [0|126] "%" ODIN,SUI,UI,VITALS
 SG_ VC_lvbmsStatusLowIndex : 0|3@1+ (1,0) [0|6] "" XXX

BO_ 1834 ID72ABMS_serialNumber: 8 VehicleBus
 SG_ BMS_packSerialNumberByte01 m0 : 8|8@1+ (1,0) [0|255] ""  Receiver
 SG_ BMS_packSerialNumberByte02 m0 : 16|8@1+ (1,0) [0|255] ""  Receiver
 SG_ BMS_packSerialNumberByte03 m0 : 24|8@1+ (1,0) [0|255] ""  Receiver
 SG_ BMS_packSerialNumberByte04 m0 : 32|8@1+ (1,0) [0|255] ""  Receiver
 SG_ BMS_packSerialNumberByte05 m0 : 40|8@1+ (1,0) [0|255] ""  Receiver
 SG_ BMS_packSerialNumberByte06 m0 : 48|8@1+ (1,0) [0|255] ""  Receiver
 SG_ BMS_packSerialNumberByte07 m0 : 56|8@1+ (1,0) [0|255] ""  Receiver
 SG_ BMS_packSerialNumberByte08 m1 : 8|8@1+ (1,0) [0|255] ""  Receiver
 SG_ BMS_packSerialNumberByte09 m1 : 16|8@1+ (1,0) [0|255] ""  Receiver
 SG_ BMS_packSerialNumberByte10 m1 : 24|8@1+ (1,0) [0|255] ""  Receiver
 SG_ BMS_packSerialNumberByte11 m1 : 32|8@1+ (1,0) [0|255] ""  Receiver
 SG_ BMS_packSerialNumberByte12 m1 : 40|8@1+ (1,0) [0|255] ""  Receiver
 SG_ BMS_packSerialNumberByte13 m1 : 48|8@1+ (1,0) [0|255] ""  Receiver
 SG_ BMS_packSerialNumberByte14 m1 : 56|8@1+ (1,0) [0|255] ""  Receiver
 SG_ BMS_serialNumberMultiplexer M : 0|1@1+ (1,0) [0|1] ""  Receiver

BO_ 1840 UDS_epas3sRequest: 8 ODIN
 SG_ UDS_epas3sRequestData : 0|64@0+ (1,0) [0|18446744073709551615] "" GTW

BO_ 1848 EPAS3S_udsResponse: 8 GTW
 SG_ EPAS3S_udsResponseData : 0|64@0+ (1,0) [0|18446744073709551615] "" ODIN

BO_ 1859 ID743VCRIGHT_recallStatus: 1 VehicleBus
 SG_ VCRIGHT_mirrorRecallStatus : 4|2@1+ (1,0) [0|3] ""  Receiver
 SG_ VCRIGHT_seatRecallStatus : 2|2@1+ (1,0) [0|3] ""  Receiver
 SG_ VCRIGHT_systemRecallStatus : 0|2@1+ (1,0) [0|3] ""  Receiver

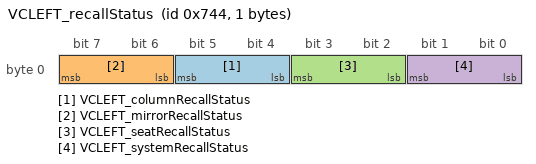
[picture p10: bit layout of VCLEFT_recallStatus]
BO_ 1860 VCLEFT_recallStatus: 1 VEH
 SG_ VCLEFT_columnRecallStatus: 4|2@1+ (1,0) [0|0] "" X
 SG_ VCLEFT_mirrorRecallStatus: 6|2@1+ (1,0) [0|0] "" X
 SG_ VCLEFT_seatRecallStatus: 2|2@1+ (1,0) [0|0] "" X
 SG_ VCLEFT_systemRecallStatus: 0|2@1+ (1,0) [0|0] "" X

BO_ 1879 ID757DIF_debug: 8 VehicleBus
 SG_ DIF_debugSelector M : 0|8@1+ (1,0) [0|255] ""  Receiver
 SG_ DIF_brakeSwitchNC m42 : 63|1@1+ (1,0) [0|1] ""  Receiver
 SG_ DIF_brakeSwitchNO m42 : 62|1@1+ (1,0) [0|1] ""  Receiver
 SG_ DIF_busbarTemp m64 : 16|8@1+ (1,-40) [-40|215] "C"  Receiver
 SG_ DIF_controlStack m67 : 40|8@1+ (0.4,0) [0|100] "%"  Receiver
 SG_ DIF_cpu100HzAvg m66 : 32|8@1+ (0.4,0) [0|102] "%"  Receiver
 SG_ DIF_cpu100HzMin m66 : 24|8@1+ (0.4,0) [0|102] "%"  Receiver
 SG_ DIF_cpu10HzAvg m66 : 16|8@1+ (0.4,0) [0|102] "%"  Receiver
 SG_ DIF_cpu10HzMin m66 : 8|8@1+ (0.4,0) [0|102] "%"  Receiver
 SG_ DIF_cpu10msMin m66 : 40|8@1+ (0.4,0) [0|102] "%"  Receiver
 SG_ DIF_cpu1HzAvg m128 : 24|8@1+ (0.4,0) [0|102] "%"  Receiver
 SG_ DIF_cpu1HzMin m128 : 16|8@1+ (0.4,0) [0|102] "%"  Receiver
 SG_ DIF_cpu1kHzAvg m67 : 16|8@1+ (0.4,0) [0|102] "%"  Receiver
 SG_ DIF_cpu1kHzMin m67 : 8|8@1+ (0.4,0) [0|102] "%"  Receiver
 SG_ DIF_cpu20kHzAvg m67 : 32|8@1+ (0.4,0) [0|102] "%"  Receiver
 SG_ DIF_cpu20kHzMin m67 : 24|8@1+ (0.4,0) [0|102] "%"  Receiver
 SG_ DIF_cpuIDWord0 m131 : 16|16@1+ (1,0) [0|65535] ""  Receiver
 SG_ DIF_cpuIDWord1 m132 : 16|16@1+ (1,0) [0|65535] ""  Receiver
 SG_ DIF_cpuIDWord2 m132 : 32|16@1+ (1,0) [0|65535] ""  Receiver
 SG_ DIF_cpuIDWord3 m132 : 48|16@1+ (1,0) [0|65535] ""  Receiver
 SG_ DIF_crc m131 : 32|32@1+ (1,0) [0|4294970000] ""  Receiver
 SG_ DIF_currentLimit m41 : 32|16@1+ (0.1,0) [0|6553.5] "A"  Receiver
 SG_ DIF_dcCableCurrentEst m37 : 16|16@1- (0.1,0) [-3276.8|3276.7] "A"  Receiver
 SG_ DIF_dcCableHeat m47 : 32|16@1+ (0.001,0) [0|65.535] "kA2s"  Receiver
 SG_ DIF_dcCapTemp m64 : 8|8@1+ (1,-40) [-40|215] "C"  Receiver
 SG_ DIF_dcLinkCapTemp m70 : 32|8@1+ (1,-40) [-40|215] "C"  Receiver
 SG_ DIF_decodeHardwareStack m68 : 24|8@1+ (0.4,0) [0|100] "%"  Receiver
 SG_ DIF_driveUnitOdometer m69 : 32|32@1+ (10,0) [0|42949700000] "rev"  Receiver
 SG_ DIF_eepromStack m68 : 32|8@1+ (0.4,0) [0|100] "%"  Receiver
 SG_ DIF_fluxState m42 : 16|4@1+ (1,0) [0|10] ""  Receiver
 SG_ DIF_gainScale m37 : 8|8@1+ (0.01,0) [0|2.55] "scale"  Receiver
 SG_ DIF_gateDriveState m50 : 10|3@1+ (1,0) [0|4] ""  Receiver
 SG_ DIF_gateDriveSupplyState m50 : 8|2@1+ (1,0) [0|3] ""  Receiver
 SG_ DIF_hvDcCableTemp m70 : 40|8@1+ (1,-40) [-40|215] "C"  Receiver
 SG_ DIF_hwFaultCount m69 : 8|4@1+ (1,0) [0|15] ""  Receiver
 SG_ DIF_idleStack m68 : 16|8@1+ (0.4,0) [0|100] "%"  Receiver
 SG_ DIF_immobilizerStack m68 : 56|8@1+ (0.4,0) [0|100] "%"  Receiver
 SG_ DIF_internalAngleFilt m37 : 48|16@1+ (0.0003,0) [0|8] "rad"  Receiver
 SG_ DIF_llrScale m42 : 32|8@1+ (0.015,0) [0|3.825] "scale"  Receiver
 SG_ DIF_llsScale m42 : 24|8@1+ (0.004,0) [0|1.02] "scale"  Receiver
 SG_ DIF_lmScale m36 : 8|8@1+ (0.004,0) [0|1.02] "scale"  Receiver
 SG_ DIF_loadAngle m42 : 40|16@1- (0.0003,0) [-4|4] "rad"  Receiver
 SG_ DIF_loadAngleMargin m37 : 32|16@1- (0.0003,0) [-4|4] "rad"  Receiver
 SG_ DIF_magnetTempEst m47 : 48|8@1+ (1,-40) [-40|180] "C"  Receiver
 SG_ DIF_module10HzStack m66 : 48|8@1+ (0.4,0) [0|100] "%"  Receiver
 SG_ DIF_motorIA m32 : 16|16@1+ (0.1,0) [0|6553.5] "A"  Receiver
 SG_ DIF_motorIAavg m38 : 32|16@1- (0.1,0) [-3276.8|3276.7] "A"  Receiver
 SG_ DIF_motorIB m32 : 32|16@1+ (0.1,0) [0|6553.5] "A"  Receiver
 SG_ DIF_motorIBavg m38 : 48|16@1- (0.1,0) [-3276.8|3276.7] "A"  Receiver
 SG_ DIF_motorIC m32 : 48|16@1+ (0.1,0) [0|6553.5] "A"  Receiver
 SG_ DIF_motorType m128 : 8|6@1+ (1,0) [0|32] ""  Receiver
 SG_ DIF_motorV m34 : 48|16@1+ (2E-005,0) [0|1.3107] "mindex"  Receiver
 SG_ DIF_negDcBusbarTemp m70 : 48|8@1+ (1,-40) [-40|215] "C"  Receiver
 SG_ DIF_offsetA m32 : 8|8@1- (0.1,0) [-12.8|12.7] "A"  Receiver
 SG_ DIF_offsetB m33 : 8|8@1- (0.1,0) [-12.8|12.7] "A"  Receiver
 SG_ DIF_oilPumpMotorSpeed m46 : 8|8@1+ (40,0) [0|10200] "RPM"  Receiver
 SG_ DIF_oilPumpPhaseVoltage m46 : 16|8@1+ (0.1,0) [0|25.4] "V"  Receiver
 SG_ DIF_oilPumpPressureEstimateMax m46 : 24|8@1+ (2,0) [0|500] "kPa"  Receiver
 SG_ DIF_oilPumpPressureExpectedMin m46 : 32|8@1+ (2,0) [0|500] "kPa"  Receiver
 SG_ DIF_pcsTemp m64 : 24|8@1+ (1,-40) [-40|215] "C"  Receiver
 SG_ DIF_peakFlux m36 : 48|16@1+ (0.0001,0) [0|6.5535] "Wb"  Receiver
 SG_ DIF_peakIQref m38 : 16|16@1+ (0.1,0) [0|6553.5] "A"  Receiver
 SG_ DIF_phaseOutBusbarTemp m70 : 8|8@1+ (1,-40) [-40|215] "C"  Receiver
 SG_ DIF_phaseOutBusbarWeldTemp m70 : 16|8@1+ (1,-40) [-40|215] "C"  Receiver
 SG_ DIF_phaseOutLugTemp m70 : 24|8@1+ (1,-40) [-40|215] "C"  Receiver
 SG_ DIF_posDcBusbarTemp m70 : 56|8@1+ (1,-40) [-40|215] "C"  Receiver
 SG_ DIF_powerStageSafeState m50 : 13|2@1+ (1,0) [0|3] ""  Receiver
 SG_ DIF_pwmState m63 : 48|2@1+ (1,0) [0|3] ""  Receiver
 SG_ DIF_pwrSatChargeCurrent m42 : 8|8@1+ (0.4,0) [0|102] "%"  Receiver
 SG_ DIF_pwrSatDischargeCurrent m40 : 8|8@1+ (0.4,0) [0|102] "%"  Receiver
 SG_ DIF_pwrSatMaxBusVoltage m39 : 48|8@1+ (0.4,0) [0|102] "%"  Receiver
 SG_ DIF_pwrSatMaxDischargePower m39 : 16|8@1+ (0.4,0) [0|102] "%"  Receiver
 SG_ DIF_pwrSatMaxRegenPower m39 : 24|8@1+ (0.4,0) [0|102] "%"  Receiver
 SG_ DIF_pwrSatMinBusVoltage m39 : 56|8@1+ (0.4,0) [0|102] "%"  Receiver
 SG_ DIF_resolverClaMIA m48 : 43|1@1+ (1,0) [0|1] ""  Receiver
 SG_ DIF_resolverCommonGain m48 : 32|8@1+ (0.025,0) [0|5] "1"  Receiver
 SG_ DIF_resolverCosFiltered m52 : 32|8@1- (0.01,0) [-1|1] "1"  Receiver
 SG_ DIF_resolverCosRmsSquared m52 : 16|8@1+ (0.005,0) [0|1] "1"  Receiver
 SG_ DIF_resolverErrorRmsSquared m52 : 48|8@1+ (0.005,0) [0|1] "1"  Receiver
 SG_ DIF_resolverNoCarrier m48 : 41|1@1+ (1,0) [0|1] ""  Receiver
 SG_ DIF_resolverNoPhaseLock m48 : 42|1@1+ (1,0) [0|1] ""  Receiver
 SG_ DIF_resolverOffsetCos m48 : 8|8@1+ (0.015,0) [0|3.3] "V"  Receiver
 SG_ DIF_resolverOffsetSin m48 : 16|8@1+ (0.015,0) [0|3.3] "V"  Receiver
 SG_ DIF_resolverPhaseOffset m48 : 24|8@1+ (0.1,7.5) [7.5|32.5] "us"  Receiver
 SG_ DIF_resolverReady m48 : 40|1@1+ (1,0) [0|1] ""  Receiver
 SG_ DIF_resolverSinFiltered m52 : 40|8@1- (0.01,0) [-1|1] "1"  Receiver
 SG_ DIF_resolverSinRmsSquared m52 : 24|8@1+ (0.005,0) [0|1] "1"  Receiver
 SG_ DIF_rotorFlux m47 : 16|16@1+ (0.0001,0) [0|6.5535] "Wb"  Receiver
 SG_ DIF_rotorMaxMagnetTemp m72 : 16|8@1+ (1,-40) [-40|215] "C"  Receiver
 SG_ DIF_rotorOffsetEst m43 : 8|12@1- (0.01,0) [-20|20] "deg"  Receiver
 SG_ DIF_rotorOffsetLearningState m63 : 8|4@1+ (1,0) [0|9] ""  Receiver
 SG_ DIF_rotorOffsetMean m43 : 20|12@1- (0.01,0) [-20|20] "deg"  Receiver
 SG_ DIF_rsScale m34 : 8|8@1+ (0.01,0) [0|2.55] "scale"  Receiver
 SG_ DIF_soptMaxCurrentMagSqrd m49 : 40|16@1+ (100,0) [0|6553500] "A2"  Receiver
 SG_ DIF_soptTimeToOff m49 : 24|11@1+ (0.05,0) [0|100] "ms"  Receiver
 SG_ DIF_soptTimeToTrip m49 : 8|8@1+ (0.05,0) [0|10] "ms"  Receiver
 SG_ DIF_soptTripDelay m49 : 16|8@1+ (0.05,0) [0|10] "ms"  Receiver
 SG_ DIF_ssmState m38 : 8|4@1+ (1,0) [0|8] ""  Receiver
 SG_ DIF_statorEndWindingTemp m72 : 8|8@1+ (1,-40) [-40|215] "C"  Receiver
 SG_ DIF_statorFluxFdb m35 : 32|16@1+ (0.0001,0) [0|6.5535] "Wb"  Receiver
 SG_ DIF_statorFluxRef m35 : 16|16@1+ (0.0001,0) [0|6.5535] "Wb"  Receiver
 SG_ DIF_statorIDfdb m33 : 32|16@1- (0.1,0) [-3276.8|3276.7] "A"  Receiver
 SG_ DIF_statorIDref m33 : 16|16@1- (0.1,0) [-3276.8|3276.7] "A"  Receiver
 SG_ DIF_statorIQfdb m34 : 32|16@1- (0.1,0) [-3276.8|3276.7] "A"  Receiver
 SG_ DIF_statorIQref m34 : 16|16@1- (0.1,0) [-3276.8|3276.7] "A"  Receiver
 SG_ DIF_statorTemp1 m64 : 32|8@1+ (1,-40) [-40|215] "C"  Receiver
 SG_ DIF_statorTemp2 m64 : 40|8@1+ (1,-40) [-40|215] "C"  Receiver
 SG_ DIF_statorVD m36 : 32|16@1- (4E-005,0) [-1.31072|1.31068] "mindex"  Receiver
 SG_ DIF_statorVDFiltered m63 : 16|16@1- (4E-005,0) [-1.31072|1.31068] "mindex"  Receiver
 SG_ DIF_statorVQ m36 : 16|16@1- (4E-005,0) [-1.31072|1.31068] "mindex"  Receiver
 SG_ DIF_statorVQFiltered m63 : 32|16@1- (4E-005,0) [-1.31072|1.31068] "mindex"  Receiver
 SG_ DIF_sysHeatPowerOptimal m50 : 16|8@1+ (0.08,0) [0|20] "kW"  Receiver
 SG_ DIF_systemStack m68 : 8|8@1+ (0.4,0) [0|100] "%"  Receiver
 SG_ DIF_systemTorqueCommand m35 : 48|16@1- (0.035,0) [-1146.88|1146.85] "Nm"  Receiver
 SG_ DIF_tcMaxRequest m40 : 16|8@1+ (5,0) [0|1275] "Nm"  Receiver
 SG_ DIF_tcMinRequest m40 : 24|8@1+ (5,0) [0|1275] "Nm"  Receiver
 SG_ DIF_torquePerAmp m33 : 48|16@1+ (0.0001,0) [0|6.5535] "Nm/A"  Receiver
 SG_ DIF_tqSatMotorCurrent m39 : 40|8@1+ (0.4,0) [0|102] "%"  Receiver
 SG_ DIF_tqSatMotorVoltage m39 : 32|8@1+ (0.4,0) [0|102] "%"  Receiver
 SG_ DIF_tqSatThermal m39 : 8|8@1+ (0.4,0) [0|102] "%"  Receiver
 SG_ DIF_tqSatUiDriveTorque m40 : 32|8@1+ (0.4,0) [0|102] "%"  Receiver
 SG_ DIF_tqSatUiRegenTorque m40 : 40|8@1+ (0.4,0) [0|102] "%"  Receiver
 SG_ DIF_tqScaleDifferential m35 : 8|8@1+ (0.4,0) [0|102] "%"  Receiver
 SG_ DIF_tqScaleMaxMotorSpeed m40 : 48|8@1+ (0.4,0) [0|102] "%"  Receiver
 SG_ DIF_tqScaleShift m40 : 56|8@1+ (0.4,0) [0|102] "%"  Receiver
 SG_ DIF_udsStack m68 : 40|8@1+ (0.4,0) [0|100] "%"  Receiver
 SG_ DIF_usmState m38 : 12|3@1+ (1,0) [0|7] ""  Receiver
 SG_ DIF_veMassInvRaw m41 : 8|12@1+ (1E-007,0.0001) [0.0001|0.0005] "1/kg"  Receiver
 SG_ DIF_veResForce m41 : 20|12@1- (0.0005,0) [-1.024|1.0235] "G"  Receiver
 SG_ DIF_wasteCurrentLimit m41 : 48|16@1+ (0.1,0) [0|6553.5] "A"  Receiver
 SG_ DIF_xcpStack m68 : 48|8@1+ (0.4,0) [0|100] "%"  Receiver

BO_ 1880 DI_dyno: 8 VEH
 SG_ DI_dynoSelector M: 0|8@1+ (1,0) [0|0] "" X
 SG_ DI_Isx m0: 16|16@1+ (1.5259e-05,0) [0|0] "A" X
 SG_ DI_Isy m0: 32|16@1+ (1.5259e-05,0) [0|0] "A" X
 SG_ DI_IsMag m0: 48|16@1- (0.1,0) [0|0] "A" X
 SG_ DI_Vsx m1: 16|16@1- (4e-05,0) [0|0] "mindex" X
 SG_ DI_Vsy m1: 32|16@1- (4e-05,0) [0|0] "mindex" X
 SG_ DI_voltageForFlux m1: 48|16@1+ (0.00762951,0) [0|0] "V" X
 SG_ DI_torqueMotor m2: 16|13@1- (0.25,0) [0|0] "Nm" X
 SG_ DI_state m2: 29|3@1+ (1,0) [0|0] "" X
 SG_ DI_motorRPM m2: 32|16@1- (1,0) [0|0] "RPM" X
 SG_ DI_torqueEstimate m2: 48|13@1- (0.25,0) [0|0] "Nm" X
 SG_ DI_pedalMinTorque m32: 8|12@1+ (0.25,-750) [0|0] "Nm" X
 SG_ DI_pedalMaxTorque m32: 20|12@1+ (0.25,0) [0|0] "Nm" X
 SG_ DI_postPedalMinTorque m32: 32|12@1+ (0.25,-750) [0|0] "Nm" X
 SG_ DI_postPedalMaxTorque m32: 44|12@1+ (0.25,0) [0|0] "Nm" X
 SG_ DI_slipEstimate m33: 8|10@1- (0.02,0) [0|0] "Hz" X
 SG_ DI_mechToElcFactor m64: 8|4@1- (1,0) [0|0] "" X

BO_ 1885 ID75DCP_sensorData: 8 VehicleBus
 SG_ CP_sensorDataSelect M : 0|4@1+ (1,0) [0|12] ""  Receiver
 SG_ CP_UHF_chipState m6 : 4|3@1+ (1,0) [0|7] ""  Receiver
 SG_ CP_UHF_fifoData m6 : 32|8@1+ (1,0) [0|255] ""  Receiver
 SG_ CP_UHF_rssi m6 : 8|8@1+ (1,0) [0|255] ""  Receiver
 SG_ CP_UHF_rxNumBytes m6 : 24|8@1+ (1,0) [0|255] ""  Receiver
 SG_ CP_UHF_rxOverflow m6 : 16|1@1+ (1,0) [0|1] ""  Receiver
 SG_ CP_UHF_selfTestRssi m6 : 40|8@1+ (1,0) [0|255] ""  Receiver
 SG_ CP_backCover2Counts m5 : 32|16@1+ (0.0015259,0) [0|100] "%"  Receiver
 SG_ CP_backCoverCounts m5 : 16|16@1+ (0.0015259,0) [0|100] "%"  Receiver
 SG_ CP_boardTemperature m1 : 32|8@1+ (1.29412,-50) [-50|280] "C"  Receiver
 SG_ CP_doorCountsDebounced m0 : 24|16@1+ (0.0015259,0) [0|100] "%"  Receiver
 SG_ CP_doorCountsFiltered m0 : 8|16@1+ (0.0015259,0) [0|100] "%"  Receiver
 SG_ CP_doorI m2 : 16|12@1+ (0.0025,0) [0|10.2375] "A"  Receiver
 SG_ CP_doorLastRequestMaxI m2 : 28|12@1+ (0.0025,0) [0|10.2375] "A"  Receiver
 SG_ CP_doorPot m2 : 4|12@1+ (0.025,0) [0|100] "%"  Receiver
 SG_ CP_faultLineV m5 : 4|12@1+ (0.00114,0) [0|4.65524] "V"  Receiver
 SG_ CP_inductiveSensor_raw m4 : 4|28@1+ (1,0) [0|268435000] ""  Receiver
 SG_ CP_inlet1HarnessIdState m12 : 4|2@1+ (1,0) [0|2] ""  Receiver
 SG_ CP_inlet1HarnessIdValue m12 : 8|3@1+ (1,0) [0|7] ""  Receiver
 SG_ CP_inlet1HarnessV m12 : 16|14@1+ (0.001,0) [0|13.3] "V"  Receiver
 SG_ CP_inlet2HarnessIdState m12 : 30|2@1+ (1,0) [0|2] ""  Receiver
 SG_ CP_inlet2HarnessIdValue m12 : 32|3@1+ (1,0) [0|7] ""  Receiver
 SG_ CP_inlet2HarnessV m12 : 40|14@1+ (0.001,0) [0|13.3] "V"  Receiver
 SG_ CP_latch2I m3 : 16|12@1+ (0.0025,0) [0|10.2375] "A"  Receiver
 SG_ CP_latchI m3 : 4|12@1+ (0.0025,0) [0|10.2375] "A"  Receiver
 SG_ CP_pilotHighValue m9 : 40|12@1- (0.01,0) [-20.48|20.47] "V"  Receiver
 SG_ CP_pilotHighValue_intervalMax10s m10 : 28|12@1- (0.01,0) [-20.48|20.47] "V"  Receiver
 SG_ CP_pilotHighValue_intervalMin10s m10 : 40|12@1- (0.01,0) [-20.48|20.47] "V"  Receiver
 SG_ CP_pilotLowValue m9 : 28|12@1- (0.01,0) [-20.48|20.47] "V"  Receiver
 SG_ CP_pilotLowValue_intervalMax10s m10 : 4|12@1- (0.01,0) [-20.48|20.47] "V"  Receiver
 SG_ CP_pilotLowValue_intervalMin10s m10 : 16|12@1- (0.01,0) [-20.48|20.47] "V"  Receiver
 SG_ CP_pilotPeriod m9 : 16|12@1+ (1,0) [0|4095] ""  Receiver
 SG_ CP_pilotPulseWidth m9 : 4|12@1+ (1,0) [0|4095] ""  Receiver
 SG_ CP_pinTemperature1 m1 : 8|8@1+ (0.803922,-55) [-55|149.99] "C"  Receiver
 SG_ CP_pinTemperature2 m1 : 16|8@1+ (0.803922,-55) [-55|149.99] "C"  Receiver
 SG_ CP_pinTemperature3 m1 : 24|8@1+ (0.803922,-55) [-55|149.99] "C"  Receiver
 SG_ CP_proxConn1Sense m8 : 56|1@1+ (1,0) [0|1] ""  Receiver
 SG_ CP_proxEn m8 : 57|1@1+ (1,0) [0|1] ""  Receiver
 SG_ CP_proximityV m8 : 8|16@1+ (0.0001,0) [0|6.5535] "V"  Receiver
 SG_ CP_proximityV_GBCC1 m11 : 8|14@1+ (0.001,0) [0|13.3] "V"  Receiver
 SG_ CP_proximityV_GBCC2 m11 : 24|14@1+ (0.001,0) [0|13.3] "V"  Receiver
 SG_ CP_proximityV_intervalMax10s m8 : 40|16@1+ (0.0001,0) [0|6.5535] "V"  Receiver
 SG_ CP_proximityV_intervalMin10s m8 : 24|16@1+ (0.0001,0) [0|6.5535] "V"  Receiver
 SG_ CP_refVoltage m7 : 8|8@1+ (0.00705882,0) [0|1.8] "V"  Receiver

BO_ 1898 HVP_vehicleDbg: 8 VEH
 SG_ HVP_ecuLogUploadRequest: 5|2@1+ (1,0) [0|0] "" X
 SG_ HVP_vehicleDebugMultiplexer M: 0|5@1+ (1,0) [0|0] "" X
 SG_ HVP_packNegativeContPwmDuty m0: 8|14@1+ (0.01,0) [0|0] "%" X
 SG_ HVP_packPositiveContPwmDuty m0: 22|14@1+ (0.01,0) [0|0] "%" X
 SG_ HVP_FcPositiveContPwmDuty m0: 36|14@1+ (0.01,0) [0|0] "%" X
 SG_ HVP_FcNegativeContPwmDuty m0: 50|14@1+ (0.01,0) [0|0] "%" X
 SG_ HVP_maxRobinBrickV m1: 8|16@1- (0.001,0) [0|0] "V" X
 SG_ HVP_maxRobinBrickId m1: 24|7@1+ (1,1) [0|0] "" X
 SG_ HVP_minRobinBrickV m1: 32|16@1- (0.001,0) [0|0] "V" X
 SG_ HVP_minRobinBrickId m1: 48|7@1+ (1,1) [0|0] "" X
 SG_ HVP_avgRobinBrickV m2: 8|16@1- (0.001,0) [0|0] "V" X

BO_ 1962 HVP_debugMessage: 8 GTW
 SG_ HVP_debugMessageMultiplexer : 0|4@1+ (1,0) [0|12] "" XXX
 SG_ HVP_ecuLogUploadRequest : 46|2@1+ (1,0) [0|3] "" ODIN,UI
 SG_ HVP_hvilInVoltage : 28|12@1+ (0.1,0) [0|30] "V" ODIN,UI,VITALS
 SG_ HVP_hvilOutVoltage : 40|12@1+ (0.1,0) [0|30] "V" ODIN,UI,VITALS

BO_ 1992 EPBL_info: 8 VEH
 SG_ EPBL_infoIndex M: 0|8@1+ (1,0) [0|0] "" X
 SG_ EPBL_infoBuildType m10: 8|3@1+ (1,0) [0|0] "" X
 SG_ EPBL_infoBuildConfigId m10: 16|16@1+ (1,0) [0|0] "" X
 SG_ EPBL_infoHardwareId m10: 32|16@1+ (1,0) [0|0] "" X
 SG_ EPBL_infoComponentId m10: 48|16@1+ (1,0) [0|0] "" X
 SG_ EPBL_infoPcbaId m11: 8|8@1+ (1,0) [0|0] "" X
 SG_ EPBL_infoAssemblyId m11: 16|8@1+ (1,0) [0|0] "" X
 SG_ EPBL_infoUsageId m11: 24|16@1+ (1,0) [0|0] "" X
 SG_ EPBL_infoSubUsageId m11: 40|16@1+ (1,0) [0|0] "" X
 SG_ EPBL_infoAppCrc m13: 8|32@1+ (1,0) [0|0] "" X
 SG_ EPBL_infoAppGitHash m17: 10|54@1+ (4,0) [0|0] "" X
 SG_ EPBL_infoBootGitHash m18: 10|54@1+ (4,0) [0|0] "" X
 SG_ EPBL_infoPlatformType m19: 8|8@1+ (1,0) [0|0] "" X
 SG_ EPBL_infoBootUdsProtoVersion m20: 8|16@1+ (1,0) [0|0] "" X
 SG_ EPBL_infoBootCrc m20: 24|32@1+ (1,0) [0|0] "" X

BO_ 2005 ID7D5DIR_debug: 8 VehicleBus
 SG_ DIR_debugSelector M : 0|8@1+ (1,0) [0|255] ""  Receiver
 SG_ DIR_brakeSwitchNC m42 : 63|1@1+ (1,0) [0|1] ""  Receiver
 SG_ DIR_brakeSwitchNO m42 : 62|1@1+ (1,0) [0|1] ""  Receiver
 SG_ DIR_busbarTemp m64 : 16|8@1+ (1,-40) [-40|215] "C"  Receiver
 SG_ DIR_controlStack m67 : 40|8@1+ (0.4,0) [0|100] "%"  Receiver
 SG_ DIR_cpu100HzAvg m66 : 32|8@1+ (0.4,0) [0|102] "%"  Receiver
 SG_ DIR_cpu100HzMin m66 : 24|8@1+ (0.4,0) [0|102] "%"  Receiver
 SG_ DIR_cpu10HzAvg m66 : 16|8@1+ (0.4,0) [0|102] "%"  Receiver
 SG_ DIR_cpu10HzMin m66 : 8|8@1+ (0.4,0) [0|102] "%"  Receiver
 SG_ DIR_cpu10msMin m66 : 40|8@1+ (0.4,0) [0|102] "%"  Receiver
 SG_ DIR_cpu1HzAvg m128 : 24|8@1+ (0.4,0) [0|102] "%"  Receiver
 SG_ DIR_cpu1HzMin m128 : 16|8@1+ (0.4,0) [0|102] "%"  Receiver
 SG_ DIR_cpu1kHzAvg m67 : 16|8@1+ (0.4,0) [0|102] "%"  Receiver
 SG_ DIR_cpu1kHzMin m67 : 8|8@1+ (0.4,0) [0|102] "%"  Receiver
 SG_ DIR_cpu20kHzAvg m67 : 32|8@1+ (0.4,0) [0|102] "%"  Receiver
 SG_ DIR_cpu20kHzMin m67 : 24|8@1+ (0.4,0) [0|102] "%"  Receiver
 SG_ DIR_cpuIDWord0 m131 : 16|16@1+ (1,0) [0|65535] ""  Receiver
 SG_ DIR_cpuIDWord1 m132 : 16|16@1+ (1,0) [0|65535] ""  Receiver
 SG_ DIR_cpuIDWord2 m132 : 32|16@1+ (1,0) [0|65535] ""  Receiver
 SG_ DIR_cpuIDWord3 m132 : 48|16@1+ (1,0) [0|65535] ""  Receiver
 SG_ DIR_crc m131 : 32|32@1+ (1,0) [0|4294970000] ""  Receiver
 SG_ DIR_currentLimit m41 : 32|16@1+ (0.1,0) [0|6553.5] "A"  Receiver
 SG_ DIR_dcCableCurrentEst m37 : 16|16@1- (0.1,0) [-3276.8|3276.7] "A"  Receiver
 SG_ DIR_dcCableHeat m47 : 32|16@1+ (0.001,0) [0|65.535] "kA2s"  Receiver
 SG_ DIR_dcCapTemp m64 : 8|8@1+ (1,-40) [-40|215] "C"  Receiver
 SG_ DIR_dcLinkCapTemp m70 : 32|8@1+ (1,-40) [-40|215] "C"  Receiver
 SG_ DIR_decodeHardwareStack m68 : 24|8@1+ (0.4,0) [0|100] "%"  Receiver
 SG_ DIR_driveUnitOdometer m69 : 32|32@1+ (10,0) [0|42949700000] "rev"  Receiver
 SG_ DIR_eepromStack m68 : 32|8@1+ (0.4,0) [0|100] "%"  Receiver
 SG_ DIR_fluxState m42 : 16|4@1+ (1,0) [0|10] ""  Receiver
 SG_ DIR_gainScale m37 : 8|8@1+ (0.01,0) [0|2.55] "scale"  Receiver
 SG_ DIR_gateDriveState m50 : 10|3@1+ (1,0) [0|4] ""  Receiver
 SG_ DIR_gateDriveSupplyState m50 : 8|2@1+ (1,0) [0|3] ""  Receiver
 SG_ DIR_hvDcCableTemp m70 : 40|8@1+ (1,-40) [-40|215] "C"  Receiver
 SG_ DIR_hwFaultCount m69 : 8|4@1+ (1,0) [0|15] ""  Receiver
 SG_ DIR_idleStack m68 : 16|8@1+ (0.4,0) [0|100] "%"  Receiver
 SG_ DIR_immobilizerStack m68 : 56|8@1+ (0.4,0) [0|100] "%"  Receiver
 SG_ DIR_internalAngleFilt m37 : 48|16@1+ (0.0003,0) [0|8] "rad"  Receiver
 SG_ DIR_llrScale m42 : 32|8@1+ (0.015,0) [0|3.825] "scale"  Receiver
 SG_ DIR_llsScale m42 : 24|8@1+ (0.004,0) [0|1.02] "scale"  Receiver
 SG_ DIR_lmScale m36 : 8|8@1+ (0.004,0) [0|1.02] "scale"  Receiver
 SG_ DIR_loadAngle m42 : 40|16@1- (0.0003,0) [-4|4] "rad"  Receiver
 SG_ DIR_loadAngleMargin m37 : 32|16@1- (0.0003,0) [-4|4] "rad"  Receiver
 SG_ DIR_magnetTempEst m47 : 48|8@1+ (1,-40) [-40|180] "C"  Receiver
 SG_ DIR_module10HzStack m66 : 48|8@1+ (0.4,0) [0|100] "%"  Receiver
 SG_ DIR_motorIA m32 : 16|16@1+ (0.1,0) [0|6553.5] "A"  Receiver
 SG_ DIR_motorIAavg m38 : 32|16@1- (0.1,0) [-3276.8|3276.7] "A"  Receiver
 SG_ DIR_motorIB m32 : 32|16@1+ (0.1,0) [0|6553.5] "A"  Receiver
 SG_ DIR_motorIBavg m38 : 48|16@1- (0.1,0) [-3276.8|3276.7] "A"  Receiver
 SG_ DIR_motorIC m32 : 48|16@1+ (0.1,0) [0|6553.5] "A"  Receiver
 SG_ DIR_motorType m128 : 8|6@1+ (1,0) [0|32] ""  Receiver
 SG_ DIR_motorV m34 : 48|16@1+ (2E-005,0) [0|1.3107] "mindex"  Receiver
 SG_ DIR_negDcBusbarTemp m70 : 48|8@1+ (1,-40) [-40|215] "C"  Receiver
 SG_ DIR_offsetA m32 : 8|8@1- (0.1,0) [-12.8|12.7] "A"  Receiver
 SG_ DIR_offsetB m33 : 8|8@1- (0.1,0) [-12.8|12.7] "A"  Receiver
 SG_ DIR_oilPumpMotorSpeed m46 : 8|8@1+ (40,0) [0|10200] "RPM"  Receiver
 SG_ DIR_oilPumpPhaseVoltage m46 : 16|8@1+ (0.1,0) [0|25.4] "V"  Receiver
 SG_ DIR_oilPumpPressureEstimateMax m46 : 24|8@1+ (2,0) [0|500] "kPa"  Receiver
 SG_ DIR_oilPumpPressureExpectedMin m46 : 32|8@1+ (2,0) [0|500] "kPa"  Receiver
 SG_ DIR_pcsTemp m64 : 24|8@1+ (1,-40) [-40|215] "C"  Receiver
 SG_ DIR_peakFlux m36 : 48|16@1+ (0.0001,0) [0|6.5535] "Wb"  Receiver
 SG_ DIR_peakIQref m38 : 16|16@1+ (0.1,0) [0|6553.5] "A"  Receiver
 SG_ DIR_phaseOutBusbarTemp m70 : 8|8@1+ (1,-40) [-40|215] "C"  Receiver
 SG_ DIR_phaseOutBusbarWeldTemp m70 : 16|8@1+ (1,-40) [-40|215] "C"  Receiver
 SG_ DIR_phaseOutLugTemp m70 : 24|8@1+ (1,-40) [-40|215] "C"  Receiver
 SG_ DIR_posDcBusbarTemp m70 : 56|8@1+ (1,-40) [-40|215] "C"  Receiver
 SG_ DIR_powerStageSafeState m50 : 13|2@1+ (1,0) [0|3] ""  Receiver
 SG_ DIR_pwmState m63 : 48|2@1+ (1,0) [0|3] ""  Receiver
 SG_ DIR_pwrSatChargeCurrent m42 : 8|8@1+ (0.4,0) [0|102] "%"  Receiver
 SG_ DIR_pwrSatDischargeCurrent m40 : 8|8@1+ (0.4,0) [0|102] "%"  Receiver
 SG_ DIR_pwrSatMaxBusVoltage m39 : 48|8@1+ (0.4,0) [0|102] "%"  Receiver
 SG_ DIR_pwrSatMaxDischargePower m39 : 16|8@1+ (0.4,0) [0|102] "%"  Receiver
 SG_ DIR_pwrSatMaxRegenPower m39 : 24|8@1+ (0.4,0) [0|102] "%"  Receiver
 SG_ DIR_pwrSatMinBusVoltage m39 : 56|8@1+ (0.4,0) [0|102] "%"  Receiver
 SG_ DIR_resolverClaMIA m48 : 43|1@1+ (1,0) [0|1] ""  Receiver
 SG_ DIR_resolverCommonGain m48 : 32|8@1+ (0.025,0) [0|5] "1"  Receiver
 SG_ DIR_resolverCosFiltered m52 : 32|8@1- (0.01,0) [-1|1] "1"  Receiver
 SG_ DIR_resolverCosRmsSquared m52 : 16|8@1+ (0.005,0) [0|1] "1"  Receiver
 SG_ DIR_resolverErrorRmsSquared m52 : 48|8@1+ (0.005,0) [0|1] "1"  Receiver
 SG_ DIR_resolverNoCarrier m48 : 41|1@1+ (1,0) [0|1] ""  Receiver
 SG_ DIR_resolverNoPhaseLock m48 : 42|1@1+ (1,0) [0|1] ""  Receiver
 SG_ DIR_resolverOffsetCos m48 : 8|8@1+ (0.015,0) [0|3.3] "V"  Receiver
 SG_ DIR_resolverOffsetSin m48 : 16|8@1+ (0.015,0) [0|3.3] "V"  Receiver
 SG_ DIR_resolverPhaseOffset m48 : 24|8@1+ (0.1,7.5) [7.5|32.5] "us"  Receiver
 SG_ DIR_resolverReady m48 : 40|1@1+ (1,0) [0|1] ""  Receiver
 SG_ DIR_resolverSinFiltered m52 : 40|8@1- (0.01,0) [-1|1] "1"  Receiver
 SG_ DIR_resolverSinRmsSquared m52 : 24|8@1+ (0.005,0) [0|1] "1"  Receiver
 SG_ DIR_rotorFlux m47 : 16|16@1+ (0.0001,0) [0|6.5535] "Wb"  Receiver
 SG_ DIR_rotorMaxMagnetTemp m72 : 16|8@1+ (1,-40) [-40|215] "C"  Receiver
 SG_ DIR_rotorOffsetEst m43 : 8|12@1- (0.01,0) [-20|20] "deg"  Receiver
 SG_ DIR_rotorOffsetLearningState m63 : 8|4@1+ (1,0) [0|9] ""  Receiver
 SG_ DIR_rotorOffsetMean m43 : 20|12@1- (0.01,0) [-20|20] "deg"  Receiver
 SG_ DIR_rsScale m34 : 8|8@1+ (0.01,0) [0|2.55] "scale"  Receiver
 SG_ DIR_soptMaxCurrentMagSqrd m49 : 40|16@1+ (100,0) [0|6553500] "A2"  Receiver
 SG_ DIR_soptTimeToOff m49 : 24|11@1+ (0.05,0) [0|100] "ms"  Receiver
 SG_ DIR_soptTimeToTrip m49 : 8|8@1+ (0.05,0) [0|10] "ms"  Receiver
 SG_ DIR_soptTripDelay m49 : 16|8@1+ (0.05,0) [0|10] "ms"  Receiver
 SG_ DIR_ssmState m38 : 8|4@1+ (1,0) [0|8] ""  Receiver
 SG_ DIR_statorEndWindingTemp m72 : 8|8@1+ (1,-40) [-40|215] "C"  Receiver
 SG_ DIR_statorFluxFdb m35 : 32|16@1+ (0.0001,0) [0|6.5535] "Wb"  Receiver
 SG_ DIR_statorFluxRef m35 : 16|16@1+ (0.0001,0) [0|6.5535] "Wb"  Receiver
 SG_ DIR_statorIDfdb m33 : 32|16@1- (0.1,0) [-3276.8|3276.7] "A"  Receiver
 SG_ DIR_statorIDref m33 : 16|16@1- (0.1,0) [-3276.8|3276.7] "A"  Receiver
 SG_ DIR_statorIQfdb m34 : 32|16@1- (0.1,0) [-3276.8|3276.7] "A"  Receiver
 SG_ DIR_statorIQref m34 : 16|16@1- (0.1,0) [-3276.8|3276.7] "A"  Receiver
 SG_ DIR_statorTemp1 m64 : 32|8@1+ (1,-40) [-40|215] "C"  Receiver
 SG_ DIR_statorTemp2 m64 : 40|8@1+ (1,-40) [-40|215] "C"  Receiver
 SG_ DIR_statorVD m36 : 32|16@1- (4E-005,0) [-1.31072|1.31068] "mindex"  Receiver
 SG_ DIR_statorVDFiltered m63 : 16|16@1- (4E-005,0) [-1.31072|1.31068] "mindex"  Receiver
 SG_ DIR_statorVQ m36 : 16|16@1- (4E-005,0) [-1.31072|1.31068] "mindex"  Receiver
 SG_ DIR_statorVQFiltered m63 : 32|16@1- (4E-005,0) [-1.31072|1.31068] "mindex"  Receiver
 SG_ DIR_sysHeatPowerOptimal m50 : 16|8@1+ (0.08,0) [0|20] "kW"  Receiver
 SG_ DIR_systemStack m68 : 8|8@1+ (0.4,0) [0|100] "%"  Receiver
 SG_ DIR_systemTorqueCommand m35 : 48|16@1- (0.035,0) [-1146.88|1146.85] "Nm"  Receiver
 SG_ DIR_tcMaxRequest m40 : 16|8@1+ (5,0) [0|1275] "Nm"  Receiver
 SG_ DIR_tcMinRequest m40 : 24|8@1+ (5,0) [0|1275] "Nm"  Receiver
 SG_ DIR_torquePerAmp m33 : 48|16@1+ (0.0001,0) [0|6.5535] "Nm/A"  Receiver
 SG_ DIR_tqSatMotorCurrent m39 : 40|8@1+ (0.4,0) [0|102] "%"  Receiver
 SG_ DIR_tqSatMotorVoltage m39 : 32|8@1+ (0.4,0) [0|102] "%"  Receiver
 SG_ DIR_tqSatThermal m39 : 8|8@1+ (0.4,0) [0|102] "%"  Receiver
 SG_ DIR_tqSatUiDriveTorque m40 : 32|8@1+ (0.4,0) [0|102] "%"  Receiver
 SG_ DIR_tqSatUiRegenTorque m40 : 40|8@1+ (0.4,0) [0|102] "%"  Receiver
 SG_ DIR_tqScaleDifferential m35 : 8|8@1+ (0.4,0) [0|102] "%"  Receiver
 SG_ DIR_tqScaleMaxMotorSpeed m40 : 48|8@1+ (0.4,0) [0|102] "%"  Receiver
 SG_ DIR_tqScaleShift m40 : 56|8@1+ (0.4,0) [0|102] "%"  Receiver
 SG_ DIR_udsStack m68 : 40|8@1+ (0.4,0) [0|100] "%"  Receiver
 SG_ DIR_usmState m38 : 12|3@1+ (1,0) [0|7] ""  Receiver
 SG_ DIR_veMassInvRaw m41 : 8|12@1+ (1E-007,0.0001) [0.0001|0.0005] "1/kg"  Receiver
 SG_ DIR_veResForce m41 : 20|12@1- (0.0005,0) [-1.024|1.0235] "G"  Receiver
 SG_ DIR_wasteCurrentLimit m41 : 48|16@1+ (0.1,0) [0|6553.5] "A"  Receiver
 SG_ DIR_xcpStack m68 : 48|8@1+ (0.4,0) [0|100] "%"  Receiver

BO_ 2014 UDS_functionalRequest_CH: 8 ODIN
 SG_ UDS_functionalRequestDataCH : 0|64@0+ (1,0) [0|18446744073709551615] "" GTW

BO_ 2015 UDS_functionalRequest: 8 ODIN
 SG_ UDS_functionalRequestData_0 : 0|8@0+ (1,0) [0|255] "" GTW
 SG_ UDS_functionalRequestData_1 : 8|8@0+ (1,0) [0|255] "" GTW
 SG_ UDS_functionalRequestData_2 : 16|8@0+ (1,0) [0|255] "" GTW
 SG_ UDS_functionalRequestData_3 : 24|8@0+ (1,0) [0|255] "" GTW
 SG_ UDS_functionalRequestData_4 : 32|8@0+ (1,0) [0|255] "" GTW
 SG_ UDS_functionalRequestData_5 : 40|8@0+ (1,0) [0|255] "" GTW
 SG_ UDS_functionalRequestData_6 : 48|8@0+ (1,0) [0|255] "" GTW
 SG_ UDS_functionalRequestData_7 : 56|8@0+ (1,0) [0|255] "" GTW

BO_ 2024 EPBR_info: 8 VEH
 SG_ EPBR_infoIndex M: 0|8@1+ (1,0) [0|0] "" X
 SG_ EPBR_infoBuildType m10: 8|3@1+ (1,0) [0|0] "" X
 SG_ EPBR_infoBuildConfigId m10: 16|16@1+ (1,0) [0|0] "" X
 SG_ EPBR_infoHardwareId m10: 32|16@1+ (1,0) [0|0] "" X
 SG_ EPBR_infoComponentId m10: 48|16@1+ (1,0) [0|0] "" X
 SG_ EPBR_infoPcbaId m11: 8|8@1+ (1,0) [0|0] "" X
 SG_ EPBR_infoAssemblyId m11: 16|8@1+ (1,0) [0|0] "" X
 SG_ EPBR_infoUsageId m11: 24|16@1+ (1,0) [0|0] "" X
 SG_ EPBR_infoSubUsageId m11: 40|16@1+ (1,0) [0|0] "" X
 SG_ EPBR_infoAppCrc m13: 8|32@1+ (1,0) [0|0] "" X
 SG_ EPBR_infoAppGitHash m17: 10|54@1+ (4,0) [0|0] "" X
 SG_ EPBR_infoBootGitHash m18: 10|54@1+ (4,0) [0|0] "" X
 SG_ EPBR_infoPlatformType m19: 8|8@1+ (1,0) [0|0] "" X
 SG_ EPBR_infoBootUdsProtoVersion m20: 8|16@1+ (1,0) [0|0] "" X
 SG_ EPBR_infoBootCrc m20: 24|32@1+ (1,0) [0|0] "" X

BO_ 2033 GTW_hrl: 7 VEH
 SG_ GTW_hrlIndex M: 0|2@1+ (1,0) [0|0] "" X
 SG_ GTW_hrlPagesCount m1: 8|32@0+ (1,0) [0|0] "" X
 SG_ GTW_hrlState m2: 2|1@1+ (1,0) [0|0] "" X
 SG_ GTW_hrlTriggerDuration m2: 8|16@0+ (1,0) [0|0] "seconds" X
 SG_ GTW_hrlTriggerType m2: 24|4@1+ (1,0) [0|0] "" X
 SG_ GTW_hrlTriggerId m2: 32|16@0+ (1,0) [0|0] "" X
 SG_ GTW_hrlTriggerBus m2: 48|3@1+ (1,0) [0|0] "" X

BO_ 2047 ID7FFcarConfig: 8 VehicleBus
 SG_ GTW_carConfigMultiplexer M : 0|8@1+ (1,0) [0|255] ""  Receiver
 SG_ GTW_activeHighBeam m2 : 34|1@1+ (1,0) [0|1] ""  Receiver
 SG_ GTW_airSuspension m3 : 22|2@1+ (1,0) [0|2] ""  Receiver
 SG_ GTW_airbagCutoffSwitch m2 : 35|1@1+ (1,0) [0|1] ""  Receiver
 SG_ GTW_audioType m3 : 30|2@1+ (1,0) [0|2] ""  Receiver
 SG_ GTW_autopilot m2 : 42|3@1+ (1,0) [0|4] ""  Receiver
 SG_ GTW_autopilotCameraType m3 : 26|1@1+ (1,0) [0|0] ""  Receiver
 SG_ GTW_auxParkLamps m2 : 26|2@1+ (1,0) [0|3] ""  Receiver
 SG_ GTW_bPillarNFCParam m2 : 56|1@1+ (1,0) [0|1] ""  Receiver
 SG_ GTW_birthday m4 : 8|32@1+ (1,0) [0|4294970000] ""  Receiver
 SG_ GTW_brakeHWType m2 : 59|2@1+ (1,0) [0|3] ""  Receiver
 SG_ GTW_brakeLineSwitchType m3 : 39|1@1+ (1,0) [0|1] ""  Receiver
 SG_ GTW_cabinPTCHeaterType m2 : 31|1@1+ (1,0) [0|1] ""  Receiver
 SG_ GTW_chassisType m3 : 18|3@1+ (1,0) [0|4] ""  Receiver
 SG_ GTW_compressorType m4 : 46|2@1+ (1,0) [0|3] ""  Receiver
 SG_ GTW_connectivityPackage m3 : 27|1@1+ (1,0) [0|1] ""  Receiver
 SG_ GTW_coolantPumpType m3 : 17|1@1+ (1,0) [0|1] ""  Receiver
 SG_ GTW_country m1 : 16|16@1+ (1,0) [0|65535] ""  Receiver
 SG_ GTW_dasHw m1 : 40|3@1+ (1,0) [3|4] ""  Receiver
 SG_ GTW_deliveryStatus m1 : 8|1@1+ (1,0) [0|1] ""  Receiver
 SG_ GTW_drivetrainType m1 : 10|1@1+ (1,0) [0|1] ""  Receiver
 SG_ GTW_eBuckConfig m2 : 32|1@1+ (1,0) [0|1] ""  Receiver
 SG_ GTW_eCallEnabled m4 : 40|2@1+ (1,0) [0|2] ""  Receiver
 SG_ GTW_efficiencyPackage m4 : 48|3@1+ (1,0) [0|5] ""  Receiver
 SG_ GTW_epasType m1 : 9|1@1+ (1,0) [0|0] ""  Receiver
 SG_ GTW_espValveType m3 : 40|2@1+ (1,0) [0|2] ""  Receiver
 SG_ GTW_exteriorColor m2 : 48|3@1+ (1,0) [0|6] ""  Receiver
 SG_ GTW_frontFogLamps m2 : 20|1@1+ (1,0) [0|1] ""  Receiver
 SG_ GTW_frontSeatHeaters m2 : 9|1@1+ (1,0) [0|1] ""  Receiver
 SG_ GTW_frontSeatReclinerHardware m3 : 37|2@1+ (1,0) [0|3] ""  Receiver
 SG_ GTW_frontSeatType m3 : 60|3@1+ (1,0) [0|4] ""  Receiver
 SG_ GTW_headlamps m1 : 14|2@1+ (1,0) [0|2] ""  Receiver
 SG_ GTW_headlightLevelerType m3 : 47|1@1+ (1,0) [0|1] ""  Receiver
 SG_ GTW_homelinkType m2 : 13|1@1+ (1,0) [0|1] ""  Receiver
 SG_ GTW_hvacPanelVaneType m2 : 29|1@1+ (1,0) [0|1] ""  Receiver
 SG_ GTW_immersiveAudio m3 : 56|2@1+ (1,0) [0|2] ""  Receiver
 SG_ GTW_interiorLighting m2 : 57|2@1+ (1,0) [0|2] ""  Receiver
 SG_ GTW_intrusionSensorType m2 : 36|1@1+ (1,0) [0|1] ""  Receiver
 SG_ GTW_lumbarECUType m2 : 23|1@1+ (1,0) [0|1] ""  Receiver
 SG_ GTW_mapRegion m3 : 8|4@1+ (1,0) [0|10] ""  Receiver
 SG_ GTW_memoryMirrors m2 : 17|1@1+ (1,0) [0|1] ""  Receiver
 SG_ GTW_numberHVILNodes m2 : 51|2@1+ (1,0) [2|3] ""  Receiver
 SG_ GTW_packEnergy m3 : 32|5@1+ (1,0) [0|2] ""  Receiver
 SG_ GTW_passengerAirbagType m4 : 43|2@1+ (1,0) [0|2] ""  Receiver
 SG_ GTW_passengerOccupancySensorType m3 : 24|1@1+ (1,0) [0|1] ""  Receiver
 SG_ GTW_pedestrianWarningSound m2 : 54|1@1+ (1,0) [0|1] ""  Receiver
 SG_ GTW_performancePackage m3 : 12|3@1+ (1,0) [0|3] ""  Receiver
 SG_ GTW_plcSupportType m3 : 28|2@1+ (1,0) [0|2] ""  Receiver
 SG_ GTW_powerSteeringColumn m2 : 18|1@1+ (1,0) [0|1] ""  Receiver
 SG_ GTW_radarHeaterType m3 : 55|1@1+ (1,0) [0|1] ""  Receiver
 SG_ GTW_rearFogLamps m2 : 39|1@1+ (1,0) [0|1] ""  Receiver
 SG_ GTW_rearGlassType m2 : 38|1@1+ (1,0) [0|1] ""  Receiver
 SG_ GTW_rearLightType m1 : 12|2@1+ (1,0) [0|2] ""  Receiver
 SG_ GTW_rearSeatHeaters m2 : 10|1@1+ (1,0) [0|1] ""  Receiver
 SG_ GTW_refrigerantType m3 : 45|2@1+ (1,0) [0|2] ""  Receiver
 SG_ GTW_restraintsHardwareType m1 : 48|8@1+ (1,0) [21|163] ""  Receiver
 SG_ GTW_rightHandDrive m1 : 11|1@1+ (1,0) [0|1] ""  Receiver
 SG_ GTW_roofGlassType m2 : 61|1@1+ (1,0) [0|1] ""  Receiver
 SG_ GTW_roofType m2 : 40|1@1+ (1,0) [1|1] ""  Receiver
 SG_ GTW_softRange m3 : 42|3@1+ (1,0) [0|2] ""  Receiver
 SG_ GTW_spoilerType m2 : 37|1@1+ (1,0) [0|1] ""  Receiver
 SG_ GTW_steeringColumnMotorType m4 : 52|1@1+ (1,0) [0|1] ""  Receiver
 SG_ GTW_steeringColumnUJointType m2 : 55|1@1+ (1,0) [0|1] ""  Receiver
 SG_ GTW_superchargingAccess m2 : 45|2@1+ (1,0) [0|2] ""  Receiver
 SG_ GTW_tireType m1 : 32|5@1+ (1,0) [0|21] ""  Receiver
 SG_ GTW_towPackage m3 : 15|1@1+ (1,0) [0|1] ""  Receiver
 SG_ GTW_tpmsType m2 : 11|1@1+ (1,0) [0|1] ""  Receiver
 SG_ GTW_twelveVBatteryType m3 : 63|1@1+ (1,0) [0|1] ""  Receiver
 SG_ GTW_vdcType m2 : 14|1@1+ (1,0) [0|1] ""  Receiver
 SG_ GTW_wheelType m3 : 48|7@1+ (1,0) [0|20] ""  Receiver
 SG_ GTW_windshieldType m2 : 33|1@1+ (1,0) [0|1] ""  Receiver
 SG_ GTW_xcpESP m2 : 16|1@1+ (1,0) [0|1] ""  Receiver
 SG_ GTW_xcpIbst m2 : 15|1@1+ (1,0) [0|1] ""  Receiver

CM_ BO_ 1022 "Brake Temps Estimated";
CM_ BO_ 1367 "swapped with 5D7 in old firmware";
CM_ BO_ 1495 "swapped with 557 in old firmware";
CM_ BO_ 1879 "swapped with 7D5 in old firmware";
CM_ BO_ 2005 "swapped with 757 in old firmware";
VAL_ 1013 VCFRONT_DRLLeftStatus 2 "LIGHT_FAULT" 0 "LIGHT_OFF" 1 "LIGHT_ON" 3 "LIGHT_SNA" ;
VAL_ 1013 VCFRONT_DRLRightStatus 2 "LIGHT_FAULT" 0 "LIGHT_OFF" 1 "LIGHT_ON" 3 "LIGHT_SNA" ;
VAL_ 1013 VCFRONT_ambientLightingBrightnes 255 "SNA" ;
VAL_ 1013 VCFRONT_fogLeftStatus 2 "LIGHT_FAULT" 0 "LIGHT_OFF" 1 "LIGHT_ON" 3 "LIGHT_SNA" ;
VAL_ 1013 VCFRONT_fogRightStatus 2 "LIGHT_FAULT" 0 "LIGHT_OFF" 1 "LIGHT_ON" 3 "LIGHT_SNA" ;
VAL_ 1013 VCFRONT_hazardLightRequest 1 "HAZARD_REQUEST_BUTTON" 6 "HAZARD_REQUEST_CAR_ALARM" 5 "HAZARD_REQUEST_CRASH" 7 "HAZARD_REQUEST_DAS" 2 "HAZARD_REQUEST_LOCK" 4 "HAZARD_REQUEST_MISLOCK" 0 "HAZARD_REQUEST_NONE" 8 "HAZARD_REQUEST_UDS" 3 "HAZARD_REQUEST_UNLOCK" ;
VAL_ 1013 VCFRONT_highBeamLeftStatus 2 "LIGHT_FAULT" 0 "LIGHT_OFF" 1 "LIGHT_ON" 3 "LIGHT_SNA" ;
VAL_ 1013 VCFRONT_highBeamRightStatus 2 "LIGHT_FAULT" 0 "LIGHT_OFF" 1 "LIGHT_ON" 3 "LIGHT_SNA" ;
VAL_ 1013 VCFRONT_indicatorLeftRequest 2 "TURN_SIGNAL_ACTIVE_HIGH" 1 "TURN_SIGNAL_ACTIVE_LOW" 0 "TURN_SIGNAL_OFF" ;
VAL_ 1013 VCFRONT_indicatorRightRequest 2 "TURN_SIGNAL_ACTIVE_HIGH" 1 "TURN_SIGNAL_ACTIVE_LOW" 0 "TURN_SIGNAL_OFF" ;
VAL_ 1013 VCFRONT_lowBeamLeftStatus 2 "LIGHT_FAULT" 0 "LIGHT_OFF" 1 "LIGHT_ON" 3 "LIGHT_SNA" ;
VAL_ 1013 VCFRONT_lowBeamRightStatus 2 "LIGHT_FAULT" 0 "LIGHT_OFF" 1 "LIGHT_ON" 3 "LIGHT_SNA" ;
VAL_ 1013 VCFRONT_parkLeftStatus 2 "LIGHT_FAULT" 0 "LIGHT_OFF" 1 "LIGHT_ON" 3 "LIGHT_SNA" ;
VAL_ 1013 VCFRONT_parkRightStatus 2 "LIGHT_FAULT" 0 "LIGHT_OFF" 1 "LIGHT_ON" 3 "LIGHT_SNA" ;
VAL_ 1013 VCFRONT_sideMarkersStatus 2 "LIGHT_FAULT" 0 "LIGHT_OFF" 1 "LIGHT_ON" 3 "LIGHT_SNA" ;
VAL_ 1013 VCFRONT_sideRepeaterLeftStatus 2 "LIGHT_FAULT" 0 "LIGHT_OFF" 1 "LIGHT_ON" 3 "LIGHT_SNA" ;
VAL_ 1013 VCFRONT_sideRepeaterRightStatus 2 "LIGHT_FAULT" 0 "LIGHT_OFF" 1 "LIGHT_ON" 3 "LIGHT_SNA" ;
VAL_ 1013 VCFRONT_simLatchingStalk 0 "SIMULATED_LATCHING_STALK_IDLE" 1 "SIMULATED_LATCHING_STALK_LEFT" 2 "SIMULATED_LATCHING_STALK_RIGHT" 3 "SIMULATED_LATCHING_STALK_SNA" ;
VAL_ 1013 VCFRONT_switchLightingBrightness 255 "SNA" ;
VAL_ 1013 VCFRONT_turnSignalLeftStatus 2 "LIGHT_FAULT" 0 "LIGHT_OFF" 1 "LIGHT_ON" 3 "LIGHT_SNA" ;
VAL_ 1013 VCFRONT_turnSignalRightStatus 2 "LIGHT_FAULT" 0 "LIGHT_OFF" 1 "LIGHT_ON" 3 "LIGHT_SNA" ;
VAL_ 1014 VCFRONT_turnSignalLeftStatus 2 "LIGHT_FAULT" 0 "LIGHT_OFF" 1 "LIGHT_ON" 3 "LIGHT_SNA" ;
VAL_ 1014 VCFRONT_turnSignalRightStatus 2 "LIGHT_FAULT" 0 "LIGHT_OFF" 1 "LIGHT_ON" 3 "LIGHT_SNA" ;
VAL_ 1016 UI_accFollowDistanceSetting 0 "DISTANCE_SETTING_1" 1 "DISTANCE_SETTING_2" 2 "DISTANCE_SETTING_3" 3 "DISTANCE_SETTING_4" 4 "DISTANCE_SETTING_5" 5 "DISTANCE_SETTING_6" 6 "DISTANCE_SETTING_7" 7 "DISTANCE_SETTING_SNA" ;
VAL_ 1016 UI_autopilotControlRequest 0 "LEGACY_LAT_CTRL" 1 "NEXT_GEN_CTRL" ;
VAL_ 1016 UI_curvSpeedAdaptDisable 1 "CSA_OFF" 0 "CSA_ON" ;
VAL_ 1016 UI_curvatureDatabaseOnly 0 "OFF" 1 "ON" ;
VAL_ 1016 UI_driveOnMapsEnable 0 "DOM_OFF" 1 "DOM_ON" ;
VAL_ 1016 UI_drivingSide 0 "DRIVING_SIDE_LEFT" 1 "DRIVING_SIDE_RIGHT" 2 "DRIVING_SIDE_UNKNOWN" ;
VAL_ 1016 UI_exceptionListEnable 0 "EXCEPTION_LIST_OFF" 1 "EXCEPTION_LIST_ON" ;
VAL_ 1016 UI_followNavRouteEnable 0 "NAV_ROUTE_OFF" 1 "NAV_ROUTE_ON" ;
VAL_ 1016 UI_fuseHPPDisable 1 "FUSE_HPP_OFF" 0 "FUSE_HPP_ON" ;
VAL_ 1016 UI_fuseLanesDisable 1 "FUSE_LANES_OFF" 0 "FUSE_LANES_ON" ;
VAL_ 1016 UI_fuseVehiclesDisable 1 "FUSE_VEH_OFF" 0 "FUSE_VEH_ON" ;
VAL_ 1016 UI_handsOnRequirementDisable 1 "HANDS_ON_REQ_OFF" 0 "HANDS_ON_REQ_ON" ;
VAL_ 1016 UI_lssElkEnabled 0 "ELK_OFF" 1 "ELK_ON" ;
VAL_ 1016 UI_lssLdwEnabled 0 "LDW_OFF" 1 "LDW_ON" ;
VAL_ 1016 UI_lssLkaEnabled 0 "LKA_OFF" 1 "LKA_ON" ;
VAL_ 1016 UI_roadCheckDisable 1 "RC_OFF" 0 "RC_ON" ;
VAL_ 1016 UI_selfParkRequest 3 "ABORT" 9 "AUTO_SUMMON_CANCEL" 7 "AUTO_SUMMON_FORWARD" 10 "AUTO_SUMMON_PRIMED" 8 "AUTO_SUMMON_REVERSE" 0 "NONE" 5 "PAUSE" 4 "PRIME" 6 "RESUME" 1 "SELF_PARK_FORWARD" 2 "SELF_PARK_REVERSE" 11 "SMART_SUMMON" 12 "SMART_SUMMON_NO_OP" 15 "SNA" ;
VAL_ 1016 UI_smartSummonType 1 "FIND_ME" 0 "PIN_DROP" 2 "SMART_AUTOPARK" ;
VAL_ 1016 UI_source3D 2 "XYZ_PREDICTION" 0 "Z_FROM_MAP" 1 "Z_FROM_PATH_PREDICTION" ;
VAL_ 1016 UI_summonEntryType 3 "SNA" 0 "STRAIGHT" 2 "TURN_LEFT" 1 "TURN_RIGHT" ;
VAL_ 1016 UI_summonExitType 3 "SNA" 0 "STRAIGHT" 2 "TURN_LEFT" 1 "TURN_RIGHT" ;
VAL_ 1016 UI_summonReverseDist 63 "SNA" ;
VAL_ 1016 UI_ulcBlindSpotConfig 1 "AGGRESSIVE" 2 "MAD_MAX" 0 "STANDARD" ;
VAL_ 1016 UI_ulcSpeedConfig 2 "SPEED_BASED_ULC_AVERAGE" 0 "SPEED_BASED_ULC_DISABLED" 3 "SPEED_BASED_ULC_MAD_MAX" 1 "SPEED_BASED_ULC_MILD" ;
VAL_ 1016 UI_visionSpeedType 0 "VISION_SPEED_DISABLED" 1 "VISION_SPEED_ONE_SECOND" 3 "VISION_SPEED_OPTIMIZED" 2 "VISION_SPEED_TWO_SECOND" ;
VAL_ 1017 VCSEC_matrixIndex 0 "AlertMatrix0" 1 "AlertMatrix1" 2 "AlertMatrix2" 3 "AlertMatrix3";
VAL_ 1018 APP_backupCameraLUX 254 "SATURATED" 255 "SNA";
VAL_ 1018 APP_fisheyeCameraLUX 254 "SATURATED" 255 "SNA";
VAL_ 1018 APP_lPillarCameraLUX 254 "SATURATED" 255 "SNA";
VAL_ 1018 APP_lRepeatCameraLUX 254 "SATURATED" 255 "SNA";
VAL_ 1018 APP_mainCameraLUX 254 "SATURATED" 255 "SNA";
VAL_ 1018 APP_narrowCameraLUX 254 "SATURATED" 255 "SNA";
VAL_ 1018 APP_rPillarCameraLUX 254 "SATURATED" 255 "SNA";
VAL_ 1018 APP_rRepeatCameraLUX 254 "SATURATED" 255 "SNA";
VAL_ 1020 APP_decisionTemperature 0 "UNKNOWN";
VAL_ 1020 APP_parkerATemperature 0 "UNKNOWN";
VAL_ 1020 APP_parkerBTemperature 0 "UNKNOWN";
VAL_ 1020 APP_parkerExtTemperature 0 "UNKNOWN";
VAL_ 1020 APP_pascalExtTemperature 0 "UNKNOWN";
VAL_ 1020 APP_pascalHeaterDecision 0 "OFF" 1 "ON";
VAL_ 1020 APP_pascalTemperature 0 "UNKNOWN";
VAL_ 1021 UI_autopilotControlIndex 0 "AUTOPILOT_CONTROL_0" 1 "AUTOPILOT_CONTROL_1" 2 "AUTOPILOT_CONTROL_2" 3 "AUTOPILOT_CONTROL_3" 4 "AUTOPILOT_CONTROL_4" 5 "AUTOPILOT_CONTROL_5" 6 "AUTOPILOT_CONTROL_6" 7 "AUTOPILOT_CONTROL_7" ;
VAL_ 1021 UI_apmv3Branch 5 "DEMO" 2 "DEV" 4 "EAP" 0 "LIVE" 1 "STAGE" 3 "STAGE2" ;
VAL_ 1021 UI_blindspotDistance 1 "BLINDSPOT_DISTANCE_0P5_M" 2 "BLINDSPOT_DISTANCE_1_M" 3 "BLINDSPOT_DISTANCE_2_M" 4 "BLINDSPOT_DISTANCE_4_M" 0 "BLINDSPOT_DISTANCE_DEFAULT" 5 "BLINDSPOT_DISTANCE_OFF" ;
VAL_ 1021 UI_blindspotMinSpeed 2 "BLINDSPOT_MIN_SPEED_10_KPH" 3 "BLINDSPOT_MIN_SPEED_15_KPH" 4 "BLINDSPOT_MIN_SPEED_20_KPH" 5 "BLINDSPOT_MIN_SPEED_25_KPH" 6 "BLINDSPOT_MIN_SPEED_30_KPH" 7 "BLINDSPOT_MIN_SPEED_35_KPH" 8 "BLINDSPOT_MIN_SPEED_40_KPH" 9 "BLINDSPOT_MIN_SPEED_45_KPH" 1 "BLINDSPOT_MIN_SPEED_5_KPH" 0 "BLINDSPOT_MIN_SPEED_DEFAULT" 10 "BLINDSPOT_MIN_SPEED_OFF" ;
VAL_ 1021 UI_blindspotTTC 1 "BLINDSPOT_TTC_0P5_S" 2 "BLINDSPOT_TTC_1_S" 3 "BLINDSPOT_TTC_2_S" 5 "BLINDSPOT_TTC_3_S" 4 "BLINDSPOT_TTC_4_S" 6 "BLINDSPOT_TTC_5_S" 0 "BLINDSPOT_TTC_DEFAULT" 7 "BLINDSPOT_TTC_OFF" ;
VAL_ 1021 UI_donAlcProgGoreAbortThres 1 "DON_ALC_PROGRESS_GORE_ABORT_THRESHOLD_0P00" 2 "DON_ALC_PROGRESS_GORE_ABORT_THRESHOLD_0P05" 3 "DON_ALC_PROGRESS_GORE_ABORT_THRESHOLD_0P10" 4 "DON_ALC_PROGRESS_GORE_ABORT_THRESHOLD_0P15" 5 "DON_ALC_PROGRESS_GORE_ABORT_THRESHOLD_0P20" 6 "DON_ALC_PROGRESS_GORE_ABORT_THRESHOLD_0P25" 7 "DON_ALC_PROGRESS_GORE_ABORT_THRESHOLD_0P30" 8 "DON_ALC_PROGRESS_GORE_ABORT_THRESHOLD_0P35" 9 "DON_ALC_PROGRESS_GORE_ABORT_THRESHOLD_0P40" 0 "DON_ALC_PROGRESS_GORE_ABORT_THRESHOLD_DEFAULT" ;
VAL_ 1021 UI_donDisableAutoWiperDuration 5 "DON_DISABLE_AUTO_WIPER_DURATION_120_S" 2 "DON_DISABLE_AUTO_WIPER_DURATION_15_S" 3 "DON_DISABLE_AUTO_WIPER_DURATION_30_S" 1 "DON_DISABLE_AUTO_WIPER_DURATION_5_S" 4 "DON_DISABLE_AUTO_WIPER_DURATION_60_S" 0 "DON_DISABLE_AUTO_WIPER_DURATION_DEFAULT" 6 "DON_DISABLE_AUTO_WIPER_DURATION_OFF" ;
VAL_ 1021 UI_donDisableCutin 0 "DON_DISABLE_CUTIN_OFF" 1 "DON_DISABLE_CUTIN_ON" ;
VAL_ 1021 UI_donDisableOnAutoWiperSpeed 1 "DAS_WIPER_SPEED_1" 10 "DAS_WIPER_SPEED_10" 11 "DAS_WIPER_SPEED_11" 12 "DAS_WIPER_SPEED_12" 13 "DAS_WIPER_SPEED_13" 14 "DAS_WIPER_SPEED_14" 2 "DAS_WIPER_SPEED_2" 3 "DAS_WIPER_SPEED_3" 4 "DAS_WIPER_SPEED_4" 5 "DAS_WIPER_SPEED_5" 6 "DAS_WIPER_SPEED_6" 7 "DAS_WIPER_SPEED_7" 8 "DAS_WIPER_SPEED_8" 9 "DAS_WIPER_SPEED_9" 15 "DAS_WIPER_SPEED_INVALID" 0 "DAS_WIPER_SPEED_OFF" ;
VAL_ 1021 UI_donMinGoreWidthForAbortMap 2 "DON_MIN_GORE_WIDTH_FOR_ABORT_0P5_M" 1 "DON_MIN_GORE_WIDTH_FOR_ABORT_0_M" 4 "DON_MIN_GORE_WIDTH_FOR_ABORT_1P5_M" 3 "DON_MIN_GORE_WIDTH_FOR_ABORT_1_M" 6 "DON_MIN_GORE_WIDTH_FOR_ABORT_2P5_M" 5 "DON_MIN_GORE_WIDTH_FOR_ABORT_2_M" 8 "DON_MIN_GORE_WIDTH_FOR_ABORT_3P5_M" 7 "DON_MIN_GORE_WIDTH_FOR_ABORT_3_M" 10 "DON_MIN_GORE_WIDTH_FOR_ABORT_4P5_M" 9 "DON_MIN_GORE_WIDTH_FOR_ABORT_4_M" 11 "DON_MIN_GORE_WIDTH_FOR_ABORT_5_M" 0 "DON_MIN_GORE_WIDTH_FOR_ABORT_DEFAULT" ;
VAL_ 1021 UI_donMinGoreWidthForAbortNotMap 2 "DON_MIN_GORE_WIDTH_FOR_ABORT_0P5_M" 1 "DON_MIN_GORE_WIDTH_FOR_ABORT_0_M" 4 "DON_MIN_GORE_WIDTH_FOR_ABORT_1P5_M" 3 "DON_MIN_GORE_WIDTH_FOR_ABORT_1_M" 6 "DON_MIN_GORE_WIDTH_FOR_ABORT_2P5_M" 5 "DON_MIN_GORE_WIDTH_FOR_ABORT_2_M" 8 "DON_MIN_GORE_WIDTH_FOR_ABORT_3P5_M" 7 "DON_MIN_GORE_WIDTH_FOR_ABORT_3_M" 10 "DON_MIN_GORE_WIDTH_FOR_ABORT_4P5_M" 9 "DON_MIN_GORE_WIDTH_FOR_ABORT_4_M" 11 "DON_MIN_GORE_WIDTH_FOR_ABORT_5_M" 0 "DON_MIN_GORE_WIDTH_FOR_ABORT_DEFAULT" ;
VAL_ 1021 UI_donStopEndOfRampBuffer 1 "DON_STOP_END_OF_RAMP_BUFFER_15_M" 2 "DON_STOP_END_OF_RAMP_BUFFER_30_M" 3 "DON_STOP_END_OF_RAMP_BUFFER_45_M" 0 "DON_STOP_END_OF_RAMP_BUFFER_DEFAULT" 4 "DON_STOP_END_OF_RAMP_BUFFER_OFF" ;
VAL_ 1021 UI_homelinkNearby 1 "HOMELINK_NEARBY" 0 "HOMELINK_NOT_NEARBY" ;
VAL_ 1021 UI_hovEnabled 0 "HOV_OFF" 1 "HOV_ON" ;
VAL_ 1056 UIS_logMux 247 "activeAppView" 246 "amdSocPkgPower" 245 "audioA2BRediscoveryCount" 244 "audioMediaBrowsing" 243 "audioMediaPlaying" 242 "audioSource" 241 "audioState" 240 "audioType" 239 "audioVolumeLevel" 238 "bluetoothAutoConnectionState" 237 "bluetoothCPUUsage" 236 "bluetoothConnectionState" 235 "bluetoothMemUsage" 234 "bluetoothPairResult" 233 "bluetoothStackState" 232 "boardTemperature" 231 "bootCount" 230 "cameraBackupFramerate" 229 "cameraBackupLateFrames" 228 "cameraBackupMaxFrametime" 227 "cameraBackupPipeline" 226 "cameraBackupPopup" 225 "cameraBackupStream" 224 "cameraBackupStreamMissing" 223 "cameraBackupStreamQuality" 222 "cameraLRepeaterFramerate" 221 "cameraLRepeaterLateFrames" 220 "cameraLRepeaterMaxFrametime" 219 "cameraLRepeaterPipeline" 218 "cameraLRepeaterPopup" 217 "cameraLRepeaterStream" 216 "cameraLRepeaterStreamMissing" 215 "cameraRRepeaterFramerate" 214 "cameraRRepeaterLateFrames" 213 "cameraRRepeaterMaxFrametime" 212 "cameraRRepeaterPipeline" 211 "cameraRRepeaterPopup" 210 "cameraRRepeaterStream" 209 "cameraRRepeaterStreamMissing" 208 "cellularLinkManagerState" 207 "centerDispAsilA_lsb" 206 "centerDispAsilA_msb" 205 "centerDispAsilB_lsb" 204 "centerDispAsilB_msb" 203 "centerDisplayState" 202 "ceruleanx8664CPUUsage" 201 "ceruleanx8664MemUsage" 200 "clusterCPUUsage" 199 "clusterDisplayState" 198 "clusterFramesOver100Ms" 197 "clusterFramesOver200Ms" 196 "clusterMaxFrametime" 195 "clusterMeanFPS" 194 "clusterMemUsage" 193 "cobaltlinuxCPUUsage" 192 "cobaltlinuxMemUsage" 191 "compositorRenderFrameRate" 190 "compositorRenderMaxFrameTime" 189 "compositorRenderMinFrameTime" 188 "cpuTemperature" 187 "dashcamOnboardAvailableMB" 186 "dashcamOnboardMB" 185 "dashcamOnboardSavePressCount" 184 "dashcamOnboardTransferCount" 183 "dashcamSavedToOnboardCount" 182 "dashcamSavedToSavedCount" 181 "dashcamSavedToSentryCount" 180 "dashcamState" 179 "dashcamStorageAvailableMB" 178 "dashcamStorageRecentMB" 177 "dashcamStorageSavedMB" 176 "dashcamStorageSentryMB" 175 "dashcamStorageState" 174 "dashcamTransferCount" 173 "dashcamTransferFileCount" 172 "dashcamTransferRateMBps" 171 "dashcamTransferSizeMB" 170 "dashcamTransferTimeMs" 169 "dashcamviewerCPUUsage" 168 "dashcamviewerMemUsage" 167 "developerMode" 166 "dgpuTemperature" 165 "dmCenterBacklightDevExists" 164 "dmCenterBacklightDutyCycle" 163 "dmCenterBacklightFault" 162 "dmCenterBacklightPowerLevel" 161 "dmCenterLinkCheckOk" 160 "dmCenterMOsdExactCrcCheck" 159 "dmCenterMOsdVideoCrcData" 158 "dmCenterModeSettingStatus" 157 "dmCenterOsdDayNightState" 156 "dmCenterOsdDisplayedState" 155 "dmCenterPowerState" 154 "dmCenterSOsdExactCrcCheck" 153 "dmCenterSOsdVideoCrcData" 152 "dmCenterTouchDeviceExists" 151 "dmGatewayLinkWedged" 150 "dmIcuBacklightDevExists" 149 "dmIcuBacklightDutyCycle" 148 "dmIcuBacklightFault" 147 "dmIcuBacklightPowerLevel" 146 "dmIcuLinkCheckOk" 145 "dmIcuPowerState" 144 "dmRearBacklightDevExists" 143 "dmRearBacklightDutyCycle" 142 "dmRearBacklightFault" 141 "dmRearBacklightPowerLevel" 140 "dmRearLinkCheckOk" 139 "dmRearPowerState" 138 "dmRearTouchDeviceExists" 137 "embeddedGameName" 136 "embeddedGameState" 135 "godotCPUUsage" 134 "godotMemUsage" 133 "godot_MEMORY_DYNAMIC" 132 "godot_MEMORY_STATIC" 131 "godot_TIME_FPS" 130 "godot_TIME_PROCESS" 129 "gpsmanagerCPUUsage" 128 "gpsmanagerMemUsage" 127 "hermesclientCPUUsage" 126 "hermesclientMemUsage" 125 "hermesdynamicCPUUsage" 124 "hermesdynamicMemUsage" 123 "igpuTemperature" 122 "inSuperchargerGeofence" 121 "limex8664CPUUsage" 120 "limex8664MemUsage" 119 "mediaImageCacheCost" 118 "mediaImageCacheSize" 117 "mediaNeedAuthToken" 116 "mediaPlaybackStatus" 115 "mediaserveCPUUsage" 114 "mediaserveMemUsage" 113 "mounterdDashcamCapacityGB" 112 "mounterdDeviceCount" 111 "mounterdEncryptionCapacityGB" 110 "mounterdFilesystemCountExfat" 109 "mounterdFilesystemCountExt3" 108 "mounterdFilesystemCountExt4" 107 "mounterdFilesystemCountFat32" 106 "mounterdFrontHubConnected" 105 "mounterdFrontHubDisconnected" 104 "mounterdMountCountTotal" 103 "mounterdState" 102 "nuanceserverCPUUsage" 101 "nuanceserverMemUsage" 100 "numCorrMemErrorsECC" 99 "numUncorrMemErrorsECC" 98 "nvmeDataUnitsWritten100mb" 97 "nvmePercentLifetimeUsed" 96 "nvmeTemperature" 95 "odinAuthCount" 94 "odinAuthFailCount" 93 "odinCPUUsage" 92 "odinGatewayConnectionState" 91 "odinHermesConnectionState" 90 "odinListTasksCmdDurationMs" 89 "odinListTasksCmdResult" 88 "odinMemUsage" 87 "odinNetworkFailCount" 86 "odinNetworkStartCount" 85 "odinOrchestratorFailCount" 84 "odinOrchestratorStartCount" 83 "odinProcessState" 82 "odinStatusCmdDurationMs" 81 "odinStatusCmdResult" 80 "odincefCPUUsage" 79 "odincefMemUsage" 78 "polytopiax8664CPUUsage" 77 "polytopiax8664MemUsage" 76 "psiCpuFull" 75 "psiIOFull" 74 "psiIOSome" 73 "psiMemFull" 72 "psiMemSome" 71 "qtcarCPUUsage" 70 "qtcarMemUsage" 69 "radioserveCPUUsage" 68 "radioserveMemUsage" 67 "rearDisplayState" 66 "releasenotesCPUUsage" 65 "releasenotesMemUsage" 64 "sentryIncidentCount" 63 "sentryNeedsNap" 62 "sentryState" 61 "serverCPUUsage" 60 "serverMemUsage" 59 "settingsAutoTurnSignal" 58 "sleepCount" 57 "sleepState" 56 "sleepTime" 55 "sleepType" 54 "solitaireCPUUsage" 53 "solitaireMemUsage" 52 "speechrecoCPUUsage" 51 "speechrecoMemUsage" 50 "spotifyserverCPUUsage" 49 "spotifyserverMemUsage" 48 "sudokuCPUUsage" 47 "sudokuMemUsage" 46 "systemMemSwapUsage" 45 "systemUptime" 44 "tegraModemManState" 43 "teslaMediaCacheCost" 42 "teslaMediaCacheSize" 41 "teslacefgpuCPUUsage" 40 "teslacefgpuMemUsage" 39 "teslacefzygotCPUUsage" 38 "teslacefzygotMemUsage" 37 "teslachromiumCPUUsage" 36 "teslachromiumMemUsage" 35 "tmserverCPUUsage" 34 "tmserverMemUsage" 33 "touchEventsAggCount" 32 "uiFramesOver100Ms" 31 "uiFramesOver200Ms" 30 "uiMaxFrametime" 29 "uiMeanFPS" 28 "uiQtCarSwapUsage" 27 "uiQtCarUptime" 26 "valetMode" 25 "valhallaserverCPUUsage" 24 "valhallaserverMemUsage" 23 "vehicleCPUUsage" 22 "vehicleMemUsage" 21 "videodCPUUsage" 20 "videodMemUsage" 19 "vmtouchCPUUsage" 18 "vmtouchMemUsage" 17 "webbrowserCPUUsage" 16 "webbrowserMemUsage" 15 "wifiAutoJoinLowRSSI" 14 "wifiBars" 13 "wifiStackReady" 12 "wifiStackState" 11 "wifiTemperature" 10 "zramCompressedSize" 9 "zramCompressionRatio" 8 "zramFailedReads" 7 "zramFailedWrites" 6 "zramInvalidIO" 5 "zramNotifyFree" 4 "zramOriginalSize" 3 "zramReadIO" 2 "zramReadTicks" 1 "zramWriteIO" 0 "zramWriteTicks" ;
VAL_ 1056 UIS_odinGatewayConnectionState 1 "GATEWAY_CONNECTED" 2 "GATEWAY_CONNECTION_ERROR" 0 "GATEWAY_DISCONNECTED" ;
VAL_ 1056 UIS_odinHermesConnectionState 1 "HERMES_CONNECTED" 2 "HERMES_CONNECTING" 3 "HERMES_CONNECTION_ERROR" 0 "HERMES_DISCONNECTED" ;
VAL_ 1056 UIS_odinListTasksCmdResult 2 "EXCEPTION" 1 "FAIL" 0 "PASS" ;
VAL_ 1056 UIS_odinProcessState 0 "IDLE" 1 "RUNNING_NETWORK" 3 "RUNNING_NETWORK_AND_ORCHESTRATOR" 2 "RUNNING_ORCHESTRATOR" 4 "UNKNOWN" ;
VAL_ 1056 UIS_odinStatusCmdResult 2 "EXCEPTION" 1 "FAIL" 0 "PASS" ;
VAL_ 1066 VCSEC_TPMSConnectionTypeCurrent0 0 "CONNECTIONTYPE_FAST" 1 "CONNECTIONTYPE_SLOW" 2 "CONNECTIONTYPE_UNKNOWN" ;
VAL_ 1066 VCSEC_TPMSConnectionTypeCurrent1 0 "CONNECTIONTYPE_FAST" 1 "CONNECTIONTYPE_SLOW" 2 "CONNECTIONTYPE_UNKNOWN" ;
VAL_ 1066 VCSEC_TPMSConnectionTypeCurrent2 0 "CONNECTIONTYPE_FAST" 1 "CONNECTIONTYPE_SLOW" 2 "CONNECTIONTYPE_UNKNOWN" ;
VAL_ 1066 VCSEC_TPMSConnectionTypeCurrent3 0 "CONNECTIONTYPE_FAST" 1 "CONNECTIONTYPE_SLOW" 2 "CONNECTIONTYPE_UNKNOWN" ;
VAL_ 1066 VCSEC_TPMSConnectionTypeDesired0 0 "CONNECTIONTYPE_FAST" 1 "CONNECTIONTYPE_SLOW" 2 "CONNECTIONTYPE_UNKNOWN" ;
VAL_ 1066 VCSEC_TPMSConnectionTypeDesired1 0 "CONNECTIONTYPE_FAST" 1 "CONNECTIONTYPE_SLOW" 2 "CONNECTIONTYPE_UNKNOWN" ;
VAL_ 1066 VCSEC_TPMSConnectionTypeDesired2 0 "CONNECTIONTYPE_FAST" 1 "CONNECTIONTYPE_SLOW" 2 "CONNECTIONTYPE_UNKNOWN" ;
VAL_ 1066 VCSEC_TPMSConnectionTypeDesired3 0 "CONNECTIONTYPE_FAST" 1 "CONNECTIONTYPE_SLOW" 2 "CONNECTIONTYPE_UNKNOWN" ;
VAL_ 1066 VCSEC_TPMSSensorState0 3 "SENSOR_CONNECTED" 4 "SENSOR_DISCONNECTING" 0 "SENSOR_NOT_PAIRED" 1 "SENSOR_WAIT_FOR_ADV" 2 "SENSOR_WAIT_FOR_CONN" ;
VAL_ 1066 VCSEC_TPMSSensorState1 3 "SENSOR_CONNECTED" 4 "SENSOR_DISCONNECTING" 0 "SENSOR_NOT_PAIRED" 1 "SENSOR_WAIT_FOR_ADV" 2 "SENSOR_WAIT_FOR_CONN" ;
VAL_ 1066 VCSEC_TPMSSensorState2 3 "SENSOR_CONNECTED" 4 "SENSOR_DISCONNECTING" 0 "SENSOR_NOT_PAIRED" 1 "SENSOR_WAIT_FOR_ADV" 2 "SENSOR_WAIT_FOR_CONN" ;
VAL_ 1066 VCSEC_TPMSSensorState3 3 "SENSOR_CONNECTED" 4 "SENSOR_DISCONNECTING" 0 "SENSOR_NOT_PAIRED" 1 "SENSOR_WAIT_FOR_ADV" 2 "SENSOR_WAIT_FOR_CONN" ;
VAL_ 1080 GTW_VEHWakeUpReason 0 "NONE" 1 "RESET" 2 "GSM_RI" 3 "CH_CAN" 4 "VEH_CAN" 5 "VEH_CAN" 6 "VCFRONT" 7 "RTC_ALARM" 8 "UI_SCHEDULED";
VAL_ 1085 CP_chargeShutdownRequest_log 2 "EMERGENCY_SHUTDOWN_REQUESTED" 1 "GRACEFUL_SHUTDOWN_REQUESTED" 0 "NO_SHUTDOWN_REQUESTED" ;
VAL_ 1085 CP_evseChargeType_log 2 "AC_CHARGER_PRESENT" 1 "DC_CHARGER_PRESENT" 0 "NO_CHARGER_PRESENT" ;
VAL_ 1085 CP_hvChargeStatus_log 1 "CP_CHARGE_CONNECTED" 5 "CP_CHARGE_ENABLED" 6 "CP_CHARGE_FAULTED" 0 "CP_CHARGE_INACTIVE" 2 "CP_CHARGE_STANDBY" 4 "CP_EVSE_TEST_PASSED" 3 "CP_EXT_EVSE_TEST_ACTIVE" ;
VAL_ 1096 UI_anonDebugFlag1 0 "OFF" 1 "ON";
VAL_ 1096 UI_anonDebugFlag2 0 "OFF" 1 "ON";
VAL_ 1096 UI_anonDebugFlag3 0 "OFF" 1 "ON";
VAL_ 1096 UI_anonDebugFlag4 0 "OFF" 1 "ON";
VAL_ 1112 GTW_nmKeepAwakeReason 0 "NONE_SNA" 15 "TBD";
VAL_ 1112 GTW_nmWakeUpReason 0 "NONE" 1 "RESET" 2 "GSM_RI" 3 "CH_CAN" 4 "VEH_CAN" 5 "VEH_CAN" 6 "VCFRONT" 7 "RTC_ALARM" 8 "UI_SCHEDULED";
VAL_ 1139 UI_nmKeepAwakeReason 0 "NONE_SNA" 1 "KEEPALIVEACTIVE" 2 "GUI_NEVER_SLEEP_SET" 3 "PM_CHECKING" 4 "UNKNOWN_REMOTE_REQUEST" 5 "MODEM_RESET" 6 "UPDATER" 7 "HERMES" 8 "AUTOFUSER" 9 "UPDATE_COUNTDOWN" 15 "MULTIPLE";
VAL_ 1160 DAS_steeringControlType 2 "LANE_KEEP_ASSIST" 0 "NONE" 1 "ANGLE_CONTROL" 3 "EMERGENCY_LANE_KEEP" ;
VAL_ 1160 DAS_steeringAngleRequest 16384 "ZERO_ANGLE" ;
VAL_ 1170 BMS_sohTestState 8 "ABORTED" 5 "CHARGE" 7 "COMPLETE" 4 "DISCHARGE" 3 "HEAT_PACK" 0 "NOT_READY" 1 "READY" 6 "RESTING" 2 "SAMPLE_CHARGE_POWER" ;
VAL_ 1170 BMS_stateOfHealth 1023 "SNA" ;
VAL_ 1177 APP_lRepeaterCameraTemperature 255 "SNA" ;
VAL_ 1177 APP_rRepeaterCameraTemperature 255 "SNA" ;
VAL_ 1250 VCLEFT_seatStatusIndex 1 "SEAT_STATUS_INDEX_BACK" 2 "SEAT_STATUS_INDEX_LIFT" 4 "SEAT_STATUS_INDEX_LUMBAR" 6 "SEAT_STATUS_INDEX_OFFSETS" 5 "SEAT_STATUS_INDEX_POSITION" 3 "SEAT_STATUS_INDEX_TILT" 0 "SEAT_STATUS_INDEX_TRACK" ;
VAL_ 1251 VCRIGHT_seatStatusIndex 1 "SEAT_STATUS_INDEX_BACK" 2 "SEAT_STATUS_INDEX_LIFT" 4 "SEAT_STATUS_INDEX_LUMBAR" 6 "SEAT_STATUS_INDEX_OFFSETS" 5 "SEAT_STATUS_INDEX_POSITION" 3 "SEAT_STATUS_INDEX_TILT" 0 "SEAT_STATUS_INDEX_TRACK" ;
VAL_ 1280 UI_debugEcuTarget 1 "DI" 2 "DIS" 3 "PM" 4 "PMS" 5 "BMS" 6 "VCRIGHT" 7 "VCFRONT";
VAL_ 1329 RADC_infoIndex 10 "Mux10" 11 "Mux11" 13 "Mux13" 19 "Mux19" 20 "Mux20";
VAL_ 1329 RADC_infoBuildType 0 "UNKNOWN_BUILD" 1 "PLATFORM_BUILD" 2 "LOCAL_BUILD" 3 "TRACEABLE_CI_BUILD" 4 "MFG_BUILD";
VAL_ 1337 DAS_infoIndex 0 "DEPRECATED_0" 1 "DEPRECATED_1" 2 "DEPRECATED_2" 3 "DEPRECATED_3" 4 "DEPRECATED_4" 5 "DEPRECATED_5" 6 "DEPRECATED_6" 7 "DEPRECATED_7" 8 "DEPRECATED_8" 9 "DEPRECATED_9" 10 "BUILD_HWID_COMPONENTID" 11 "PCBAID_ASSYID_USAGEID" 13 "APP_CRC" 14 "BOOTLOADER_SVN" 15 "BOOTLOADER_CRC" 16 "EYEQ_BOOT" 17 "APP_GITHASH" 18 "BOOTLOADER_GITHASH" 19 "VERSION_DEPRECATED" 20 "UDS_PROTOCOL_BOOTCRC" 23 "EYEQ_APP" 24 "EYEQ_FFS" 255 "END";
VAL_ 1337 DAS_infoBuildType 0 "UNKNOWN_BUILD" 1 "PLATFORM_BUILD" 2 "LOCAL_BUILD" 3 "TRACEABLE_CI_BUILD" 4 "MFG_BUILD";
VAL_ 1337 DAS_infoHardwareRevision 252 "CONFIGURABLE_HWID_PLACEHOLDER";
VAL_ 1342 CP_infoIndex 0 "DEPRECATED_0" 1 "DEPRECATED_1" 2 "DEPRECATED_2" 3 "DEPRECATED_3" 4 "DEPRECATED_4" 5 "DEPRECATED_5" 6 "DEPRECATED_6" 7 "DEPRECATED_7" 8 "DEPRECATED_8" 9 "DEPRECATED_9" 10 "BUILD_HWID_COMPONENTID" 11 "PCBAID_ASSYID_USAGEID" 13 "APP_CRC" 14 "BOOTLOADER_SVN" 15 "BOOTLOADER_CRC" 16 "SUBCOMPONENT" 17 "APP_GITHASH" 18 "BOOTLOADER_GITHASH" 19 "VERSION_DEPRECATED" 20 "UDS_PROTOCOL_BOOTCRC" 22 "VARIANTCRC" 25 "PACKAGE_PN_1_7" 26 "PACKAGE_PN_8_14" 27 "PACKAGE_PN_15_20" 29 "PACKAGE_SN_1_7" 30 "PACKAGE_SN_8_14" 31 "SUBCOMPONENT_GITHASH" 255 "END";
VAL_ 1342 CP_buildType 0 "UNKNOWN_BUILD" 1 "PLATFORM_BUILD" 2 "LOCAL_BUILD" 3 "TRACEABLE_CI_BUILD" 4 "MFG_BUILD";
VAL_ 1353 APP_infoIndex 0 "AP_BUILD_TYPE" 1 "FW_GITHASH" 2 "AP_GITHASH";
VAL_ 1353 APP_buildType 0 "SIGNED" 1 "LOCAL" 3 "REPO";
VAL_ 1357 TAS_infoIndex 0 "DEPRECATED_0" 1 "DEPRECATED_1" 2 "DEPRECATED_2" 3 "DEPRECATED_3" 4 "DEPRECATED_4" 5 "DEPRECATED_5" 6 "DEPRECATED_6" 7 "DEPRECATED_7" 8 "DEPRECATED_8" 9 "DEPRECATED_9" 10 "BUILD_HWID_COMPONENTID" 11 "PCBAID_ASSYID_USAGEID" 13 "APP_CRC" 14 "BOOTLOADER_SVN" 15 "BOOTLOADER_CRC" 16 "SUBCOMPONENT1" 17 "APP_GITHASH" 18 "BOOTLOADER_GITHASH" 19 "VERSION_DEPRECATED" 20 "UDS_PROTOCOL_BOOTCRC" 23 "SUBCOMPONENT2" 24 "SUBCOMPONENT3" 31 "SUBCOMPONENT4" 255 "END";
VAL_ 1357 TAS_infoBuildType 0 "UNKNOWN_BUILD" 1 "PLATFORM_BUILD" 2 "LOCAL_BUILD" 3 "TRACEABLE_CI_BUILD" 4 "MFG_BUILD";
VAL_ 1357 TAS_infoAssemblyId 1 "ASSEMBLY1" 255 "ASSEMBLY_SNA";
VAL_ 1357 TAS_infoMajorVersion 254 "LOCAL_BUILD" 255 "SNA";
VAL_ 1357 TAS_infoBranchOrigin 254 "LOCAL_BUILD" 255 "SNA";
VAL_ 1357 TAS_infoMaturity 254 "LOCAL_BUILD" 255 "SNA";
VAL_ 1357 TAS_infoHardwareRevision 254 "LOCAL_BUILD" 255 "SNA";
VAL_ 1359 SCCM_matrixIndex 0 "SCCM_AlertMatrix0";
VAL_ 1366 DIF_IGBTJunctTemp 255 "SNA" ;
VAL_ 1493 DI_IGBTJunctTemp 255 "SNA" ;
VAL_ 1519 TPMS_infoIndex 0 "DEPRECATED_0" 1 "DEPRECATED_1" 2 "DEPRECATED_2" 3 "DEPRECATED_3" 4 "DEPRECATED_4" 5 "DEPRECATED_5" 6 "DEPRECATED_6" 7 "DEPRECATED_7" 8 "DEPRECATED_8" 9 "DEPRECATED_9" 10 "BUILD_HWID_COMPONENTID" 11 "PCBAID_ASSYID_USAGEID" 13 "APP_CRC" 14 "BOOTLOADER_SVN" 15 "BOOTLOADER_CRC" 16 "SUBCOMPONENT" 17 "APP_GITHASH" 18 "BOOTLOADER_GITHASH" 19 "VERSION_DEPRECATED" 20 "UDS_PROTOCOL_BOOTCRC" 22 "VARIANTCRC" 25 "PACKAGE_PN_1_7" 26 "PACKAGE_PN_8_14" 27 "PACKAGE_PN_15_20" 29 "PACKAGE_SN_1_7" 30 "PACKAGE_SN_8_14" 31 "SUBCOMPONENT_GITHASH" 255 "END";
VAL_ 1523 UI_alertID 0 "ALERT_DO_NOT_USE_ZERO" 1 "a001_DriverDoorOpen" 2 "a002_DoorOpen" 3 "a003_TrunkOpen" 4 "a004_FrunkOpen" 5 "a005_HeadlightsOnDoorOpen" 6 "a006_RemoteServiceAlert" 7 "a007_SoftPackConfigMismatch" 8 "a008_TouchScreenError" 9 "a009_SquashfsError" 10 "a010_MapsMissing" 11 "a011_IncorrectMap" 12 "a012_NotOnPrivateProperty" 13 "a013_TPMSHardWarning" 14 "a014_TPMSSoftWarning" 15 "a015_TPMSOverPressureWarning" 16 "a016_TPMSTemperatureWarning" 17 "a017_TPMSSystemFault" 18 "a018_SlipStartOn" 19 "a019_ParkBrakeFault" 20 "a020_SteeringReduced" 21 "a021_RearSeatbeltUnbuckled" 22 "a022_ApeFusesEtc" 23 "a023_CellInternetCheckFailed" 24 "a024_WifiInternetCheckFailed" 25 "a025_WifiOnlineCheckFailed" 26 "a026_ModemResetLoopDetected" 27 "a027_AutoSteerMIA" 28 "a028_FrontTrunkPopupClosed" 29 "a029_ModemMIA" 30 "a030_ModemVMCrash" 31 "a031_BrakeFluidLow" 32 "a032_CellModemRecoveryResets" 33 "a033_ApTrialExpired" 34 "a034_WakeupProblem" 35 "a035_AudioWatchdogKernelError" 36 "a036_AudioWatchdogHfpError" 37 "a037_AudioWatchdogXrunStormError" 38 "a038_AudioWatchdogA2bI2cLockupError" 39 "a039_AudioA2bNeedRediscovery" 40 "a040_HomelinkTransmit" 41 "a041_AudioDmesgXrun" 42 "a042_AudioDmesgRtThrottling" 43 "a043_InvalidMapDataOverride" 44 "a044_AudioDmesgDspException";
VAL_ 1523 UI_alertState 0 "CLEARED" 1 "SET";
VAL_ 1548 DAS_TR_ObjIndex 0 "Mux0" 1 "Mux1" 2 "Mux2" 3 "Mux3" 4 "Mux4" 5 "Mux5" 6 "Mux6" 7 "Mux7" 8 "Mux8" 9 "Mux9" 10 "Mux10" 11 "Mux11" 12 "Mux12" 13 "Mux13" 14 "Mux14" 15 "Mux15" 16 "Mux16" 17 "Mux17" 18 "Mux18" 19 "Mux19" 20 "Mux20" 21 "Mux21" 22 "Mux22" 23 "Mux23" 24 "Mux24" 25 "Mux25" 26 "Mux26" 27 "Mux27" 28 "Mux28" 29 "Mux29" 30 "Mux30" 31 "Mux31";
VAL_ 1548 DAS_TR_Obj00_Class 0 "UNKNOWN" 1 "MOVING_FOUR_WHEEL_VEHICLE" 2 "MOVING_TWO_WHEEL_VEHICLE" 3 "MOVING_PEDESTRIAN" 4 "CONSTRUCTION_ELEMENT";
VAL_ 1548 DAS_TR_Obj00_MovingState 0 "INDETERMINATE" 1 "MOVING" 2 "STOPPED" 3 "STANDING";
VAL_ 1622 DIF_infoIndex 13 "DI_INFO_APP_CRC" 17 "DI_INFO_APP_GITHASH" 15 "DI_INFO_BOOTLOADER_CRC" 18 "DI_INFO_BOOTLOADER_GITHASH" 14 "DI_INFO_BOOTLOADER_SVN" 10 "DI_INFO_BUILD_HWID_COMPONENTID" 0 "DI_INFO_DEPRECATED_0" 1 "DI_INFO_DEPRECATED_1" 2 "DI_INFO_DEPRECATED_2" 3 "DI_INFO_DEPRECATED_3" 4 "DI_INFO_DEPRECATED_4" 5 "DI_INFO_DEPRECATED_5" 6 "DI_INFO_DEPRECATED_6" 7 "DI_INFO_DEPRECATED_7" 8 "DI_INFO_DEPRECATED_8" 9 "DI_INFO_DEPRECATED_9" 255 "DI_INFO_END" 11 "DI_INFO_PCBAID_ASSYID_USAGEID" 16 "DI_INFO_SUBCOMPONENT" 23 "DI_INFO_SUBCOMPONENT2" 31 "DI_INFO_SUBCOMPONENT_GITHASH" 20 "DI_INFO_UDS_PROTOCOL_BOOTCRC" 19 "DI_INFO_VERSION_DEPRECATED" ;
VAL_ 1622 DIF_FPGA_version 254 "FPGA_VERSION_LOCAL_BUILD" 255 "FPGA_VERSION_SNA" ;
VAL_ 1622 DIF_buildType 2 "INFO_LOCAL_BUILD" 4 "INFO_MFG_BUILD" 1 "INFO_PLATFORM_BUILD" 3 "INFO_TRACEABLE_CI_BUILD" 0 "INFO_UNKNOWN_BUILD" ;
VAL_ 1622 DIF_hardwareId 252 "CONFIGURABLE_HWID_PLACEHOLDER" ;
VAL_ 1622 DIF_oilPumpBuildType 2 "INFO_LOCAL_BUILD" 4 "INFO_MFG_BUILD" 1 "INFO_PLATFORM_BUILD" 3 "INFO_TRACEABLE_CI_BUILD" 0 "INFO_UNKNOWN_BUILD" ;
VAL_ 1638 GTW_diagLevel 10 "LEVEL_DIAG_LINK_ACTIVE" 0 "LEVEL_FACTORY" 100 "LEVEL_NORMAL_OPERATION" 80 "LEVEL_PARK" 25 "LEVEL_SERVICE" 50 "LEVEL_SERVICE_DRIVE" ;
VAL_ 1655 VC_LVBMS_MOSState 1 "LVBMS_MOS_STATE_CLOSED" 2 "LVBMS_MOS_STATE_INVALID" 0 "LVBMS_MOS_STATE_OPEN" 3 "LVBMS_MOS_STATE_SNA" ;
VAL_ 1655 VC_LVBMS_packCurrent 4194303 "SNA" ;
VAL_ 1655 VC_LVBMS_packVoltage 65535 "SNA" ;
VAL_ 1655 VC_lvbmsStatusHighIndex 1 "LVBMS_STATUS_HIGH_CELL_VITALS_1" 2 "LVBMS_STATUS_HIGH_CELL_VITALS_2" 6 "LVBMS_STATUS_HIGH_INVALID" 0 "LVBMS_STATUS_HIGH_PACK_VITALS_1" 5 "LVBMS_STATUS_HIGH_PCS_INTERFACE" 4 "LVBMS_STATUS_HIGH_STATE_AND_COMMANDS" 3 "LVBMS_STATUS_HIGH_TARGETS" ;
VAL_ 1666 HVP_hvilStatus 2 "FAULT" 1 "OK" 0 "UNKNOWN" ;
VAL_ 1748 PMS_infoIndex 0 "DEPRECATED_0" 1 "DEPRECATED_1" 2 "DEPRECATED_2" 3 "DEPRECATED_3" 4 "DEPRECATED_4" 5 "DEPRECATED_5" 6 "DEPRECATED_6" 7 "DEPRECATED_7" 8 "DEPRECATED_8" 9 "DEPRECATED_9" 10 "BUILD_HWID_COMPONENTID" 11 "PCBAID_ASSYID_USAGEID" 13 "APP_CRC" 14 "BOOTLOADER_SVN" 15 "BOOTLOADER_CRC" 16 "SUBCOMPONENT" 17 "APP_GITHASH" 18 "BOOTLOADER_GITHASH" 19 "VERSION_DEPRECATED" 20 "UDS_PROTOCOL_BOOTCRC" 22 "VARIANTCRC" 25 "PACKAGE_PN_1_7" 26 "PACKAGE_PN_8_14" 27 "PACKAGE_PN_15_20" 29 "PACKAGE_SN_1_7" 30 "PACKAGE_SN_8_14" 31 "SUBCOMPONENT_GITHASH" 255 "END";
VAL_ 1748 PMS_buildType 0 "UNKNOWN_BUILD" 1 "PLATFORM_BUILD" 2 "LOCAL_BUILD" 3 "TRACEABLE_CI_BUILD" 4 "MFG_BUILD";
VAL_ 1748 PMS_hardwareId 252 "CONFIGURABLE_HWID_PLACEHOLDER";
VAL_ 1795 VCRIGHT_debugThermal10HzIndex 0 "heaterAndEvapWatts" 1 "temps" 2 "airflow" 3 "cabinModel" 4 "actuatorStatus" 5 "END";
VAL_ 1795 VCRIGHT_tempEvapAdjustmentLeft 255 "SNA";
VAL_ 1795 VCRIGHT_tempEvapAdjustmentRight 255 "SNA";
VAL_ 1795 VCRIGHT_cabinTempThs 255 "SNA";
VAL_ 1795 VCRIGHT_cabinTempThsBracket 255 "SNA";
VAL_ 1795 VCRIGHT_cabinTempProbe 255 "SNA";
VAL_ 1795 VCRIGHT_setTempAdjustmentLeft 255 "SNA";
VAL_ 1795 VCRIGHT_setTempAdjustmentRight 255 "SNA";
VAL_ 1816 VC_LVBMS_SOC 127 "SNA" ;
VAL_ 1816 VC_lvbmsStatusLowIndex 5 "LVBMS_STATUS_LOW_FAULT_STATS" 6 "LVBMS_STATUS_LOW_INVALID" 4 "LVBMS_STATUS_LOW_PACK_VITALS_2" 0 "LVBMS_STATUS_LOW_STATE" 1 "LVBMS_STATUS_LOW_THROUGHPUT_1" 2 "LVBMS_STATUS_LOW_THROUGHPUT_2" 3 "LVBMS_STATUS_LOW_THROUGHPUT_3" ;
VAL_ 1859 VCRIGHT_mirrorRecallStatus 2 "RECALL_COMPLETE" 3 "RECALL_INTERRUPTED" 1 "RECALL_IN_PROGRESS" 0 "RECALL_SNA" ;
VAL_ 1859 VCRIGHT_seatRecallStatus 2 "RECALL_COMPLETE" 3 "RECALL_INTERRUPTED" 1 "RECALL_IN_PROGRESS" 0 "RECALL_SNA" ;
VAL_ 1859 VCRIGHT_systemRecallStatus 2 "RECALL_COMPLETE" 3 "RECALL_INTERRUPTED" 1 "RECALL_IN_PROGRESS" 0 "RECALL_SNA" ;
VAL_ 1860 VCLEFT_columnRecallStatus 0 "SNA" 1 "IN_PROGRESS" 2 "COMPLETE" 3 "INTERRUPTED";
VAL_ 1860 VCLEFT_mirrorRecallStatus 0 "SNA" 1 "IN_PROGRESS" 2 "COMPLETE" 3 "INTERRUPTED";
VAL_ 1860 VCLEFT_seatRecallStatus 0 "SNA" 1 "IN_PROGRESS" 2 "COMPLETE" 3 "INTERRUPTED";
VAL_ 1860 VCLEFT_systemRecallStatus 0 "SNA" 1 "IN_PROGRESS" 2 "COMPLETE" 3 "INTERRUPTED";
VAL_ 1879 DIF_fluxState 5 "DI_FLUXSTATE_ENABLED" 9 "DI_FLUXSTATE_FAULT" 4 "DI_FLUXSTATE_FLUX_DOWN" 3 "DI_FLUXSTATE_FLUX_UP" 6 "DI_FLUXSTATE_ICONTROL" 2 "DI_FLUXSTATE_STANDBY" 0 "DI_FLUXSTATE_START" 10 "DI_FLUXSTATE_STATIONARY_WASTE" 1 "DI_FLUXSTATE_TEST" 7 "DI_FLUXSTATE_VCONTROL" ;
VAL_ 1879 DIF_gateDriveState 3 "PSTG_GD_STATE_CONFIGURED" 2 "PSTG_GD_STATE_CONFIGURING" 0 "PSTG_GD_STATE_INIT" 4 "PSTG_GD_STATE_NOT_CONFIGURED" 1 "PSTG_GD_STATE_SELFTEST" ;
VAL_ 1879 DIF_gateDriveSupplyState 0 "PSTG_GD_SUPPLY_DOWN" 3 "PSTG_GD_SUPPLY_FALLING" 1 "PSTG_GD_SUPPLY_RISING" 2 "PSTG_GD_SUPPLY_UP" ;
VAL_ 1879 DIF_magnetTempEst 0 "SNA" ;
VAL_ 1879 DIF_motorType 8 "DI_MOTOR_F1A" 10 "DI_MOTOR_F1AC" 11 "DI_MOTOR_F2AB" 12 "DI_MOTOR_F2AC" 13 "DI_MOTOR_F2AD" 14 "DI_MOTOR_F2AE" 26 "DI_MOTOR_F2AE_AL" 15 "DI_MOTOR_F2APMSRM" 17 "DI_MOTOR_IM100A" 19 "DI_MOTOR_IM100B" 22 "DI_MOTOR_IM130C" 24 "DI_MOTOR_IM130D" 25 "DI_MOTOR_IM130D_AL" 27 "DI_MOTOR_IM130D_AL_POSCO" 20 "DI_MOTOR_IM216A" 3 "DI_MOTOR_M7M3" 4 "DI_MOTOR_M7M4" 5 "DI_MOTOR_M7M5" 7 "DI_MOTOR_M7M6" 6 "DI_MOTOR_M8A" 16 "DI_MOTOR_PM216A" 18 "DI_MOTOR_PM216B" 21 "DI_MOTOR_PM216C" 30 "DI_MOTOR_PM216CSR" 31 "DI_MOTOR_PM216CSR_N42" 23 "DI_MOTOR_PM216D" 32 "DI_MOTOR_PM228B" 28 "DI_MOTOR_PM275B" 29 "DI_MOTOR_PM350B" 1 "DI_MOTOR_ROADSTER_BASE" 2 "DI_MOTOR_ROADSTER_SPORT" 0 "DI_MOTOR_SNA" 9 "DI_MOTOR_SSR1A" ;
VAL_ 1879 DIF_oilPumpPhaseVoltage 255 "SNA" ;
VAL_ 1879 DIF_oilPumpPressureEstimateMax 255 "SNA" ;
VAL_ 1879 DIF_oilPumpPressureExpectedMin 255 "SNA" ;
VAL_ 1879 DIF_powerStageSafeState 2 "PSTG_SAFESTATE_3PS_HIGH" 3 "PSTG_SAFESTATE_3PS_LOW" 1 "PSTG_SAFESTATE_ALL_OFF" 0 "PSTG_SAFESTATE_NONE" ;
VAL_ 1879 DIF_pwmState 1 "PWMSTATE_DPWM2" 2 "PWMSTATE_OPWM1" 3 "PWMSTATE_OPWM2" 0 "PWMSTATE_SVPWM" ;
VAL_ 1879 DIF_rotorOffsetLearningState 9 "ROL_NUM_STATES" 2 "ROL_STATE_ACCELERATE" 5 "ROL_STATE_CORRECT" 8 "ROL_STATE_DONE" 0 "ROL_STATE_INIT" 4 "ROL_STATE_MEASURE" 3 "ROL_STATE_SHIFT" 6 "ROL_STATE_VERIFY" 1 "ROL_STATE_WAIT" 7 "ROL_STATE_WRITE" ;
VAL_ 1879 DIF_ssmState 5 "SSM_STATE_ABORT" 4 "SSM_STATE_ENABLE" 8 "SSM_STATE_FAULT" 2 "SSM_STATE_IDLE" 7 "SSM_STATE_RETRY" 3 "SSM_STATE_STANDBY" 0 "SSM_STATE_START" 1 "SSM_STATE_UNAVAILABLE" 6 "SSM_STATE_WAIT_FOR_RETRY" ;
VAL_ 1879 DIF_tcMaxRequest 255 "SNA" ;
VAL_ 1879 DIF_tcMinRequest 255 "SNA" ;
VAL_ 1879 DIF_usmState 3 "USM_STATE_ABORT" 4 "USM_STATE_ENABLE" 5 "USM_STATE_FAULT" 2 "USM_STATE_RETRY" 1 "USM_STATE_STANDBY" 0 "USM_STATE_START" 6 "USM_STATE_UNAVAILABLE" 7 "USM_STATE_WAIT_FOR_RETRY" ;
VAL_ 1880 DI_dynoSelector 0 "Mux0" 1 "Mux1" 2 "Mux2" 32 "Mux32" 33 "Mux33" 64 "Mux64";
VAL_ 1880 DI_state 0 "UNAVAILABLE" 1 "STANDBY" 2 "FAULT" 3 "ABORT" 4 "ENABLE";
VAL_ 1885 CP_sensorDataSelect 2 "CP_SENSOR_DOOR" 0 "CP_SENSOR_DOOR_COUNTS" 4 "CP_SENSOR_INDUCTIVE_DOOR" 12 "CP_SENSOR_INLET_HARNESS_ID" 3 "CP_SENSOR_LATCH" 9 "CP_SENSOR_PILOT" 10 "CP_SENSOR_PILOT2" 1 "CP_SENSOR_PIN_TEMP" 8 "CP_SENSOR_PROX" 11 "CP_SENSOR_PROX_GB" 7 "CP_SENSOR_RAILS" 5 "CP_SENSOR_SAFETY" 6 "CP_SENSOR_UHF" ;
VAL_ 1885 CP_inlet1HarnessIdState 1 "HARNESS_PEDIGREE_INVALID" 0 "HARNESS_PEDIGREE_UNKNOWN_SNA" 2 "HARNESS_PEDIGREE_VALID" ;
VAL_ 1885 CP_inlet2HarnessIdState 1 "HARNESS_PEDIGREE_INVALID" 0 "HARNESS_PEDIGREE_UNKNOWN_SNA" 2 "HARNESS_PEDIGREE_VALID" ;
VAL_ 1898 HVP_ecuLogUploadRequest 0 "NONE" 1 "1" 2 "2" 3 "3";
VAL_ 1898 HVP_vehicleDebugMultiplexer 0 "Mux0" 1 "Mux1" 2 "Mux2";
VAL_ 1962 HVP_debugMessageMultiplexer 0 "Mux0" 1 "Mux1" 10 "Mux10" 11 "Mux11" 12 "Mux12" 2 "Mux2" 3 "Mux3" 4 "Mux4" 5 "Mux5" 6 "Mux6" 7 "Mux7" 8 "Mux8" 9 "Mux9" ;
VAL_ 1962 HVP_ecuLogUploadRequest 1 "REQUEST_PRIORITY_1" 2 "REQUEST_PRIORITY_2" 3 "REQUEST_PRIORITY_3" 0 "REQUEST_PRIORITY_NONE" ;
VAL_ 1992 EPBL_infoIndex 0 "DEPRECATED_0" 1 "DEPRECATED_1" 2 "DEPRECATED_2" 3 "DEPRECATED_3" 4 "DEPRECATED_4" 5 "DEPRECATED_5" 6 "DEPRECATED_6" 7 "DEPRECATED_7" 8 "DEPRECATED_8" 9 "DEPRECATED_9" 10 "BUILD_HWID_COMPONENTID" 11 "PCBAID_ASSYID_USAGEID" 13 "APP_CRC" 14 "BOOTLOADER_SVN" 15 "BOOTLOADER_CRC" 16 "SUBCOMPONENT1" 17 "APP_GITHASH" 18 "BOOTLOADER_GITHASH" 19 "VERSION_DEPRECATED" 20 "UDS_PROTOCOL_BOOTCRC" 23 "SUBCOMPONENT2" 24 "SUBCOMPONENT3" 31 "SUBCOMPONENT4" 255 "END";
VAL_ 1992 EPBL_infoBuildType 0 "UNKNOWN_BUILD" 1 "PLATFORM_BUILD" 2 "LOCAL_BUILD" 3 "TRACEABLE_CI_BUILD" 4 "MFG_BUILD";
VAL_ 1992 EPBL_infoAssemblyId 1 "ASSEMBLY1" 255 "ASSEMBLY_SNA";
VAL_ 2005 DIR_fluxState 5 "DI_FLUXSTATE_ENABLED" 9 "DI_FLUXSTATE_FAULT" 4 "DI_FLUXSTATE_FLUX_DOWN" 3 "DI_FLUXSTATE_FLUX_UP" 6 "DI_FLUXSTATE_ICONTROL" 2 "DI_FLUXSTATE_STANDBY" 0 "DI_FLUXSTATE_START" 10 "DI_FLUXSTATE_STATIONARY_WASTE" 1 "DI_FLUXSTATE_TEST" 7 "DI_FLUXSTATE_VCONTROL" ;
VAL_ 2005 DIR_gateDriveState 3 "PSTG_GD_STATE_CONFIGURED" 2 "PSTG_GD_STATE_CONFIGURING" 0 "PSTG_GD_STATE_INIT" 4 "PSTG_GD_STATE_NOT_CONFIGURED" 1 "PSTG_GD_STATE_SELFTEST" ;
VAL_ 2005 DIR_gateDriveSupplyState 0 "PSTG_GD_SUPPLY_DOWN" 3 "PSTG_GD_SUPPLY_FALLING" 1 "PSTG_GD_SUPPLY_RISING" 2 "PSTG_GD_SUPPLY_UP" ;
VAL_ 2005 DIR_magnetTempEst 0 "SNA" ;
VAL_ 2005 DIR_motorType 8 "DI_MOTOR_F1A" 10 "DI_MOTOR_F1AC" 11 "DI_MOTOR_F2AB" 12 "DI_MOTOR_F2AC" 13 "DI_MOTOR_F2AD" 14 "DI_MOTOR_F2AE" 26 "DI_MOTOR_F2AE_AL" 15 "DI_MOTOR_F2APMSRM" 17 "DI_MOTOR_IM100A" 19 "DI_MOTOR_IM100B" 22 "DI_MOTOR_IM130C" 24 "DI_MOTOR_IM130D" 25 "DI_MOTOR_IM130D_AL" 27 "DI_MOTOR_IM130D_AL_POSCO" 20 "DI_MOTOR_IM216A" 3 "DI_MOTOR_M7M3" 4 "DI_MOTOR_M7M4" 5 "DI_MOTOR_M7M5" 7 "DI_MOTOR_M7M6" 6 "DI_MOTOR_M8A" 16 "DI_MOTOR_PM216A" 18 "DI_MOTOR_PM216B" 21 "DI_MOTOR_PM216C" 30 "DI_MOTOR_PM216CSR" 31 "DI_MOTOR_PM216CSR_N42" 23 "DI_MOTOR_PM216D" 32 "DI_MOTOR_PM228B" 28 "DI_MOTOR_PM275B" 29 "DI_MOTOR_PM350B" 1 "DI_MOTOR_ROADSTER_BASE" 2 "DI_MOTOR_ROADSTER_SPORT" 0 "DI_MOTOR_SNA" 9 "DI_MOTOR_SSR1A" ;
VAL_ 2005 DIR_oilPumpPhaseVoltage 255 "SNA" ;
VAL_ 2005 DIR_oilPumpPressureEstimateMax 255 "SNA" ;
VAL_ 2005 DIR_oilPumpPressureExpectedMin 255 "SNA" ;
VAL_ 2005 DIR_powerStageSafeState 2 "PSTG_SAFESTATE_3PS_HIGH" 3 "PSTG_SAFESTATE_3PS_LOW" 1 "PSTG_SAFESTATE_ALL_OFF" 0 "PSTG_SAFESTATE_NONE" ;
VAL_ 2005 DIR_pwmState 1 "PWMSTATE_DPWM2" 2 "PWMSTATE_OPWM1" 3 "PWMSTATE_OPWM2" 0 "PWMSTATE_SVPWM" ;
VAL_ 2005 DIR_rotorOffsetLearningState 9 "ROL_NUM_STATES" 2 "ROL_STATE_ACCELERATE" 5 "ROL_STATE_CORRECT" 8 "ROL_STATE_DONE" 0 "ROL_STATE_INIT" 4 "ROL_STATE_MEASURE" 3 "ROL_STATE_SHIFT" 6 "ROL_STATE_VERIFY" 1 "ROL_STATE_WAIT" 7 "ROL_STATE_WRITE" ;
VAL_ 2005 DIR_ssmState 5 "SSM_STATE_ABORT" 4 "SSM_STATE_ENABLE" 8 "SSM_STATE_FAULT" 2 "SSM_STATE_IDLE" 7 "SSM_STATE_RETRY" 3 "SSM_STATE_STANDBY" 0 "SSM_STATE_START" 1 "SSM_STATE_UNAVAILABLE" 6 "SSM_STATE_WAIT_FOR_RETRY" ;
VAL_ 2005 DIR_tcMaxRequest 255 "SNA" ;
VAL_ 2005 DIR_tcMinRequest 255 "SNA" ;
VAL_ 2005 DIR_usmState 3 "USM_STATE_ABORT" 4 "USM_STATE_ENABLE" 5 "USM_STATE_FAULT" 2 "USM_STATE_RETRY" 1 "USM_STATE_STANDBY" 0 "USM_STATE_START" 6 "USM_STATE_UNAVAILABLE" 7 "USM_STATE_WAIT_FOR_RETRY" ;
VAL_ 2024 EPBR_infoIndex 0 "DEPRECATED_0" 1 "DEPRECATED_1" 2 "DEPRECATED_2" 3 "DEPRECATED_3" 4 "DEPRECATED_4" 5 "DEPRECATED_5" 6 "DEPRECATED_6" 7 "DEPRECATED_7" 8 "DEPRECATED_8" 9 "DEPRECATED_9" 10 "BUILD_HWID_COMPONENTID" 11 "PCBAID_ASSYID_USAGEID" 13 "APP_CRC" 14 "BOOTLOADER_SVN" 15 "BOOTLOADER_CRC" 16 "SUBCOMPONENT1" 17 "APP_GITHASH" 18 "BOOTLOADER_GITHASH" 19 "VERSION_DEPRECATED" 20 "UDS_PROTOCOL_BOOTCRC" 23 "SUBCOMPONENT2" 24 "SUBCOMPONENT3" 31 "SUBCOMPONENT4" 255 "END";
VAL_ 2024 EPBR_infoBuildType 0 "UNKNOWN_BUILD" 1 "PLATFORM_BUILD" 2 "LOCAL_BUILD" 3 "TRACEABLE_CI_BUILD" 4 "MFG_BUILD";
VAL_ 2024 EPBR_infoAssemblyId 1 "ASSEMBLY1" 255 "ASSEMBLY_SNA";
VAL_ 2033 GTW_hrlIndex 1 "Mux1" 2 "Mux2";
VAL_ 2033 GTW_hrlState 0 "DISABLED" 1 "ENABLED";
VAL_ 2033 GTW_hrlTriggerType 0 "UDPAPI" 1 "EVENT" 15 "NONE";
VAL_ 2033 GTW_hrlTriggerBus 0 "VEH" 1 "PARTY" 2 "CH" 3 "VEH" 4 "VIRT";
VAL_ 2047 GTW_activeHighBeam 1 "ACTIVE" 0 "NOT_ACTIVE" ;
VAL_ 2047 GTW_airSuspension 0 "NONE" 2 "TESLA_ADAPTIVE" 1 "TESLA_STANDARD" ;
VAL_ 2047 GTW_airbagCutoffSwitch 0 "CUTOFF_SWITCH_DISABLED" 1 "CUTOFF_SWITCH_ENABLED" ;
VAL_ 2047 GTW_audioType 0 "BASE" 2 "BASE_WITH_PREMIUM200" 1 "PREMIUM" ;
VAL_ 2047 GTW_autopilot 4 "BASIC" 2 "ENHANCED" 1 "HIGHWAY" 0 "NONE" 3 "SELF_DRIVING" ;
VAL_ 2047 GTW_autopilotCameraType 0 "RCCB_CAMERAS" ;
VAL_ 2047 GTW_auxParkLamps 2 "EU" 0 "NA_BASE" 1 "NA_PREMIUM" 3 "NONE" ;
VAL_ 2047 GTW_bPillarNFCParam 0 "MODEL_3" 1 "MODEL_Y" ;
VAL_ 2047 GTW_brakeHWType 1 "BREMBO_LARGE_P42_BREMBO_44MOC" 3 "BREMBO_LARGE_P42_BREMBO_LARGE_44MOC" 2 "BREMBO_LARGE_P42_MANDO_43MOC" 0 "BREMBO_P42_MANDO_43MOC" ;
VAL_ 2047 GTW_brakeLineSwitchType 0 "DI_VC_SHARED" 1 "VC_ONLY" ;
VAL_ 2047 GTW_cabinPTCHeaterType 0 "BORGWARNER" 1 "NONE" ;
VAL_ 2047 GTW_chassisType 2 "MODEL_3_CHASSIS" 0 "MODEL_S_CHASSIS" 1 "MODEL_X_CHASSIS" 3 "MODEL_Y_CHASSIS" ;
VAL_ 2047 GTW_compressorType 2 "DENSO_41CC_11K" 1 "DENSO_41CC_8K" 0 "HANON_33CC" ;
VAL_ 2047 GTW_connectivityPackage 0 "BASE" 1 "PREMIUM" ;
VAL_ 2047 GTW_coolantPumpType 0 "DUAL" 1 "SINGLE_PUMP_BATT" ;
VAL_ 2047 GTW_dasHw 3 "PARKER_PASCAL_2_5" 4 "TESLA_AP3" ;
VAL_ 2047 GTW_deliveryStatus 1 "DELIVERED" 0 "NOT_DELIVERED" ;
VAL_ 2047 GTW_drivetrainType 1 "AWD" 0 "RWD" ;
VAL_ 2047 GTW_eBuckConfig 1 "DEV_BUCK" 0 "NONE" ;
VAL_ 2047 GTW_eCallEnabled 0 "DISABLED" 1 "ENABLED_OHC_SOS" 2 "ENABLED_UI_SOS" ;
VAL_ 2047 GTW_efficiencyPackage 0 "DEFAULT" 2 "M3_LR_2020" 3 "M3_LR_PERFORMANCE_2020" 1 "M3_SR_PLUS_2020" ;
VAL_ 2047 GTW_epasType 0 "MANDO_VGR69_GEN3" ;
VAL_ 2047 GTW_espValveType 0 "UNKNOWN" 1 "VALVE_TYPE_1" 2 "VALVE_TYPE_2" ;
VAL_ 2047 GTW_exteriorColor 5 "DEEP_BLUE" 3 "MIDNIGHT_SILVER" 6 "PEARL_WHITE" 0 "RED_MULTICOAT" 2 "SILVER_METALLIC" 1 "SOLID_BLACK" ;
VAL_ 2047 GTW_frontFogLamps 1 "INSTALLED" 0 "NOT_INSTALLED" ;
VAL_ 2047 GTW_frontSeatHeaters 1 "KONGSBERG_LOW_POWER" 0 "NONE" ;
VAL_ 2047 GTW_frontSeatReclinerHardware 3 "LEFT_RIGHT_SEAT_REDUCED_RANGE" 2 "LEFT_SEAT_REDUCED_RANGE" 1 "RIGHT_SEAT_REDUCED_RANGE" 0 "STANDARD_RANGE" ;
VAL_ 2047 GTW_frontSeatType 0 "BASE_TESLA" 3 "PREMIUM_L_TESLA_R_YANFENG" 2 "PREMIUM_L_YANFENG_R_TESLA" 1 "PREMIUM_TESLA" 4 "PREMIUM_YANFENG" ;
VAL_ 2047 GTW_headlamps 0 "BASE" 1 "PREMIUM" ;
VAL_ 2047 GTW_headlightLevelerType 1 "GEN1" 0 "NONE" ;
VAL_ 2047 GTW_homelinkType 1 "HOMELINK_V_OPT_2" 0 "NONE" ;
VAL_ 2047 GTW_hvacPanelVaneType 1 "CONVERGENT_V1" 0 "PARALLEL_V1" ;
VAL_ 2047 GTW_immersiveAudio 1 "BASE" 0 "DISABLED" 2 "PREMIUM" ;
VAL_ 2047 GTW_interiorLighting 0 "BASE" 1 "PREMIUM" 2 "PREMIUM_NO_POCKET_LIGHT" ;
VAL_ 2047 GTW_intrusionSensorType 0 "NOT_INSTALLED" 1 "VODAFONE" ;
VAL_ 2047 GTW_lumbarECUType 1 "ALFMEIER" 0 "NONE" ;
VAL_ 2047 GTW_mapRegion 4 "AU" 3 "CN" 1 "EU" 9 "HK" 5 "JP" 7 "KR" 8 "ME" 10 "MO" 2 "NONE" 6 "TW" 0 "US" ;
VAL_ 2047 GTW_memoryMirrors 0 "NOT_INSTALLED" 1 "SMR" ;
VAL_ 2047 GTW_numberHVILNodes 0 "HVIL_NODES_0" 1 "HVIL_NODES_1" 2 "HVIL_NODES_2" 3 "HVIL_NODES_3" 4 "HVIL_NODES_4" 5 "HVIL_NODES_5" ;
VAL_ 2047 GTW_packEnergy 3 "PACK_100_KWH" 0 "PACK_50_KWH" 2 "PACK_62_KWH" 1 "PACK_74_KWH" 4 "PACK_75_KWH" ;
VAL_ 2047 GTW_passengerAirbagType 2 "EUROW" 0 "FULL_SUPPRESSION" 1 "SAFETY_VENT" ;
VAL_ 2047 GTW_passengerOccupancySensorType 0 "OCS" 1 "RESISTIVE_PAD" ;
VAL_ 2047 GTW_pedestrianWarningSound 0 "NONE" 1 "SPEAKER" ;
VAL_ 2047 GTW_performancePackage 0 "BASE" 3 "BASE_PLUS" 4 "BASE_PLUS_AWD" 2 "LUDICROUS" 1 "PERFORMANCE" ;
VAL_ 2047 GTW_plcSupportType 2 "NATIVE_CHARGE_PORT" 0 "NONE" 1 "ONBOARD_ADAPTER" ;
VAL_ 2047 GTW_powerSteeringColumn 0 "NOT_INSTALLED" 1 "TK" ;
VAL_ 2047 GTW_radarHeaterType 1 "BECKER_THIN_3M" 0 "NONE" ;
VAL_ 2047 GTW_rearFogLamps 1 "INSTALLED" 0 "NOT_INSTALLED" ;
VAL_ 2047 GTW_rearGlassType 0 "NX" 1 "TSA5_NOPET" ;
VAL_ 2047 GTW_rearLightType 1 "EU_CN" 2 "GLOBAL" 0 "NA" ;
VAL_ 2047 GTW_rearSeatHeaters 1 "KONGSBERG_LOW_POWER" 0 "NONE" ;
VAL_ 2047 GTW_refrigerantType 0 "Default" 2 "R1234YF" 1 "R134A" ;
VAL_ 2047 GTW_restraintsHardwareType 22 "EUROW_ECALL_M3" 33 "EUROW_ECALL_MY" 23 "EUROW_NO_ECALL_M3" 34 "EUROW_NO_ECALL_MY" 21 "NA_M3" 32 "NA_MY" 31 "NA_MY_OLD" ;
VAL_ 2047 GTW_rightHandDrive 0 "LEFT" 1 "RIGHT" ;
VAL_ 2047 GTW_roofGlassType 0 "TSA3_PET" 1 "TSA5_NOPET" ;
VAL_ 2047 GTW_roofType 1 "FIXED_GLASS" 0 "METAL" 2 "PANORAMIC" ;
VAL_ 2047 GTW_softRange 1 "RANGE_220_MILES" 2 "RANGE_93_MILES" 0 "STANDARD" ;
VAL_ 2047 GTW_spoilerType 0 "NOT_INSTALLED" 1 "PASSIVE" ;
VAL_ 2047 GTW_steeringColumnMotorType 0 "BOSCH" 1 "JE" ;
VAL_ 2047 GTW_steeringColumnUJointType 0 "B_SAMPLE_PHASING" 1 "C_SAMPLE_PHASING" ;
VAL_ 2047 GTW_superchargingAccess 1 "ALLOWED" 0 "NOT_ALLOWED" 2 "PAY_AS_YOU_GO" ;
VAL_ 2047 GTW_tireType 4 "CONTI_ALL_SEASON_19" 17 "GOODYEAR_ALL_SEASON_20" 3 "HANKOOK_SUMMER_19" 1 "MICHELIN_ALL_SEASON_18" 19 "MICHELIN_ALL_SEASON_21" 2 "MICHELIN_SUMMER_18" 5 "MICHELIN_SUMMER_20" 18 "PIRELLI_SUMMER_21" 0 "UNKNOWN" ;
VAL_ 2047 GTW_towPackage 0 "NONE" 1 "TESLA_REV1" ;
VAL_ 2047 GTW_tpmsType 0 "CONTI_2" 1 "TESLA_BLE" ;
VAL_ 2047 GTW_twelveVBatteryType 0 "ATLASBX_B24_FLOODED" 1 "CLARIOS_B24_FLOODED" ;
VAL_ 2047 GTW_vdcType 0 "BOSCH_VDC" 1 "TESLA_VDC" ;
VAL_ 2047 GTW_wheelType 4 "GEMINI_19_SQUARE" 5 "GEMINI_19_STAGGERED" 0 "PINWHEEL_18" 18 "PINWHEEL_18_CAP_KIT" 1 "STILETTO_19" 2 "STILETTO_20" 14 "STILETTO_20_DARK_SQUARE" 3 "STILETTO_20_DARK_STAGGERED" 19 "ZEROG_20_GUNPOWDER" 17 "APOLLO_19_SILVER" 20 "APOLLO_19_SILVER_CAP_KIT" 15 "INDUCTION_20_BLACK" 16 "UBERTURBINE_21_BLACK" ;
VAL_ 2047 GTW_windshieldType 1 "EASTMAN_ACOUSTIC" 0 "SEKISUI_ACOUSTIC" ;
VAL_ 2047 GTW_xcpESP 0 "FALSE" 1 "TRUE" ;
VAL_ 2047 GTW_xcpIbst 0 "FALSE" 1 "TRUE" ;
CM_ BO_ 1013 "source: joshwardell/model3dbc (Model3CAN.dbc)";
CM_ BO_ 1014 "source: talas9/tesla_can_signals (ModelY_ETH.compact.json)";
CM_ BO_ 1016 "source: joshwardell/model3dbc (Model3CAN.dbc)";
CM_ BO_ 1017 "source: onyx-m2/onyx-m2-dbc (tesla_model3.dbc)";
CM_ BO_ 1018 "source: onyx-m2/onyx-m2-dbc (tesla_model3.dbc)";
CM_ BO_ 1020 "source: onyx-m2/onyx-m2-dbc (tesla_model3.dbc)";
CM_ BO_ 1021 "source: joshwardell/model3dbc (Model3CAN.dbc)";
CM_ BO_ 1022 "source: joshwardell/model3dbc (Model3CAN.dbc)";
CM_ BO_ 1025 "source: joshwardell/model3dbc (Model3CAN.dbc)";
CM_ BO_ 1029 "source: joshwardell/model3dbc (Model3CAN.dbc)";
CM_ BO_ 1040 "source: onyx-m2/onyx-m2-dbc (tesla_model3.dbc)";
CM_ BO_ 1056 "source: talas9/tesla_can_signals (ModelY_ETH.compact.json)";
CM_ BO_ 1064 "source: onyx-m2/onyx-m2-dbc (tesla_model3.dbc)";
CM_ BO_ 1065 "source: onyx-m2/onyx-m2-dbc (tesla_model3.dbc)";
CM_ BO_ 1066 "source: joshwardell/model3dbc (Model3CAN.dbc)";
CM_ BO_ 1080 "source: onyx-m2/onyx-m2-dbc (tesla_model3.dbc)";
CM_ BO_ 1081 "source: onyx-m2/onyx-m2-dbc (tesla_model3.dbc)";
CM_ BO_ 1082 "source: onyx-m2/onyx-m2-dbc (tesla_model3.dbc)";
CM_ BO_ 1085 "source: joshwardell/model3dbc (Model3CAN.dbc)";
CM_ BO_ 1096 "source: onyx-m2/onyx-m2-dbc (tesla_model3.dbc)";
CM_ BO_ 1097 "source: onyx-m2/onyx-m2-dbc (tesla_model3.dbc)";
CM_ BO_ 1112 "source: onyx-m2/onyx-m2-dbc (tesla_model3.dbc)";
CM_ BO_ 1113 "source: onyx-m2/onyx-m2-dbc (tesla_model3.dbc)";
CM_ BO_ 1132 "source: onyx-m2/onyx-m2-dbc (tesla_model3.dbc)";
CM_ BO_ 1139 "source: onyx-m2/onyx-m2-dbc (tesla_model3.dbc)";
CM_ BO_ 1152 "source: talas9/tesla_can_signals (ModelY_ETH.compact.json)";
CM_ BO_ 1153 "source: onyx-m2/onyx-m2-dbc (tesla_model3.dbc)";
CM_ BO_ 1160 "source: commaai/opendbc (tesla_model3_party.dbc)";
CM_ BO_ 1170 "source: talas9/tesla_can_signals (ModelY_ETH.compact.json)";
CM_ BO_ 1177 "source: talas9/tesla_can_signals (ModelY_ETH.compact.json)";
CM_ BO_ 1250 "source: talas9/tesla_can_signals (ModelY_ETH.compact.json)";
CM_ BO_ 1251 "source: talas9/tesla_can_signals (ModelY_ETH.compact.json)";
CM_ BO_ 1280 "source: onyx-m2/onyx-m2-dbc (tesla_model3.dbc)";
CM_ BO_ 1282 "source: onyx-m2/onyx-m2-dbc (tesla_model3.dbc)";
CM_ BO_ 1303 "source: onyx-m2/onyx-m2-dbc (tesla_model3.dbc)";
CM_ BO_ 1310 "source: joshwardell/model3dbc (Model3CAN.dbc)";
CM_ BO_ 1320 "source: joshwardell/model3dbc (Model3CAN.dbc)";
CM_ BO_ 1323 "source: onyx-m2/onyx-m2-dbc (tesla_model3.dbc)";
CM_ BO_ 1329 "source: onyx-m2/onyx-m2-dbc (tesla_model3.dbc)";
CM_ BO_ 1337 "source: onyx-m2/onyx-m2-dbc (tesla_model3.dbc)";
CM_ BO_ 1342 "source: onyx-m2/onyx-m2-dbc (tesla_model3.dbc)";
CM_ BO_ 1345 "source: joshwardell/model3dbc (Model3CAN.dbc)";
CM_ BO_ 1353 "source: onyx-m2/onyx-m2-dbc (tesla_model3.dbc)";
CM_ BO_ 1355 "source: onyx-m2/onyx-m2-dbc (tesla_model3.dbc)";
CM_ BO_ 1357 "source: onyx-m2/onyx-m2-dbc (tesla_model3.dbc)";
CM_ BO_ 1359 "source: onyx-m2/onyx-m2-dbc (tesla_model3.dbc)";
CM_ BO_ 1366 "source: joshwardell/model3dbc (Model3CAN.dbc)";
CM_ BO_ 1367 "source: joshwardell/model3dbc (Model3CAN.dbc)";
CM_ BO_ 1376 "source: talas9/tesla_can_signals (ModelY_ETH.compact.json)";
CM_ BO_ 1493 "source: joshwardell/model3dbc (Model3CAN.dbc)";
CM_ BO_ 1495 "source: joshwardell/model3dbc (Model3CAN.dbc)";
CM_ BO_ 1519 "source: onyx-m2/onyx-m2-dbc (tesla_model3.dbc)";
CM_ BO_ 1523 "source: onyx-m2/onyx-m2-dbc (tesla_model3.dbc)";
CM_ BO_ 1536 "source: talas9/tesla_can_signals (ModelY_ETH.compact.json)";
CM_ BO_ 1537 "source: talas9/tesla_can_signals (ModelY_ETH.compact.json)";
CM_ BO_ 1538 "source: talas9/tesla_can_signals (ModelY_ETH.compact.json)";
CM_ BO_ 1539 "source: talas9/tesla_can_signals (ModelY_ETH.compact.json)";
CM_ BO_ 1540 "source: talas9/tesla_can_signals (ModelY_ETH.compact.json)";
CM_ BO_ 1541 "source: talas9/tesla_can_signals (ModelY_ETH.compact.json)";
CM_ BO_ 1542 "source: talas9/tesla_can_signals (ModelY_ETH.compact.json)";
CM_ BO_ 1543 "source: talas9/tesla_can_signals (ModelY_ETH.compact.json)";
CM_ BO_ 1544 "source: talas9/tesla_can_signals (ModelY_ETH.compact.json)";
CM_ BO_ 1545 "source: talas9/tesla_can_signals (ModelY_ETH.compact.json)";
CM_ BO_ 1546 "source: talas9/tesla_can_signals (ModelY_ETH.compact.json)";
CM_ BO_ 1547 "source: talas9/tesla_can_signals (ModelY_ETH.compact.json)";
CM_ BO_ 1548 "source: onyx-m2/onyx-m2-dbc (tesla_model3.dbc)";
CM_ BO_ 1550 "source: talas9/tesla_can_signals (ModelY_ETH.compact.json)";
CM_ BO_ 1551 "source: talas9/tesla_can_signals (ModelY_ETH.compact.json)";
CM_ BO_ 1552 "source: talas9/tesla_can_signals (ModelY_ETH.compact.json)";
CM_ BO_ 1553 "source: talas9/tesla_can_signals (ModelY_ETH.compact.json)";
CM_ BO_ 1554 "source: talas9/tesla_can_signals (ModelY_ETH.compact.json)";
CM_ BO_ 1555 "source: talas9/tesla_can_signals (ModelY_ETH.compact.json)";
CM_ BO_ 1556 "source: talas9/tesla_can_signals (ModelY_ETH.compact.json)";
CM_ BO_ 1557 "source: talas9/tesla_can_signals (ModelY_ETH.compact.json)";
CM_ BO_ 1558 "source: talas9/tesla_can_signals (ModelY_ETH.compact.json)";
CM_ BO_ 1559 "source: talas9/tesla_can_signals (ModelY_ETH.compact.json)";
CM_ BO_ 1560 "source: talas9/tesla_can_signals (ModelY_ETH.compact.json)";
CM_ BO_ 1566 "source: talas9/tesla_can_signals (ModelY_ETH.compact.json)";
CM_ BO_ 1568 "source: talas9/tesla_can_signals (ModelY_ETH.compact.json)";
CM_ BO_ 1570 "source: talas9/tesla_can_signals (ModelY_ETH.compact.json)";
CM_ BO_ 1571 "source: talas9/tesla_can_signals (ModelY_ETH.compact.json)";
CM_ BO_ 1572 "source: talas9/tesla_can_signals (ModelY_ETH.compact.json)";
CM_ BO_ 1573 "source: talas9/tesla_can_signals (ModelY_ETH.compact.json)";
CM_ BO_ 1574 "source: talas9/tesla_can_signals (ModelY_ETH.compact.json)";
CM_ BO_ 1575 "source: talas9/tesla_can_signals (ModelY_ETH.compact.json)";
CM_ BO_ 1576 "source: talas9/tesla_can_signals (ModelY_ETH.compact.json)";
CM_ BO_ 1577 "source: talas9/tesla_can_signals (ModelY_ETH.compact.json)";
CM_ BO_ 1579 "source: talas9/tesla_can_signals (ModelY_ETH.compact.json)";
CM_ BO_ 1584 "source: talas9/tesla_can_signals (ModelY_ETH.compact.json)";
CM_ BO_ 1589 "source: talas9/tesla_can_signals (ModelY_ETH.compact.json)";
CM_ BO_ 1592 "source: talas9/tesla_can_signals (ModelY_ETH.compact.json)";
CM_ BO_ 1600 "source: talas9/tesla_can_signals (ModelY_ETH.compact.json)";
CM_ BO_ 1601 "source: talas9/tesla_can_signals (ModelY_ETH.compact.json)";
CM_ BO_ 1603 "source: talas9/tesla_can_signals (ModelY_ETH.compact.json)";
CM_ BO_ 1604 "source: talas9/tesla_can_signals (ModelY_ETH.compact.json)";
CM_ BO_ 1605 "source: talas9/tesla_can_signals (ModelY_ETH.compact.json)";
CM_ BO_ 1609 "source: talas9/tesla_can_signals (ModelY_ETH.compact.json)";
CM_ BO_ 1611 "source: talas9/tesla_can_signals (ModelY_ETH.compact.json)";
CM_ BO_ 1613 "source: talas9/tesla_can_signals (ModelY_ETH.compact.json)";
CM_ BO_ 1614 "source: talas9/tesla_can_signals (ModelY_ETH.compact.json)";
CM_ BO_ 1615 "source: talas9/tesla_can_signals (ModelY_ETH.compact.json)";
CM_ BO_ 1617 "source: talas9/tesla_can_signals (ModelY_ETH.compact.json)";
CM_ BO_ 1619 "source: talas9/tesla_can_signals (ModelY_ETH.compact.json)";
CM_ BO_ 1620 "source: talas9/tesla_can_signals (ModelY_ETH.compact.json)";
CM_ BO_ 1621 "source: talas9/tesla_can_signals (ModelY_ETH.compact.json)";
CM_ BO_ 1622 "source: joshwardell/model3dbc (Model3CAN.dbc)";
CM_ BO_ 1624 "source: talas9/tesla_can_signals (ModelY_ETH.compact.json)";
CM_ BO_ 1625 "source: talas9/tesla_can_signals (ModelY_ETH.compact.json)";
CM_ BO_ 1627 "source: talas9/tesla_can_signals (ModelY_ETH.compact.json)";
CM_ BO_ 1629 "source: talas9/tesla_can_signals (ModelY_ETH.compact.json)";
CM_ BO_ 1630 "source: talas9/tesla_can_signals (ModelY_ETH.compact.json)";
CM_ BO_ 1631 "source: talas9/tesla_can_signals (ModelY_ETH.compact.json)";
CM_ BO_ 1634 "source: talas9/tesla_can_signals (ModelY_ETH.compact.json)";
CM_ BO_ 1635 "source: talas9/tesla_can_signals (ModelY_ETH.compact.json)";
CM_ BO_ 1638 "source: talas9/tesla_can_signals (ModelY_ETH.compact.json)";
CM_ BO_ 1641 "source: talas9/tesla_can_signals (ModelY_ETH.compact.json)";
CM_ BO_ 1649 "source: talas9/tesla_can_signals (ModelY_ETH.compact.json)";
CM_ BO_ 1655 "source: talas9/tesla_can_signals (ModelY_ETH.compact.json)";
CM_ BO_ 1664 "source: talas9/tesla_can_signals (ModelY_ETH.compact.json)";
CM_ BO_ 1665 "source: talas9/tesla_can_signals (ModelY_ETH.compact.json)";
CM_ BO_ 1666 "source: talas9/tesla_can_signals (ModelY_ETH.compact.json)";
CM_ BO_ 1680 "source: talas9/tesla_can_signals (ModelY_ETH.compact.json)";
CM_ BO_ 1723 "source: talas9/tesla_can_signals (ModelY_ETH.compact.json)";
CM_ BO_ 1734 "source: talas9/tesla_can_signals (ModelY_ETH.compact.json)";
CM_ BO_ 1748 "source: onyx-m2/onyx-m2-dbc (tesla_model3.dbc)";
CM_ BO_ 1750 "source: talas9/tesla_can_signals (ModelY_ETH.compact.json)";
CM_ BO_ 1787 "source: talas9/tesla_can_signals (ModelY_ETH.compact.json)";
CM_ BO_ 1795 "source: onyx-m2/onyx-m2-dbc (tesla_model3.dbc)";
CM_ BO_ 1816 "source: talas9/tesla_can_signals (ModelY_ETH.compact.json)";
CM_ BO_ 1834 "source: joshwardell/model3dbc (Model3CAN.dbc)";
CM_ BO_ 1840 "source: talas9/tesla_can_signals (ModelY_ETH.compact.json)";
CM_ BO_ 1848 "source: talas9/tesla_can_signals (ModelY_ETH.compact.json)";
CM_ BO_ 1859 "source: joshwardell/model3dbc (Model3CAN.dbc)";
CM_ BO_ 1860 "source: onyx-m2/onyx-m2-dbc (tesla_model3.dbc)";
CM_ BO_ 1879 "source: joshwardell/model3dbc (Model3CAN.dbc)";
CM_ BO_ 1880 "source: onyx-m2/onyx-m2-dbc (tesla_model3.dbc)";
CM_ BO_ 1885 "source: joshwardell/model3dbc (Model3CAN.dbc)";
CM_ BO_ 1898 "source: onyx-m2/onyx-m2-dbc (tesla_model3.dbc)";
CM_ BO_ 1962 "source: talas9/tesla_can_signals (ModelY_ETH.compact.json)";
CM_ BO_ 1992 "source: onyx-m2/onyx-m2-dbc (tesla_model3.dbc)";
CM_ BO_ 2005 "source: joshwardell/model3dbc (Model3CAN.dbc)";
CM_ BO_ 2014 "source: talas9/tesla_can_signals (ModelY_ETH.compact.json)";
CM_ BO_ 2015 "source: talas9/tesla_can_signals (ModelY_ETH.compact.json)";
CM_ BO_ 2024 "source: onyx-m2/onyx-m2-dbc (tesla_model3.dbc)";
CM_ BO_ 2033 "source: onyx-m2/onyx-m2-dbc (tesla_model3.dbc)";
CM_ BO_ 2047 "source: joshwardell/model3dbc (Model3CAN.dbc)";
